VERSION ""

NS_ :

BS_:

BU_: ADSP CH ChassisBus DIPF DIPR ETH FC GTW GTWU HVI HVS ODIN PARTY PartyBus Receiver SDCV SUI UI UIS VEH VIRT VITALS VehicleBus X

BO_ 880 SCS_alertMatrix2: 8 CH
 SG_ SCS_a065_vBatRationalityStage1: 0|1@1+ (1,0) [0|0] "" X
 SG_ SCS_a066_vBatRationalityStage2: 1|1@1+ (1,0) [0|0] "" X
 SG_ SCS_a067_vBatRationalityStage3: 2|1@1+ (1,0) [0|0] "" X
 SG_ SCS_a068_vBatRationalityStage4: 3|1@1+ (1,0) [0|0] "" X
 SG_ SCS_a069_vStageRationalityV1: 4|1@1+ (1,0) [0|0] "" X
 SG_ SCS_a070_vStageRationalityV2: 5|1@1+ (1,0) [0|0] "" X
 SG_ SCS_a071_chargerMIA: 6|1@1+ (1,0) [0|0] "" X
 SG_ SCS_a072_gtwMIA: 7|1@1+ (1,0) [0|0] "" X
 SG_ SCS_a073_lccMIA: 8|1@1+ (1,0) [0|0] "" X
 SG_ SCS_a074_isoVDiffHi: 9|1@1+ (1,0) [0|0] "" X
 SG_ SCS_a075_leakageTestAbsDecayLow: 10|1@1+ (1,0) [0|0] "" X
 SG_ SCS_a076_bmsMIA: 11|1@1+ (1,0) [0|0] "" X
 SG_ SCS_a077_unexpectedVbatBehavior: 12|1@1+ (1,0) [0|0] "" X
 SG_ SCS_a078_voltageMatchTimeout: 13|1@1+ (1,0) [0|0] "" X
 SG_ SCS_a079_unexpectedVbat: 14|1@1+ (1,0) [0|0] "" X
 SG_ SCS_a080_lccFaulted: 15|1@1+ (1,0) [0|0] "" X
 SG_ SCS_a081_rmsInputVoltageHigh: 16|1@1+ (1,0) [0|0] "" X
 SG_ SCS_a082_VbatUV: 17|1@1+ (1,0) [0|0] "" X
 SG_ SCS_a083_chargeCurrentLimited: 18|1@1+ (1,0) [0|0] "" X
 SG_ SCS_a084_unused84: 19|1@1+ (1,0) [0|0] "" X
 SG_ SCS_a085_unused85: 20|1@1+ (1,0) [0|0] "" X
 SG_ SCS_a086_lccResetDetected: 21|1@1+ (1,0) [0|0] "" X
 SG_ SCS_a087_posCordTempRationality: 22|1@1+ (1,0) [0|0] "" X
 SG_ SCS_a088_negCordTempRationality: 23|1@1+ (1,0) [0|0] "" X
 SG_ SCS_a089_posCordOT: 24|1@1+ (1,0) [0|0] "" X
 SG_ SCS_a090_negCordOT: 25|1@1+ (1,0) [0|0] "" X
 SG_ SCS_a091_voltageRiseDetection: 26|1@1+ (1,0) [0|0] "" X
 SG_ SCS_a092_cabEnableDeasserted: 27|1@1+ (1,0) [0|0] "" X
 SG_ SCS_a093_unused93: 28|1@1+ (1,0) [0|0] "" X
 SG_ SCS_a094_unused94: 29|1@1+ (1,0) [0|0] "" X
 SG_ SCS_a095_unused95: 30|1@1+ (1,0) [0|0] "" X
 SG_ SCS_a096_unused96: 31|1@1+ (1,0) [0|0] "" X
 SG_ SCS_a097_unused97: 32|1@1+ (1,0) [0|0] "" X
 SG_ SCS_a098_unused98: 33|1@1+ (1,0) [0|0] "" X
 SG_ SCS_a099_unused99: 34|1@1+ (1,0) [0|0] "" X
 SG_ SCS_a100_unused100: 35|1@1+ (1,0) [0|0] "" X
 SG_ SCS_a101_unused101: 36|1@1+ (1,0) [0|0] "" X
 SG_ SCS_a102_unused102: 37|1@1+ (1,0) [0|0] "" X
 SG_ SCS_a103_unused103: 38|1@1+ (1,0) [0|0] "" X
 SG_ SCS_a104_unused104: 39|1@1+ (1,0) [0|0] "" X
 SG_ SCS_a105_unused105: 40|1@1+ (1,0) [0|0] "" X
 SG_ SCS_a106_unused106: 41|1@1+ (1,0) [0|0] "" X
 SG_ SCS_a107_unused107: 42|1@1+ (1,0) [0|0] "" X
 SG_ SCS_a108_unused108: 43|1@1+ (1,0) [0|0] "" X
 SG_ SCS_a109_unused109: 44|1@1+ (1,0) [0|0] "" X
 SG_ SCS_a110_unused110: 45|1@1+ (1,0) [0|0] "" X
 SG_ SCS_a111_unused111: 46|1@1+ (1,0) [0|0] "" X
 SG_ SCS_a112_unused112: 47|1@1+ (1,0) [0|0] "" X
 SG_ SCS_a113_unused113: 48|1@1+ (1,0) [0|0] "" X
 SG_ SCS_a114_unused114: 49|1@1+ (1,0) [0|0] "" X
 SG_ SCS_a115_unused115: 50|1@1+ (1,0) [0|0] "" X
 SG_ SCS_a116_unused116: 51|1@1+ (1,0) [0|0] "" X
 SG_ SCS_a117_unused117: 52|1@1+ (1,0) [0|0] "" X
 SG_ SCS_a118_unused118: 53|1@1+ (1,0) [0|0] "" X
 SG_ SCS_a119_unused119: 54|1@1+ (1,0) [0|0] "" X
 SG_ SCS_a120_unused120: 55|1@1+ (1,0) [0|0] "" X
 SG_ SCS_a121_unused121: 56|1@1+ (1,0) [0|0] "" X
 SG_ SCS_a122_unused122: 57|1@1+ (1,0) [0|0] "" X
 SG_ SCS_a123_unused123: 58|1@1+ (1,0) [0|0] "" X
 SG_ SCS_a124_unused124: 59|1@1+ (1,0) [0|0] "" X
 SG_ SCS_a125_unused125: 60|1@1+ (1,0) [0|0] "" X
 SG_ SCS_a126_unused126: 61|1@1+ (1,0) [0|0] "" X
 SG_ SCS_a127_unused127: 62|1@1+ (1,0) [0|0] "" X
 SG_ SCS_a128_unused128: 63|1@1+ (1,0) [0|0] "" X

BO_ 881 RCM_alertMatrix: 8 VEH
 SG_ RCM_matrixIndex M: 0|4@1+ (1,0) [0|0] "" X
 SG_ RCM_a000_crashDetected m0: 4|1@1+ (1,0) [0|0] "" X
 SG_ RCM_a001_nearDeploy m0: 5|1@1+ (1,0) [0|0] "" X
 SG_ RCM_a002_airbagsNotArmed m0: 6|1@1+ (1,0) [0|0] "" X
 SG_ RCM_a003_warningIndicator m0: 7|1@1+ (1,0) [0|0] "" X
 SG_ RCM_a004_internalFault m0: 8|1@1+ (1,0) [0|0] "" X
 SG_ RCM_a005_crcError m0: 9|1@1+ (1,0) [0|0] "" X
 SG_ RCM_a006_batteryVoltageRange m0: 10|1@1+ (1,0) [0|0] "" X
 SG_ RCM_a007_powerSupplyExternal m0: 11|1@1+ (1,0) [0|0] "" X
 SG_ RCM_a008_powerSupplyInternal m0: 12|1@1+ (1,0) [0|0] "" X
 SG_ RCM_a009_reprogramLimit m0: 13|1@1+ (1,0) [0|0] "" X
 SG_ RCM_a010_scmDisabled m0: 14|1@1+ (1,0) [0|0] "" X
 SG_ RCM_a011_eepromDataLocked m0: 15|1@1+ (1,0) [0|0] "" X
 SG_ RCM_a012_vinStorage m0: 16|1@1+ (1,0) [0|0] "" X
 SG_ RCM_a013_driverOrientation m0: 17|1@1+ (1,0) [0|0] "" X
 SG_ RCM_a014_driverABStage1 m0: 18|1@1+ (1,0) [0|0] "" X
 SG_ RCM_a015_driverABStage2 m0: 19|1@1+ (1,0) [0|0] "" X
 SG_ RCM_a016_passABStage1 m0: 20|1@1+ (1,0) [0|0] "" X
 SG_ RCM_a017_passABStage2 m0: 21|1@1+ (1,0) [0|0] "" X
 SG_ RCM_a018_passengerActiveVent m0: 22|1@1+ (1,0) [0|0] "" X
 SG_ RCM_a019_pretenShldrFrontLeft m0: 23|1@1+ (1,0) [0|0] "" X
 SG_ RCM_a020_pretenShldFrontRight m0: 24|1@1+ (1,0) [0|0] "" X
 SG_ RCM_a021_pretenLapFrontLeft m0: 25|1@1+ (1,0) [0|0] "" X
 SG_ RCM_a022_pretenLapFrontRight m0: 26|1@1+ (1,0) [0|0] "" X
 SG_ RCM_a023_loadLimiterLeftSide m0: 27|1@1+ (1,0) [0|0] "" X
 SG_ RCM_a024_loadLimiterRightSide m0: 28|1@1+ (1,0) [0|0] "" X
 SG_ RCM_a025_kneeABDriver m0: 29|1@1+ (1,0) [0|0] "" X
 SG_ RCM_a026_kneeABFrontPassenger m0: 30|1@1+ (1,0) [0|0] "" X
 SG_ RCM_a027_sideAB1stRowLeft m0: 31|1@1+ (1,0) [0|0] "" X
 SG_ RCM_a028_sideAB1stRowRight m0: 32|1@1+ (1,0) [0|0] "" X
 SG_ RCM_a029_driverABActiveVent m0: 33|1@1+ (1,0) [0|0] "" X
 SG_ RCM_a030_farSideInboardAirbag m0: 34|1@1+ (1,0) [0|0] "" X
 SG_ RCM_a031_frontCenterAirbag m0: 35|1@1+ (1,0) [0|0] "" X
 SG_ RCM_a032_curtainABLeft m0: 36|1@1+ (1,0) [0|0] "" X
 SG_ RCM_a033_curtainABRight m0: 37|1@1+ (1,0) [0|0] "" X
 SG_ RCM_a034_preten2ndRowLeft m0: 38|1@1+ (1,0) [0|0] "" X
 SG_ RCM_a035_preten2ndRowRight m0: 39|1@1+ (1,0) [0|0] "" X
 SG_ RCM_a036_curAB2ndRowLeft m0: 40|1@1+ (1,0) [0|0] "" X
 SG_ RCM_a037_curAB2ndRowRight m0: 41|1@1+ (1,0) [0|0] "" X
 SG_ RCM_a038_unusedA m0: 42|1@1+ (1,0) [0|0] "" X
 SG_ RCM_a039_unusedB m0: 43|1@1+ (1,0) [0|0] "" X
 SG_ RCM_a040_hoodActuatorRight m0: 44|1@1+ (1,0) [0|0] "" X
 SG_ RCM_a041_hoodActuatorLeft m0: 45|1@1+ (1,0) [0|0] "" X
 SG_ RCM_a042_ens1Line m0: 46|1@1+ (1,0) [0|0] "" X
 SG_ RCM_a043_ens2Line m0: 47|1@1+ (1,0) [0|0] "" X
 SG_ RCM_a044_upFrontSensorLeft m0: 48|1@1+ (1,0) [0|0] "" X
 SG_ RCM_a045_upFrontSensorRight m0: 49|1@1+ (1,0) [0|0] "" X
 SG_ RCM_a046_sideAccelBPillarLeft m0: 50|1@1+ (1,0) [0|0] "" X
 SG_ RCM_a047_sideAccelBPillarRight m0: 51|1@1+ (1,0) [0|0] "" X
 SG_ RCM_a048_sideAccelCPillarLeft m0: 52|1@1+ (1,0) [0|0] "" X
 SG_ RCM_a049_sideAccelCPillarRight m0: 53|1@1+ (1,0) [0|0] "" X
 SG_ RCM_a050_upFrontSensorCenter m0: 54|1@1+ (1,0) [0|0] "" X
 SG_ RCM_a051_pressureFrontLftDoor m0: 55|1@1+ (1,0) [0|0] "" X
 SG_ RCM_a052_pressureFrontRtDoor m0: 56|1@1+ (1,0) [0|0] "" X
 SG_ RCM_a053_pressurePedProLeft m0: 57|1@1+ (1,0) [0|0] "" X
 SG_ RCM_a054_pressurePedProRight m0: 58|1@1+ (1,0) [0|0] "" X
 SG_ RCM_a055_inertialMeasurement m0: 59|1@1+ (1,0) [0|0] "" X
 SG_ RCM_a056_passengerFrontOCS m0: 60|1@1+ (1,0) [0|0] "" X
 SG_ RCM_a057_driverOCS m0: 61|1@1+ (1,0) [0|0] "" X
 SG_ RCM_a058_buckle1stRowLeft m0: 62|1@1+ (1,0) [0|0] "" X
 SG_ RCM_a059_buckle1stRowRight m0: 63|1@1+ (1,0) [0|0] "" X
 SG_ RCM_a060_stpsLeft m1: 4|1@1+ (1,0) [0|0] "" X
 SG_ RCM_a061_stpsRight m1: 5|1@1+ (1,0) [0|0] "" X
 SG_ RCM_a062_alrSwitch m1: 6|1@1+ (1,0) [0|0] "" X
 SG_ RCM_a063_sbsw2ndRowRight m1: 7|1@1+ (1,0) [0|0] "" X
 SG_ RCM_a064_hardwareCodingPin1 m1: 8|1@1+ (1,0) [0|0] "" X
 SG_ RCM_a065_driverOrientConfigPin m1: 9|1@1+ (1,0) [0|0] "" X
 SG_ RCM_a066_seatBackSw2ndRowLeft m1: 10|1@1+ (1,0) [0|0] "" X
 SG_ RCM_a067_comCANInitFailure m1: 11|1@1+ (1,0) [0|0] "" X
 SG_ RCM_a068_comCHOff m1: 12|1@1+ (1,0) [0|0] "" X
 SG_ RCM_a069_comCHCANPH7 m1: 13|1@1+ (1,0) [0|0] "" X
 SG_ RCM_a070_comCHCANPH8 m1: 14|1@1+ (1,0) [0|0] "" X
 SG_ RCM_a071_comCHCANPH9 m1: 15|1@1+ (1,0) [0|0] "" X
 SG_ RCM_a072_comUnused m1: 16|1@1+ (1,0) [0|0] "" X
 SG_ RCM_a073_comCHCANPH4 m1: 17|1@1+ (1,0) [0|0] "" X
 SG_ RCM_a074_comCHCANPH5 m1: 18|1@1+ (1,0) [0|0] "" X
 SG_ RCM_a075_comCHCANPH6 m1: 19|1@1+ (1,0) [0|0] "" X
 SG_ RCM_a076_comEPBLStatus m1: 20|1@1+ (1,0) [0|0] "" X
 SG_ RCM_a077_comEPBRStatus m1: 21|1@1+ (1,0) [0|0] "" X
 SG_ RCM_a078_comOCS1PStatus m1: 22|1@1+ (1,0) [0|0] "" X
 SG_ RCM_a079_comOCS1DStatus m1: 23|1@1+ (1,0) [0|0] "" X
 SG_ RCM_a080_comGTWACS m1: 24|1@1+ (1,0) [0|0] "" X
 SG_ RCM_a081_comVCFRONTLVPwr m1: 25|1@1+ (1,0) [0|0] "" X
 SG_ RCM_a082_comUIodo m1: 26|1@1+ (1,0) [0|0] "" X
 SG_ RCM_a083_comGTWCarState m1: 27|1@1+ (1,0) [0|0] "" X
 SG_ RCM_a084_comTPMSStatus m1: 28|1@1+ (1,0) [0|0] "" X
 SG_ RCM_a085_comGTWCarConfig m1: 29|1@1+ (1,0) [0|0] "" X
 SG_ RCM_a086_comVINMIA m1: 30|1@1+ (1,0) [0|0] "" X
 SG_ RCM_a087_comCANSilent m1: 31|1@1+ (1,0) [0|0] "" X
 SG_ RCM_a088_comCHCANPH2 m1: 32|1@1+ (1,0) [0|0] "" X
 SG_ RCM_a089_comCHCANPH3 m1: 33|1@1+ (1,0) [0|0] "" X
 SG_ RCM_a090_comPartyBusOff m1: 34|1@1+ (1,0) [0|0] "" X
 SG_ RCM_a091_comEPAS3PsysStatus m1: 35|1@1+ (1,0) [0|0] "" X
 SG_ RCM_a092_comDASISF m1: 36|1@1+ (1,0) [0|0] "" X
 SG_ RCM_a093_comVCLEFTStatus m1: 37|1@1+ (1,0) [0|0] "" X
 SG_ RCM_a094_comVCRIGHTStatus m1: 38|1@1+ (1,0) [0|0] "" X
 SG_ RCM_a095_comESPstatus m1: 39|1@1+ (1,0) [0|0] "" X
 SG_ RCM_a096_comESPwheelSpeeds m1: 40|1@1+ (1,0) [0|0] "" X
 SG_ RCM_a097_comDIspeed m1: 41|1@1+ (1,0) [0|0] "" X
 SG_ RCM_a098_comDIchassisControl m1: 42|1@1+ (1,0) [0|0] "" X
 SG_ RCM_a099_comDItorque m1: 43|1@1+ (1,0) [0|0] "" X
 SG_ RCM_a100_comDIsystemStatus m1: 44|1@1+ (1,0) [0|0] "" X
 SG_ RCM_a101_idfSystem m1: 45|1@1+ (1,0) [0|0] "" X
 SG_ RCM_a102_imuYawR8OffstCompLim m1: 46|1@1+ (1,0) [0|0] "" X
 SG_ RCM_a103_imuPtchR8OffstCompLim m1: 47|1@1+ (1,0) [0|0] "" X
 SG_ RCM_a104_imuRollR8OffstCompLim m1: 48|1@1+ (1,0) [0|0] "" X
 SG_ RCM_a105_imuLongAccOffstCompLim m1: 49|1@1+ (1,0) [0|0] "" X
 SG_ RCM_a106_imuLatAccOffstCompLim m1: 50|1@1+ (1,0) [0|0] "" X
 SG_ RCM_a107_imuVertAccOffstCompLim m1: 51|1@1+ (1,0) [0|0] "" X
 SG_ RCM_a108_crashAlgoWakeup m1: 52|1@1+ (1,0) [0|0] "" X
 SG_ RCM_a109_abuseImmunity m1: 53|1@1+ (1,0) [0|0] "" X
 SG_ RCM_a110_factoryMode m1: 54|1@1+ (1,0) [0|0] "" X
 SG_ RCM_a111_diagnosticsEnabled m1: 55|1@1+ (1,0) [0|0] "" X
 SG_ RCM_a112_imuYawRate m1: 56|1@1+ (1,0) [0|0] "" X
 SG_ RCM_a113_imuPitchRate m1: 57|1@1+ (1,0) [0|0] "" X
 SG_ RCM_a114_imuRollRate m1: 58|1@1+ (1,0) [0|0] "" X
 SG_ RCM_a115_imuLinearAcceleration m1: 59|1@1+ (1,0) [0|0] "" X
 SG_ RCM_a116_imuLateralAcceleration m1: 60|1@1+ (1,0) [0|0] "" X
 SG_ RCM_a117_imuVerticalAcceleration m1: 61|1@1+ (1,0) [0|0] "" X
 SG_ RCM_a118_imuInPlaneAcceleration m1: 62|1@1+ (1,0) [0|0] "" X

BO_ 882 EPAS3S_sysStatus: 8 GTW
 SG_ EPAS3S_torsionBarTorque : 20|12@0+ (0.01,-20.5) [-20.5|20.45] "Nm" ODIN

BO_ 883 EPAS3P_sysStatus: 8 GTW
 SG_ EPAS3P_internalSAS : 34|14@0+ (0.1,-819.2) [-819.2|819] "deg" ODIN
 SG_ EPAS3P_torsionBarTorque : 20|12@0+ (0.01,-20.5) [-20.5|20.45] "Nm" ODIN

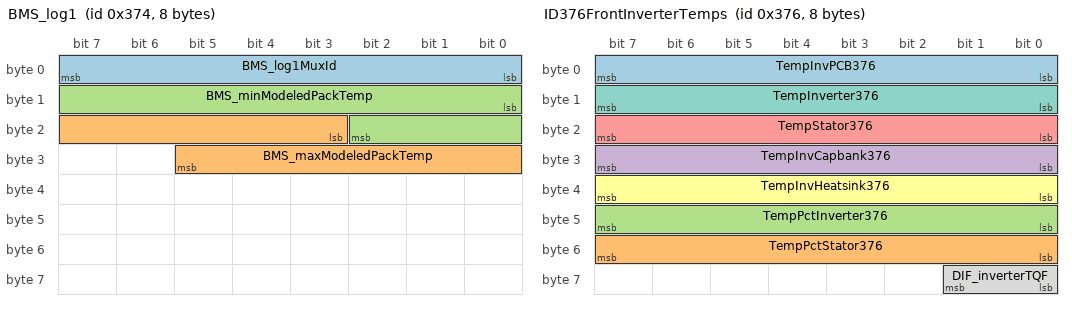
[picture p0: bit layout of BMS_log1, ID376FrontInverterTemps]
BO_ 884 BMS_log1: 8 GTW
 SG_ BMS_log1MuxId : 0|8@1+ (1,0) [0|27] "" XXX
 SG_ BMS_maxModeledPackTemp : 19|11@1+ (0.1,-50) [-50|154.7] "C" ODIN
 SG_ BMS_minModeledPackTemp : 8|11@1+ (0.1,-50) [-50|154.7] "C" ODIN

BO_ 886 ID376FrontInverterTemps: 8 VehicleBus
 SG_ TempInvPCB376 : 0|8@1+ (1,-40) [-40|215] "C"  Receiver
 SG_ TempPctStator376 : 48|8@1+ (0.4,0) [0|102] "%"  Receiver
 SG_ TempPctInverter376 : 40|8@1+ (0.4,0) [0|102] "%"  Receiver
 SG_ TempInvCapbank376 : 24|8@1+ (1,-40) [-40|215] "C"  Receiver
 SG_ TempStator376 : 16|8@1+ (1,-40) [-40|215] "C"  Receiver
 SG_ TempInvHeatsink376 : 32|8@1+ (1,-40) [-40|215] "C"  Receiver
 SG_ TempInverter376 : 8|8@1+ (1,-40) [-40|215] "C"  Receiver
 SG_ DIF_inverterTQF : 56|2@1+ (1,0) [0|3] ""  Receiver

BO_ 888 GTW_ECall: 1 VEH
 SG_ GTW_GSM_ECALL_nLOCK: 0|1@1+ (1,0) [0|0] "" X

BO_ 890 DAS_telemetryPeriodic: 8 VEH
 SG_ DAS_TP_multiplexer M: 0|5@1+ (1,0) [0|0] "" X
 SG_ DAS_TP_counter m0: 5|3@1+ (1,0) [0|0] "" X
 SG_ DAS_TP_vlWidth m0: 8|8@1+ (0.05,0) [0|0] "m" X
 SG_ DAS_TP_hppError m0: 16|6@1+ (0.05,0) [0|0] "m" X
 SG_ DAS_TP_wipersActive m0: 22|1@1+ (1,0) [0|0] "" X
 SG_ DAS_TP_handsOn m0: 23|1@1+ (1,0) [0|0] "" X
 SG_ DAS_TP_sonicDistL m0: 24|9@1+ (0.01,0) [0|0] "m" X
 SG_ DAS_TP_sonicDistR m0: 33|9@1+ (0.01,0) [0|0] "m" X
 SG_ DAS_TP_hppValid m0: 42|1@1+ (1,0) [0|0] "" X
 SG_ DAS_TP_restrictedAccess m0: 43|1@1+ (1,0) [0|0] "" X
 SG_ DAS_TP_vehFuse m0: 44|1@1+ (1,0) [0|0] "" X
 SG_ DAS_TP_accRestricted m0: 46|1@1+ (1,0) [0|0] "" X
 SG_ DAS_TP_laneChange m0: 48|2@1+ (1,0) [0|0] "" X
 SG_ DAS_TP_llType m0: 50|3@1+ (1,0) [0|0] "" X
 SG_ DAS_TP_rlType m0: 53|3@1+ (1,0) [0|0] "" X
 SG_ DAS_TP_plannerState m0: 56|4@1+ (1,0) [0|0] "" X
 SG_ DAS_TP_lcState m0: 60|4@1+ (1,0) [0|0] "" X
 SG_ DAS_TP_llCounter m1: 5|3@1+ (1,0) [0|0] "" X
 SG_ DAS_TP_llC0 m1: 8|10@1- (0.02,0) [0|0] "m" X
 SG_ DAS_TP_llC1 m1: 18|9@1- (0.00195313,0) [0|0] "rad" X
 SG_ DAS_TP_llC2 m1: 27|14@1- (4e-06,0) [0|0] "1/m" X
 SG_ DAS_TP_llC3 m1: 41|14@1- (1.6e-08,0) [0|0] "1/m2" X
 SG_ DAS_TP_llQlty m1: 55|1@1+ (1,0) [0|0] "" X
 SG_ DAS_TP_llRange m1: 56|7@1+ (1,0) [0|0] "m" X
 SG_ DAS_TP_llFuse m1: 63|1@1+ (1,0) [0|0] "" X
 SG_ DAS_TP_rlCounter m2: 5|3@1+ (1,0) [0|0] "" X
 SG_ DAS_TP_rlC0 m2: 8|10@1- (0.02,0) [0|0] "m" X
 SG_ DAS_TP_rlC1 m2: 18|9@1- (0.00195313,0) [0|0] "rad" X
 SG_ DAS_TP_rlC2 m2: 27|14@1- (4e-06,0) [0|0] "1/m" X
 SG_ DAS_TP_rlC3 m2: 41|14@1- (1.6e-08,0) [0|0] "1/m2" X
 SG_ DAS_TP_rlQlty m2: 55|1@1+ (1,0) [0|0] "" X
 SG_ DAS_TP_rlRange m2: 56|7@1+ (1,0) [0|0] "m" X
 SG_ DAS_TP_rlFuse m2: 63|1@1+ (1,0) [0|0] "" X
 SG_ DAS_TP_hppCounter m3: 5|3@1+ (1,0) [0|0] "" X
 SG_ DAS_TP_hppC0 m3: 8|10@1- (0.02,0) [0|0] "m" X
 SG_ DAS_TP_hppC1 m3: 18|9@1- (0.00195313,0) [0|0] "rad" X
 SG_ DAS_TP_hppC2 m3: 27|14@1- (4e-06,0) [0|0] "1/m" X
 SG_ DAS_TP_hppC3 m3: 41|14@1- (1.6e-08,0) [0|0] "1/m2" X
 SG_ DAS_TP_hppQlty m3: 55|1@1+ (1,0) [0|0] "" X
 SG_ DAS_TP_hppRange m3: 56|7@1+ (1,0) [0|0] "m" X
 SG_ DAS_TP_hppFuse m3: 63|1@1+ (1,0) [0|0] "" X
 SG_ DAS_TP_navCounter m4: 5|3@1+ (1,0) [0|0] "" X
 SG_ DAS_TP_navC0 m4: 8|10@1- (0.02,0) [0|0] "m" X
 SG_ DAS_TP_navC1 m4: 18|9@1- (0.00195313,0) [0|0] "rad" X
 SG_ DAS_TP_navC2 m4: 27|14@1- (4e-06,0) [0|0] "1/m" X
 SG_ DAS_TP_navC3 m4: 41|14@1- (1.6e-08,0) [0|0] "1/m2" X
 SG_ DAS_TP_navQlty m4: 55|1@1+ (1,0) [0|0] "" X
 SG_ DAS_TP_navRange m4: 56|7@1+ (1,0) [0|0] "m" X
 SG_ DAS_TP_navFuse m4: 63|1@1+ (1,0) [0|0] "" X
 SG_ DAS_TP_vlCounter m5: 5|3@1+ (1,0) [0|0] "" X
 SG_ DAS_TP_vlC0 m5: 8|10@1- (0.02,0) [0|0] "m" X
 SG_ DAS_TP_vlC1 m5: 18|9@1- (0.00195313,0) [0|0] "rad" X
 SG_ DAS_TP_vlC2 m5: 27|14@1- (4e-06,0) [0|0] "1/m" X
 SG_ DAS_TP_vlC3 m5: 41|14@1- (1.6e-08,0) [0|0] "1/m2" X
 SG_ DAS_TP_vlQlty m5: 55|1@1+ (1,0) [0|0] "" X
 SG_ DAS_TP_vlRange m5: 56|7@1+ (1,0) [0|0] "m" X
 SG_ DAS_TP_vlFuse m5: 63|1@1+ (1,0) [0|0] "" X
 SG_ DAS_TP_bdlCounter m6: 5|3@1+ (1,0) [0|0] "" X
 SG_ DAS_TP_bdlC0 m6: 8|10@1- (0.02,0) [0|0] "m" X
 SG_ DAS_TP_bdlC1 m6: 18|9@1- (0.00195313,0) [0|0] "rad" X
 SG_ DAS_TP_bdlC2 m6: 27|14@1- (4e-06,0) [0|0] "1/m" X
 SG_ DAS_TP_bdlC3 m6: 41|14@1- (1.6e-08,0) [0|0] "1/m2" X
 SG_ DAS_TP_bdlQlty m6: 55|1@1+ (1,0) [0|0] "" X
 SG_ DAS_TP_bdlRange m6: 56|7@1+ (1,0) [0|0] "m" X
 SG_ DAS_TP_bdlFuse m6: 63|1@1+ (1,0) [0|0] "" X
 SG_ DAS_TP_bdrCounter m7: 5|3@1+ (1,0) [0|0] "" X
 SG_ DAS_TP_bdrC0 m7: 8|10@1- (0.02,0) [0|0] "m" X
 SG_ DAS_TP_bdrC1 m7: 18|9@1- (0.00195313,0) [0|0] "rad" X
 SG_ DAS_TP_bdrC2 m7: 27|14@1- (4e-06,0) [0|0] "1/m" X
 SG_ DAS_TP_bdrC3 m7: 41|14@1- (1.6e-08,0) [0|0] "1/m2" X
 SG_ DAS_TP_bdrQlty m7: 55|1@1+ (1,0) [0|0] "" X
 SG_ DAS_TP_bdrRange m7: 56|7@1+ (1,0) [0|0] "m" X
 SG_ DAS_TP_bdrFuse m7: 63|1@1+ (1,0) [0|0] "" X
 SG_ DAS_TP_laneCounter m8: 5|3@1+ (1,0) [0|0] "" X
 SG_ DAS_TP_llSegQ1 m8: 8|4@1+ (10,0) [0|0] "%" X
 SG_ DAS_TP_llSegQ2 m8: 12|4@1+ (10,0) [0|0] "%" X
 SG_ DAS_TP_llSegQ3 m8: 16|4@1+ (10,0) [0|0] "%" X
 SG_ DAS_TP_llSegQ4 m8: 20|4@1+ (10,0) [0|0] "%" X
 SG_ DAS_TP_rlSegQ1 m8: 24|4@1+ (10,0) [0|0] "%" X
 SG_ DAS_TP_rlSegQ2 m8: 28|4@1+ (10,0) [0|0] "%" X
 SG_ DAS_TP_rlSegQ3 m8: 32|4@1+ (10,0) [0|0] "%" X
 SG_ DAS_TP_rlSegQ4 m8: 36|4@1+ (10,0) [0|0] "%" X
 SG_ DAS_TP_llExist m8: 40|4@1+ (10,0) [0|0] "%" X
 SG_ DAS_TP_rlExist m8: 44|4@1+ (10,0) [0|0] "%" X
 SG_ DAS_TP_nllProb m8: 48|4@1+ (0.1,0) [0|0] "1" X
 SG_ DAS_TP_nrlProb m8: 52|4@1+ (0.1,0) [0|0] "1" X
 SG_ DAS_TP_llQltyME m8: 56|2@1+ (1,0) [0|0] "" X
 SG_ DAS_TP_rlQltyME m8: 58|2@1+ (1,0) [0|0] "" X
 SG_ DAS_TP_bdlQltyME m8: 60|2@1+ (1,0) [0|0] "" X
 SG_ DAS_TP_bdrQltyME m8: 62|2@1+ (1,0) [0|0] "" X
 SG_ DAS_TP_llrCounter m9: 5|3@1+ (1,0) [0|0] "" X
 SG_ DAS_TP_numLanes m9: 8|3@1+ (1,0) [0|0] "" X
 SG_ DAS_TP_lane1LLR m9: 11|6@1+ (0.3125,-10) [0|0] "1" X
 SG_ DAS_TP_lane2LLR m9: 17|6@1+ (0.3125,-10) [0|0] "1" X
 SG_ DAS_TP_lane3LLR m9: 23|6@1+ (0.3125,-10) [0|0] "1" X
 SG_ DAS_TP_lane4LLR m9: 29|6@1+ (0.3125,-10) [0|0] "1" X
 SG_ DAS_TP_lane5LLR m9: 35|6@1+ (0.3125,-10) [0|0] "1" X
 SG_ DAS_TP_lane6LLR m9: 41|6@1+ (0.3125,-10) [0|0] "1" X
 SG_ DAS_TP_lane7LLR m9: 47|6@1+ (0.3125,-10) [0|0] "1" X
 SG_ DAS_TP_lane8LLR m9: 53|6@1+ (0.3125,-10) [0|0] "1" X
 SG_ DAS_TP_egoLane m9: 59|3@1+ (1,0) [0|0] "" X

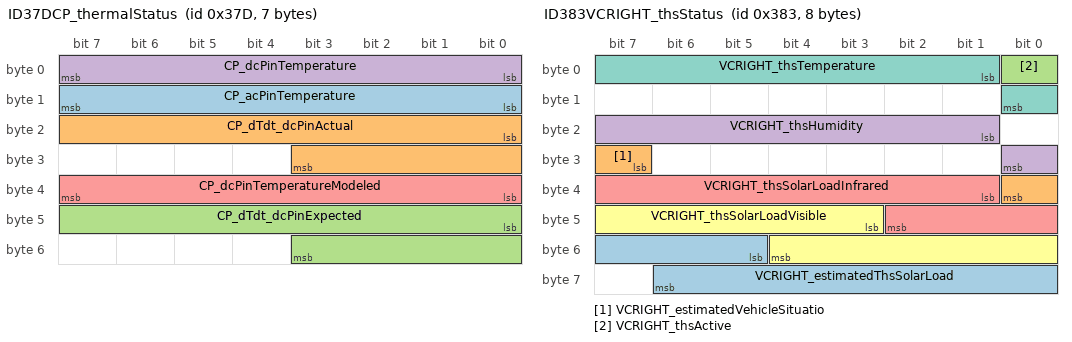
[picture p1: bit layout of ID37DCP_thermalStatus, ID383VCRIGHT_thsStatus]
BO_ 893 ID37DCP_thermalStatus: 7 VehicleBus
 SG_ CP_acPinTemperature : 8|8@1+ (0.803922,-55) [-55|149.99] "C"  Receiver
 SG_ CP_dTdt_dcPinActual : 16|12@1+ (0.005,-10) [-10|10] "C"  Receiver
 SG_ CP_dTdt_dcPinExpected : 40|12@1+ (0.005,-10) [-10|10] "C"  Receiver
 SG_ CP_dcPinTemperature : 0|8@1+ (0.803922,-55) [-55|149.99] "C"  Receiver
 SG_ CP_dcPinTemperatureModeled : 32|8@1+ (0.803922,-55) [-55|149.99] "C"  Receiver

BO_ 894 PARK_warningMatrix: 8 CH
 SG_ PARK_matrixIndex M: 0|4@1+ (1,0) [0|0] "" X
 SG_ PARK_a001_s1_overTemp m0: 4|1@1+ (1,0) [0|0] "" X
 SG_ PARK_a002_s1_internalFail m0: 5|1@1+ (1,0) [0|0] "" X
 SG_ PARK_a003_s1_linCommError m0: 6|1@1+ (1,0) [0|0] "" X
 SG_ PARK_a004_s1_blocked m0: 7|1@1+ (1,0) [0|0] "" X
 SG_ PARK_a005_s1_crossTalk m0: 8|1@1+ (1,0) [0|0] "" X
 SG_ PARK_a006_s2_overTemp m0: 9|1@1+ (1,0) [0|0] "" X
 SG_ PARK_a007_s2_internalFail m0: 10|1@1+ (1,0) [0|0] "" X
 SG_ PARK_a008_s2_linCommError m0: 11|1@1+ (1,0) [0|0] "" X
 SG_ PARK_a009_s2_blocked m0: 12|1@1+ (1,0) [0|0] "" X
 SG_ PARK_a010_s2_crossTalk m0: 13|1@1+ (1,0) [0|0] "" X
 SG_ PARK_a011_s3_overTemp m0: 14|1@1+ (1,0) [0|0] "" X
 SG_ PARK_a012_s3_internalFail m0: 15|1@1+ (1,0) [0|0] "" X
 SG_ PARK_a013_s3_linCommError m0: 16|1@1+ (1,0) [0|0] "" X
 SG_ PARK_a014_s3_blocked m0: 17|1@1+ (1,0) [0|0] "" X
 SG_ PARK_a015_s3_crossTalk m0: 18|1@1+ (1,0) [0|0] "" X
 SG_ PARK_a016_s4_overTemp m0: 19|1@1+ (1,0) [0|0] "" X
 SG_ PARK_a017_s4_internalFail m0: 20|1@1+ (1,0) [0|0] "" X
 SG_ PARK_a018_s4_linCommError m0: 21|1@1+ (1,0) [0|0] "" X
 SG_ PARK_a019_s4_blocked m0: 22|1@1+ (1,0) [0|0] "" X
 SG_ PARK_a020_s4_crossTalk m0: 23|1@1+ (1,0) [0|0] "" X
 SG_ PARK_a021_s5_overTemp m0: 24|1@1+ (1,0) [0|0] "" X
 SG_ PARK_a022_s5_internalFail m0: 25|1@1+ (1,0) [0|0] "" X
 SG_ PARK_a023_s5_linCommError m0: 26|1@1+ (1,0) [0|0] "" X
 SG_ PARK_a024_s5_blocked m0: 27|1@1+ (1,0) [0|0] "" X
 SG_ PARK_a025_s5_crossTalk m0: 28|1@1+ (1,0) [0|0] "" X
 SG_ PARK_a026_s6_overTemp m0: 29|1@1+ (1,0) [0|0] "" X
 SG_ PARK_a027_s6_internalFail m0: 30|1@1+ (1,0) [0|0] "" X
 SG_ PARK_a028_s6_linCommError m0: 31|1@1+ (1,0) [0|0] "" X
 SG_ PARK_a029_s6_blocked m0: 32|1@1+ (1,0) [0|0] "" X
 SG_ PARK_a030_s6_crossTalk m0: 33|1@1+ (1,0) [0|0] "" X
 SG_ PARK_a031_s7_overTemp m0: 34|1@1+ (1,0) [0|0] "" X
 SG_ PARK_a032_s7_internalFail m0: 35|1@1+ (1,0) [0|0] "" X
 SG_ PARK_a033_s7_linCommError m0: 36|1@1+ (1,0) [0|0] "" X
 SG_ PARK_a034_s7_blocked m0: 37|1@1+ (1,0) [0|0] "" X
 SG_ PARK_a035_s7_crossTalk m0: 38|1@1+ (1,0) [0|0] "" X
 SG_ PARK_a036_s8_overTemp m0: 39|1@1+ (1,0) [0|0] "" X
 SG_ PARK_a037_s8_internalFail m0: 40|1@1+ (1,0) [0|0] "" X
 SG_ PARK_a038_s8_linCommError m0: 41|1@1+ (1,0) [0|0] "" X
 SG_ PARK_a039_s8_blocked m0: 42|1@1+ (1,0) [0|0] "" X
 SG_ PARK_a040_s8_crossTalk m0: 43|1@1+ (1,0) [0|0] "" X
 SG_ PARK_a041_s9_overTemp m0: 44|1@1+ (1,0) [0|0] "" X
 SG_ PARK_a042_s9_internalFail m0: 45|1@1+ (1,0) [0|0] "" X
 SG_ PARK_a043_s9_linCommError m0: 46|1@1+ (1,0) [0|0] "" X
 SG_ PARK_a044_s9_blocked m0: 47|1@1+ (1,0) [0|0] "" X
 SG_ PARK_a045_s9_crossTalk m0: 48|1@1+ (1,0) [0|0] "" X
 SG_ PARK_a046_s10_overTemp m0: 49|1@1+ (1,0) [0|0] "" X
 SG_ PARK_a047_s10_internalFail m0: 50|1@1+ (1,0) [0|0] "" X
 SG_ PARK_a048_s10_linCommError m0: 51|1@1+ (1,0) [0|0] "" X
 SG_ PARK_a049_s10_blocked m0: 52|1@1+ (1,0) [0|0] "" X
 SG_ PARK_a050_s10_crossTalk m0: 53|1@1+ (1,0) [0|0] "" X
 SG_ PARK_a051_s11_overTemp m0: 54|1@1+ (1,0) [0|0] "" X
 SG_ PARK_a052_s11_internalFail m0: 55|1@1+ (1,0) [0|0] "" X
 SG_ PARK_a053_s11_linCommError m0: 56|1@1+ (1,0) [0|0] "" X
 SG_ PARK_a054_s11_blocked m0: 57|1@1+ (1,0) [0|0] "" X
 SG_ PARK_a055_s11_crossTalk m0: 58|1@1+ (1,0) [0|0] "" X
 SG_ PARK_a056_s12_overTemp m0: 59|1@1+ (1,0) [0|0] "" X
 SG_ PARK_a057_s12_internalFail m0: 60|1@1+ (1,0) [0|0] "" X
 SG_ PARK_a058_s12_linCommError m0: 61|1@1+ (1,0) [0|0] "" X
 SG_ PARK_a059_s12_blocked m0: 62|1@1+ (1,0) [0|0] "" X
 SG_ PARK_a060_s12_crossTalk m0: 63|1@1+ (1,0) [0|0] "" X
 SG_ PARK_a061_ecuUnderVoltage m1: 4|1@1+ (1,0) [0|0] "" X
 SG_ PARK_a062_ecuOverVoltage m1: 5|1@1+ (1,0) [0|0] "" X
 SG_ PARK_a063_sensorVoltage m1: 6|1@1+ (1,0) [0|0] "" X
 SG_ PARK_a064_ecuFault m1: 7|1@1+ (1,0) [0|0] "" X
 SG_ PARK_a065_crcFault m1: 8|1@1+ (1,0) [0|0] "" X
 SG_ PARK_a066_calibrationMissing m1: 9|1@1+ (1,0) [0|0] "" X
 SG_ PARK_a067_privateCANBusOff m1: 10|1@1+ (1,0) [0|0] "" X
 SG_ PARK_a068_hardwareWatchDog m1: 11|1@1+ (1,0) [0|0] "" X
 SG_ PARK_a069_dasMia m1: 12|1@1+ (1,0) [0|0] "" X
 SG_ PARK_a070_sccmMia m1: 13|1@1+ (1,0) [0|0] "" X
 SG_ PARK_a071_diMia m1: 14|1@1+ (1,0) [0|0] "" X
 SG_ PARK_a072_epasMia m1: 15|1@1+ (1,0) [0|0] "" X
 SG_ PARK_a073_epbMia m1: 16|1@1+ (1,0) [0|0] "" X
 SG_ PARK_a074_espMia m1: 17|1@1+ (1,0) [0|0] "" X
 SG_ PARK_a075_rcmMia m1: 18|1@1+ (1,0) [0|0] "" X
 SG_ PARK_a076_vcFrontMia m1: 19|1@1+ (1,0) [0|0] "" X
 SG_ PARK_a077_dasError m1: 20|1@1+ (1,0) [0|0] "" X
 SG_ PARK_a078_diError m1: 21|1@1+ (1,0) [0|0] "" X
 SG_ PARK_a079_epasError m1: 22|1@1+ (1,0) [0|0] "" X
 SG_ PARK_a080_epbError m1: 23|1@1+ (1,0) [0|0] "" X
 SG_ PARK_a081_espError m1: 24|1@1+ (1,0) [0|0] "" X
 SG_ PARK_a082_rcmError m1: 25|1@1+ (1,0) [0|0] "" X
 SG_ PARK_a083_vcFrontError m1: 26|1@1+ (1,0) [0|0] "" X
 SG_ PARK_a084_sccmError m1: 27|1@1+ (1,0) [0|0] "" X
 SG_ PARK_a085_watchdogReset m1: 28|1@1+ (1,0) [0|0] "" X
 SG_ PARK_a086_nvmFault m1: 29|1@1+ (1,0) [0|0] "" X

BO_ 895 FC_alertMatrix3: 8 VEH
 SG_ FC_a129_CA_flyback_HW_OC: 0|1@1+ (1,0) [0|0] "" X
 SG_ FC_a130_CA_flyback_SW_OV: 1|1@1+ (1,0) [0|0] "" X
 SG_ FC_a131_CA_flyback_HW_OV: 2|1@1+ (1,0) [0|0] "" X
 SG_ FC_a132_CA_bmsMia: 3|1@1+ (1,0) [0|0] "" X
 SG_ FC_a133_CA_evseMia: 4|1@1+ (1,0) [0|0] "" X
 SG_ FC_a134_CA_vehTxBufOvf: 5|1@1+ (1,0) [0|0] "" X
 SG_ FC_a135_CA_vehRxBufOvf: 6|1@1+ (1,0) [0|0] "" X
 SG_ FC_a136_CA_evseTxBufOvf: 7|1@1+ (1,0) [0|0] "" X
 SG_ FC_a137_CA_evseRxBufOvf: 8|1@1+ (1,0) [0|0] "" X
 SG_ FC_a138_CA_hwProxTrip: 9|1@1+ (1,0) [0|0] "" X
 SG_ FC_a139_CA_ss2NotLow: 10|1@1+ (1,0) [0|0] "" X
 SG_ FC_a140_CA_bmsIncompatible: 11|1@1+ (1,0) [0|0] "" X
 SG_ FC_a141_CA_vehConn_OT: 12|1@1+ (1,0) [0|0] "" X
 SG_ FC_a142_CA_evseConn_OT: 13|1@1+ (1,0) [0|0] "" X
 SG_ FC_a143_CA_pcb_OT: 14|1@1+ (1,0) [0|0] "" X
 SG_ FC_a144_CA_flybackUnstable: 15|1@1+ (1,0) [0|0] "" X
 SG_ FC_a145_CA_flybackDataStale: 16|1@1+ (1,0) [0|0] "" X
 SG_ FC_a146_CA_flybackBusLoadHi: 17|1@1+ (1,0) [0|0] "" X
 SG_ FC_a147_CA_vehConn_UT: 18|1@1+ (1,0) [0|0] "" X
 SG_ FC_a148_CA_evseConn_UT: 19|1@1+ (1,0) [0|0] "" X
 SG_ FC_a149_CA_pcb_UT: 20|1@1+ (1,0) [0|0] "" X
 SG_ FC_a150_CA_vehToEvseDeltaHi: 21|1@1+ (1,0) [0|0] "" X
 SG_ FC_a151_CA_vehToEvseDeltaLo: 22|1@1+ (1,0) [0|0] "" X
 SG_ FC_a152_CA_vehToPcbDeltaHi: 23|1@1+ (1,0) [0|0] "" X
 SG_ FC_a153_CA_evseToPcbDeltaHi: 24|1@1+ (1,0) [0|0] "" X
 SG_ FC_a154_CA_vehToPcbDeltaLo: 25|1@1+ (1,0) [0|0] "" X
 SG_ FC_a155_CA_evseToPcbDeltaLo: 26|1@1+ (1,0) [0|0] "" X
 SG_ FC_a156_CA_flybackRunTimeout: 27|1@1+ (1,0) [0|0] "" X
 SG_ FC_a157_CA_unused: 28|1@1+ (1,0) [0|0] "" X
 SG_ FC_a158_CA_evseOverCurrent: 29|1@1+ (1,0) [0|0] "" X
 SG_ FC_a159_CA_wdtExpired: 30|1@1+ (1,0) [0|0] "" X
 SG_ FC_a160_CA_ss2Deasserted: 31|1@1+ (1,0) [0|0] "" X
 SG_ FC_a161_CA_vehTempHiFoldBk: 32|1@1+ (1,0) [0|0] "" X
 SG_ FC_a162_CA_evseTempHiFoldBk: 33|1@1+ (1,0) [0|0] "" X
 SG_ FC_a163_CA_pcbTempHiFoldBk: 34|1@1+ (1,0) [0|0] "" X
 SG_ FC_a164_CA_proxDisconnected: 35|1@1+ (1,0) [0|0] "" X
 SG_ FC_a165_CA_evseConnUnlocked: 36|1@1+ (1,0) [0|0] "" X
 SG_ FC_a166_CA_vehConnUnlocked: 37|1@1+ (1,0) [0|0] "" X
 SG_ FC_a167_CA_isoVoltageLow: 38|1@1+ (1,0) [0|0] "" X
 SG_ FC_a168_CA_proxTimeout: 39|1@1+ (1,0) [0|0] "" X
 SG_ FC_a169_CA_pilotAcceptTimeout: 40|1@1+ (1,0) [0|0] "" X
 SG_ FC_a170_CA_vehDataTimeout: 41|1@1+ (1,0) [0|0] "" X
 SG_ FC_a171_CA_vehConLockTimeout: 42|1@1+ (1,0) [0|0] "" X
 SG_ FC_a172_CA_ss2LowTimeout: 43|1@1+ (1,0) [0|0] "" X
 SG_ FC_a173_CA_evseDataTimeout: 44|1@1+ (1,0) [0|0] "" X
 SG_ FC_a174_CA_vehReadyTimeout: 45|1@1+ (1,0) [0|0] "" X
 SG_ FC_a175_CA_evseIsoTestTimeout: 46|1@1+ (1,0) [0|0] "" X
 SG_ FC_a176_CA_chargingBusTimeout: 47|1@1+ (1,0) [0|0] "" X
 SG_ FC_a177_CA_bmsCtrCloseTimeout: 48|1@1+ (1,0) [0|0] "" X
 SG_ FC_a178_CA_evseStartTimeout: 49|1@1+ (1,0) [0|0] "" X
 SG_ FC_a179_CA_startupProblem: 50|1@1+ (1,0) [0|0] "" X
 SG_ FC_a180_CA_chargingProblem: 51|1@1+ (1,0) [0|0] "" X
 SG_ FC_a181_CA_vRegBrownout: 52|1@1+ (1,0) [0|0] "" X
 SG_ FC_a182_CA_evseChrMalfunc: 53|1@1+ (1,0) [0|0] "" X
 SG_ FC_a183_CA_evseBatIncompat: 54|1@1+ (1,0) [0|0] "" X
 SG_ FC_a184_CA_evseBatMalfunc: 55|1@1+ (1,0) [0|0] "" X
 SG_ FC_a185_CA_vehReadyDeasserted: 56|1@1+ (1,0) [0|0] "" X
 SG_ FC_a186_CA_fcContOpenTimeout: 57|1@1+ (1,0) [0|0] "" X
 SG_ FC_a187_CA_evseConLockTimeout: 58|1@1+ (1,0) [0|0] "" X

BO_ 897 ID381VCFRONT_logging1Hz: 8 VehicleBus
 SG_ VCFRONT_logging1HzIndex M : 0|5@1+ (1,0) [0|19] ""  Receiver
 SG_ VCFRONT_CCQdotActual m9 : 21|7@1+ (80,0) [0|10100] "W"  Receiver
 SG_ VCFRONT_CCQdotFdFrwrdTarget m9 : 7|7@1+ (80,0) [0|10100] "W"  Receiver
 SG_ VCFRONT_CCQdotFdbk m9 : 14|7@1- (80,0) [-5000|5000] "W"  Receiver
 SG_ VCFRONT_CMPDischargeSuperheat m8 : 17|5@1- (1,6) [-10|21] "C"  Receiver
 SG_ VCFRONT_DIQdotA m9 : 42|7@1+ (80,0) [0|10000] "W"  Receiver
 SG_ VCFRONT_HCML_bladeTemp m3 : 32|8@1- (1,67) [-60|194] "C"  Receiver
 SG_ VCFRONT_HCML_diffuseTemp m3 : 40|8@1- (1,67) [-60|194] "C"  Receiver
 SG_ VCFRONT_HCML_highBeamTemp m3 : 16|8@1- (1,67) [-60|194] "C"  Receiver
 SG_ VCFRONT_HCML_lowBeamSpotTemp m3 : 8|8@1- (1,67) [-60|194] "C"  Receiver
 SG_ VCFRONT_HCML_turnTemp m3 : 24|8@1- (1,67) [-60|194] "C"  Receiver
 SG_ VCFRONT_HCMR_bladeTemp m4 : 32|8@1- (1,67) [-60|194] "C"  Receiver
 SG_ VCFRONT_HCMR_diffuseTemp m4 : 40|8@1- (1,67) [-60|194] "C"  Receiver
 SG_ VCFRONT_HCMR_highBeamTemp m4 : 16|8@1- (1,67) [-60|194] "C"  Receiver
 SG_ VCFRONT_HCMR_lowBeamSpotTemp m4 : 8|8@1- (1,67) [-60|194] "C"  Receiver
 SG_ VCFRONT_HCMR_turnTemp m4 : 24|8@1- (1,67) [-60|194] "C"  Receiver
 SG_ VCFRONT_PDischargeControllerOutp m14 : 24|8@1+ (0.5,0) [0|100] "%"  Receiver
 SG_ VCFRONT_PSuctionControllerOutput m14 : 40|8@1+ (0.5,0) [0|100] "%"  Receiver
 SG_ VCFRONT_ambientColderThanBatt m16 : 8|1@1+ (1,0) [0|1] ""  Receiver
 SG_ VCFRONT_ambientSourcingAvailable m16 : 9|1@1+ (1,0) [0|1] ""  Receiver
 SG_ VCFRONT_ambientSourcingDisabled m14 : 38|1@1+ (1,0) [0|1] ""  Receiver
 SG_ VCFRONT_battDissipation m12 : 8|8@1+ (140,0) [0|35000] "W"  Receiver
 SG_ VCFRONT_battLoopWorthCooling m16 : 15|1@1+ (1,0) [0|1] ""  Receiver
 SG_ VCFRONT_battOverStagUpperLimit m16 : 6|1@1+ (1,0) [0|1] ""  Receiver
 SG_ VCFRONT_battUnderStagUpperLimit m16 : 7|1@1+ (1,0) [0|1] ""  Receiver
 SG_ VCFRONT_cabinHeatEnergyDuringDri m8 : 42|7@1+ (150,0) [0|19000] "Wh"  Receiver
 SG_ VCFRONT_calibratedPositionHCML m6 : 5|10@1+ (1,0) [0|1023] "Steps"  Receiver
 SG_ VCFRONT_calibratedPositionHCMR m6 : 16|10@1+ (1,0) [0|1023] "Steps"  Receiver
 SG_ VCFRONT_ccLeftExvCalibFailed m11 : 60|1@1+ (1,0) [0|1] ""  Receiver
 SG_ VCFRONT_ccLeftExvCalibOffset m11 : 40|8@1- (4,0) [-510|510] "ticks"  Receiver
 SG_ VCFRONT_ccLeftExvRange m7 : 41|9@1+ (3,0) [0|1500] "ticks"  Receiver
 SG_ VCFRONT_ccRightExvCalibFailed m11 : 61|1@1+ (1,0) [0|1] ""  Receiver
 SG_ VCFRONT_ccRightExvCalibOffset m11 : 48|8@1- (4,0) [-510|510] "ticks"  Receiver
 SG_ VCFRONT_ccRightExvRange m7 : 50|9@1+ (3,0) [0|1500] "ticks"  Receiver
 SG_ VCFRONT_chillerExvCalibFailed m11 : 56|1@1+ (1,0) [0|1] ""  Receiver
 SG_ VCFRONT_chillerExvCalibOffset m11 : 8|8@1- (4,0) [-510|510] "ticks"  Receiver
 SG_ VCFRONT_chillerExvRange m7 : 5|9@1+ (3,0) [0|1500] "ticks"  Receiver
 SG_ VCFRONT_chillerInletTempEstimate m13 : 27|8@1- (1,0) [-40|85] "C"  Receiver
 SG_ VCFRONT_chillerLiftDisabledLowPs m14 : 39|1@1+ (1,0) [0|1] ""  Receiver
 SG_ VCFRONT_chillerPassiveCoolPower m12 : 24|8@1- (60,7560) [0|15000] "W"  Receiver
 SG_ VCFRONT_compEnergyDuringDrive m8 : 35|7@1+ (150,0) [0|19000] "Wh"  Receiver
 SG_ VCFRONT_condenserPressureLimit m1 : 8|6@1+ (0.16,10) [10|20] "bar"  Receiver
 SG_ VCFRONT_coolantLevelVoltage m0 : 55|9@1+ (0.01,0) [0|5] "V"  Receiver
 SG_ VCFRONT_coolantValveAngleDrift m2 : 18|10@1+ (0.25,-127) [-127|127] "degrees"  Receiver
 SG_ VCFRONT_coolantValveCountRange m2 : 8|10@1+ (1,375) [375|1375] "ticks"  Receiver
 SG_ VCFRONT_coolantValveDailyAngleTr m19 : 34|10@1+ (20,0) [0|20000] "degrees"  Receiver
 SG_ VCFRONT_coolantValveOdometer m19 : 24|10@1+ (500,0) [0|500000] "degrees"  Receiver
 SG_ VCFRONT_coolantValveRadBypass m2 : 56|7@1+ (1,0) [0|100] "%"  Receiver
 SG_ VCFRONT_coolantValveRecalCount m2 : 28|16@1+ (1,0) [0|65535] ""  Receiver
 SG_ VCFRONT_coolantValveRecalReason m2 : 5|3@1+ (1,0) [0|7] ""  Receiver
 SG_ VCFRONT_coolantValveWindupEstL m2 : 44|6@1+ (2,0) [0|126] "ticks"  Receiver
 SG_ VCFRONT_coolantValveWindupEstR m2 : 50|6@1+ (2,0) [0|126] "ticks"  Receiver
 SG_ VCFRONT_currentPositionHCML m6 : 26|10@1+ (1,0) [0|1023] "Steps"  Receiver
 SG_ VCFRONT_currentPositionHCMR m6 : 36|10@1+ (1,0) [0|1023] "Steps"  Receiver
 SG_ VCFRONT_cycleModelConverged m10 : 61|1@1+ (1,0) [0|1] ""  Receiver
 SG_ VCFRONT_diDissipation m12 : 16|8@1+ (80,0) [0|20000] "W"  Receiver
 SG_ VCFRONT_dischargePressureLimit m19 : 48|7@1+ (0.25,0) [0|26] "bar"  Receiver
 SG_ VCFRONT_dischargePressureTarget m14 : 8|7@1+ (0.25,0) [0|26] "bar"  Receiver
 SG_ VCFRONT_drlMode m18 : 5|2@1+ (1,0) [0|2] ""  Receiver
 SG_ VCFRONT_estCompPower m16 : 35|8@1+ (50,0) [0|12750] "W"  Receiver
 SG_ VCFRONT_estCompRefrigMassflow m16 : 17|6@1+ (4,0) [0|251] "g/s"  Receiver
 SG_ VCFRONT_estCompressorRpm m10 : 48|6@1+ (400,0) [0|25200] "rpm"  Receiver
 SG_ VCFRONT_estPressureDisch m10 : 19|7@1+ (0.25,0) [0|31.75] "bar"  Receiver
 SG_ VCFRONT_estPressureLiq m10 : 5|7@1+ (0.25,0) [0|31.75] "bar"  Receiver
 SG_ VCFRONT_estPressureSuct m10 : 12|7@1+ (0.125,0) [0|11.5] "bar"  Receiver
 SG_ VCFRONT_estQLift m10 : 54|7@1+ (100,0) [0|12700] "W"  Receiver
 SG_ VCFRONT_estTempDisch m10 : 40|8@1- (0.8,68.8) [-34|170] "C"  Receiver
 SG_ VCFRONT_estTempLiq m10 : 26|8@1- (0.8,68.8) [-34|170] "C"  Receiver
 SG_ VCFRONT_estTempSuct m10 : 34|6@1- (1,2) [-30|33] "C"  Receiver
 SG_ VCFRONT_evapDisabledLowPsCutout m14 : 15|1@1+ (1,0) [0|1] ""  Receiver
 SG_ VCFRONT_evapExvCalibFailed m11 : 57|1@1+ (1,0) [0|1] ""  Receiver
 SG_ VCFRONT_evapExvCalibOffset m11 : 16|8@1- (4,0) [-510|510] "ticks"  Receiver
 SG_ VCFRONT_evapExvRange m7 : 14|9@1+ (3,0) [0|1500] "ticks"  Receiver
 SG_ VCFRONT_evapFdFrwrdTarget m9 : 28|7@1+ (80,0) [0|10100] "W"  Receiver
 SG_ VCFRONT_evapFdFrwrdTargetMinimum m9 : 49|7@1+ (80,0) [0|10000] "W"  Receiver
 SG_ VCFRONT_evapFdbk m9 : 35|7@1- (80,0) [-5000|5000] "W"  Receiver
 SG_ VCFRONT_exteriorQuietModeAllowed m9 : 6|1@1+ (1,0) [0|1] ""  Receiver
 SG_ VCFRONT_exteriorQuietModeEnabled m9 : 5|1@1+ (1,0) [0|1] ""  Receiver
 SG_ VCFRONT_fanControlFeedfwdActive m15 : 49|1@1+ (1,0) [0|1] ""  Receiver
 SG_ VCFRONT_fanControlRadCanCool m15 : 48|1@1+ (1,0) [0|1] ""  Receiver
 SG_ VCFRONT_fanControlRadiatorInletT m15 : 57|6@1- (1.8,36) [-20|90] "C"  Receiver
 SG_ VCFRONT_fanControlRadiatorUa m15 : 50|7@1+ (8,0) [0|1000] "W/C"  Receiver
 SG_ VCFRONT_fanDemandCondenser m1 : 14|7@1+ (1,0) [0|100] "%"  Receiver
 SG_ VCFRONT_fanDemandRadiator m1 : 21|7@1+ (1,0) [0|100] "%"  Receiver
 SG_ VCFRONT_feedBackDuctTempControll m15 : 32|8@1+ (1,-100) [-100|100] "-"  Receiver
 SG_ VCFRONT_feedBackEvapTempControll m15 : 24|7@1+ (0.01,-0.5) [-0.5|0.5] "-"  Receiver
 SG_ VCFRONT_feedFwdFanDemand m13 : 35|7@1+ (1,0) [0|100] "%"  Receiver
 SG_ VCFRONT_feedFwdMDotCabinCondense m15 : 16|8@1+ (0.005,0) [0|1] "-"  Receiver
 SG_ VCFRONT_feedFwdMDotEvaporator m15 : 8|8@1+ (0.005,0) [0|1] "-"  Receiver
 SG_ VCFRONT_feedFwdPumpDemand m13 : 42|7@1+ (1,0) [0|100] "%"  Receiver
 SG_ VCFRONT_feedfwdLoadCoolingDomina m9 : 59|1@1+ (1,0) [0|1] ""  Receiver
 SG_ VCFRONT_homelinkRegionCode m5 : 8|4@1+ (1,0) [0|9] ""  Receiver
 SG_ VCFRONT_hpAmbientSource m17 : 6|1@1+ (1,0) [0|1] ""  Receiver
 SG_ VCFRONT_hpAtSteadyState m16 : 50|1@1+ (1,0) [0|1] ""  Receiver
 SG_ VCFRONT_hpBattOverTempHvacDisabl m17 : 38|1@1+ (1,0) [0|1] ""  Receiver
 SG_ VCFRONT_hpBattStagTarget m8 : 28|7@1+ (1,-40) [-40|80] "C"  Receiver
 SG_ VCFRONT_hpBatteryCool m17 : 19|1@1+ (1,0) [0|1] ""  Receiver
 SG_ VCFRONT_hpBatteryCoolCabinConden m17 : 20|1@1+ (1,0) [0|1] ""  Receiver
 SG_ VCFRONT_hpBatteryCoolCabinReheat m17 : 21|1@1+ (1,0) [0|1] ""  Receiver
 SG_ VCFRONT_hpBatteryCoolEvaporator m17 : 22|1@1+ (1,0) [0|1] ""  Receiver
 SG_ VCFRONT_hpBatteryHeatAmbientSour m17 : 17|1@1+ (1,0) [0|1] ""  Receiver
 SG_ VCFRONT_hpBatteryHeatCOP1 m17 : 18|1@1+ (1,0) [0|1] ""  Receiver
 SG_ VCFRONT_hpCOP m8 : 22|6@1+ (0.1,0) [0|6] "-"  Receiver
 SG_ VCFRONT_hpCabinCoolEvaporator m17 : 15|1@1+ (1,0) [0|1] ""  Receiver
 SG_ VCFRONT_hpCabinCoolEvaporatorReh m17 : 16|1@1+ (1,0) [0|1] ""  Receiver
 SG_ VCFRONT_hpCabinHeatAmbientSource m17 : 8|1@1+ (1,0) [0|1] ""  Receiver
 SG_ VCFRONT_hpCabinHeatBatteryCoolRe m17 : 14|1@1+ (1,0) [0|1] ""  Receiver
 SG_ VCFRONT_hpCabinHeatBatteryHeatRe m17 : 13|1@1+ (1,0) [0|1] ""  Receiver
 SG_ VCFRONT_hpCabinHeatBlend m17 : 11|1@1+ (1,0) [0|1] ""  Receiver
 SG_ VCFRONT_hpCabinHeatCOP1 m17 : 12|1@1+ (1,0) [0|1] ""  Receiver
 SG_ VCFRONT_hpCabinHeatReheatAmbient m17 : 10|1@1+ (1,0) [0|1] ""  Receiver
 SG_ VCFRONT_hpCabinHeatReheatScaveng m17 : 9|1@1+ (1,0) [0|1] ""  Receiver
 SG_ VCFRONT_hpCabinHeatScavengeOnly m17 : 7|1@1+ (1,0) [0|1] ""  Receiver
 SG_ VCFRONT_hpCompPowerIndex m16 : 43|7@1+ (1,0) [0|127] "-"  Receiver
 SG_ VCFRONT_hpCompPowerIndexFiltered m12 : 56|7@1+ (1,0) [0|127] "-"  Receiver
 SG_ VCFRONT_hpDiagLouverCalib m17 : 39|1@1+ (1,0) [0|1] ""  Receiver
 SG_ VCFRONT_hpForceScavenge m16 : 5|1@1+ (1,0) [0|1] ""  Receiver
 SG_ VCFRONT_hpGeneral m17 : 5|1@1+ (1,0) [0|1] ""  Receiver
 SG_ VCFRONT_hpMode m16 : 10|5@1+ (1,0) [0|19] ""  Receiver
 SG_ VCFRONT_hpPotentialLowRefrig m9 : 61|1@1+ (1,0) [0|1] ""  Receiver
 SG_ VCFRONT_hpRefrigerantPurgeState m9 : 62|2@1+ (1,0) [0|2] ""  Receiver
 SG_ VCFRONT_hpSubcoolTarget m8 : 12|5@1+ (1,0) [0|31] "C"  Receiver
 SG_ VCFRONT_lccActiveCoolTarget m19 : 16|7@1+ (1,0) [0|100] "C"  Receiver
 SG_ VCFRONT_lccExvCalibFailed m11 : 59|1@1+ (1,0) [0|1] ""  Receiver
 SG_ VCFRONT_lccExvCalibOffset m11 : 32|8@1- (4,0) [-510|510] "ticks"  Receiver
 SG_ VCFRONT_lccExvRange m7 : 32|9@1+ (3,0) [0|1500] "ticks"  Receiver
 SG_ VCFRONT_lccInletTempEstimate m13 : 19|8@1- (1,0) [-40|85] "C"  Receiver
 SG_ VCFRONT_lccPassiveHeatPower m12 : 32|8@1+ (60,0) [0|15000] "W"  Receiver
 SG_ VCFRONT_lowSideLiftEnergyDrive m8 : 49|7@1+ (150,0) [0|19000] "Wh"  Receiver
 SG_ VCFRONT_lowSideWattsLift m8 : 56|7@1+ (60,0) [0|7600] "W"  Receiver
 SG_ VCFRONT_maxAllowedEvapPowerInSer m12 : 40|8@1+ (40,0) [0|10000] "W"  Receiver
 SG_ VCFRONT_maxChillerCoolingPower m15 : 40|8@1+ (100,0) [0|20000] "W"  Receiver
 SG_ VCFRONT_maxCompressorRPMAllowed m14 : 56|7@1+ (90,0) [0|11430] "rpm"  Receiver
 SG_ VCFRONT_minAllowedChillerPowerIn m12 : 48|8@1+ (40,0) [0|10000] "W"  Receiver
 SG_ VCFRONT_minAllowedSuctionPressur m14 : 48|7@1+ (0.02,0) [0|2.5] "bar"  Receiver
 SG_ VCFRONT_minFlowPDCont m14 : 16|8@1+ (0.5,0) [0|100] "%"  Receiver
 SG_ VCFRONT_modeDesired m0 : 14|2@1+ (1,0) [0|3] ""  Receiver
 SG_ VCFRONT_modeTransitionID m0 : 8|6@1+ (1,0) [0|40] ""  Receiver
 SG_ VCFRONT_modelLoadCoolingDominant m9 : 60|1@1+ (1,0) [0|1] ""  Receiver
 SG_ VCFRONT_passiveCoolingState m9 : 56|2@1+ (1,0) [0|3] ""  Receiver
 SG_ VCFRONT_passiveDemandRadBypass m19 : 8|7@1+ (1,0) [0|100] "%"  Receiver
 SG_ VCFRONT_passiveSeriesRegOn m19 : 5|1@1+ (1,0) [0|1] ""  Receiver
 SG_ VCFRONT_pressureRefrigDischEst m16 : 24|5@1+ (1,0) [0|31] "bar"  Receiver
 SG_ VCFRONT_pressureRefrigSuctionEst m16 : 51|7@1+ (0.12,0) [0|14.36] "bar"  Receiver
 SG_ VCFRONT_ptLoopWorthCooling m16 : 16|1@1+ (1,0) [0|1] ""  Receiver
 SG_ VCFRONT_pumpBatteryFETTemp m1 : 36|8@1+ (1,-40) [-40|150] "C"  Receiver
 SG_ VCFRONT_pumpPowertrainFETTemp m1 : 44|8@1+ (1,-40) [-40|150] "C"  Receiver
 SG_ VCFRONT_radActiveRejectEstimate m13 : 49|15@1+ (1,0) [0|30000] "W"  Receiver
 SG_ VCFRONT_radPassiveRejectEstimate m13 : 5|14@1+ (1,0) [0|15000] "W"  Receiver
 SG_ VCFRONT_radiatorFanFETTemp m1 : 52|8@1+ (1,-40) [-40|150] "C"  Receiver
 SG_ VCFRONT_radiatorFanRunReason m1 : 60|4@1+ (1,0) [0|8] ""  Receiver
 SG_ VCFRONT_recircExvCalibFailed m11 : 58|1@1+ (1,0) [0|1] ""  Receiver
 SG_ VCFRONT_recircExvCalibOffset m11 : 24|8@1- (4,0) [-510|510] "ticks"  Receiver
 SG_ VCFRONT_recircExvRange m7 : 23|9@1+ (3,0) [0|1500] "ticks"  Receiver
 SG_ VCFRONT_subcoolActual m8 : 5|7@1- (0.4,15.2) [-10|40] "C"  Receiver
 SG_ VCFRONT_suctionPressureTarget m14 : 32|6@1+ (0.15,0) [0|8] "bar"  Receiver
 SG_ VCFRONT_suctionSuperheatEstPsSNA m16 : 58|4@1+ (2,0) [0|30] "C"  Receiver
 SG_ VCFRONT_suctionSuperheatEstTsSNA m17 : 24|4@1+ (2,0) [0|30] "C"  Receiver
 SG_ VCFRONT_targetBatActiveCool m0 : 32|7@1+ (1,0) [0|100] "C"  Receiver
 SG_ VCFRONT_targetBatActiveHeat m0 : 48|7@1+ (1,-40) [-40|60] "C"  Receiver
 SG_ VCFRONT_targetBatPassive m0 : 40|7@1+ (1,-20) [-20|80] "C"  Receiver
 SG_ VCFRONT_targetPTActiveCool m0 : 16|8@1+ (1,-40) [-40|120] "C"  Receiver
 SG_ VCFRONT_targetPTPassive m0 : 24|8@1+ (1,-40) [-40|120] "C"  Receiver
 SG_ VCFRONT_tempRefrigDischargeEst m16 : 29|6@1+ (2,0) [0|125] "C"  Receiver
 SG_ VCFRONT_tempRefrigSuction m1 : 28|8@1+ (0.5,-40) [-40|85] "C"  Receiver
 SG_ VCFRONT_tempRefrigSuctionEst m17 : 32|6@1+ (1,0) [0|63] "C"  Receiver
 SG_ VCFRONT_totalLoadCoolingDominant m9 : 58|1@1+ (1,0) [0|1] ""  Receiver
 SG_ VCFRONT_wiperCycles m18 : 48|16@1+ (100,0) [0|6553500] "Cycles"  Receiver

BO_ 899 ID383VCRIGHT_thsStatus: 8 VehicleBus
 SG_ VCRIGHT_estimatedThsSolarLoad : 53|10@1+ (1,0) [0|1022] "W/m2"  Receiver
 SG_ VCRIGHT_estimatedVehicleSituatio : 31|2@1+ (1,0) [0|2] ""  Receiver
 SG_ VCRIGHT_thsActive : 0|1@1+ (1,0) [0|1] ""  Receiver
 SG_ VCRIGHT_thsHumidity : 17|8@1+ (1,0) [0|100] "%"  Receiver
 SG_ VCRIGHT_thsSolarLoadInfrared : 33|10@1+ (1,0) [0|1022] "W/m2"  Receiver
 SG_ VCRIGHT_thsSolarLoadVisible : 43|10@1+ (1,0) [0|1022] "W/m2"  Receiver
 SG_ VCRIGHT_thsTemperature : 1|8@1- (1,-40) [-40|150] "C"  Receiver

BO_ 900 PMS_alertMatrix1: 8 VEH
 SG_ PMS_w001_absoluteTorque: 0|1@1+ (1,0) [0|0] "" X
 SG_ PMS_w002_accumulatedTorque: 1|1@1+ (1,0) [0|0] "" X
 SG_ PMS_w003_torqueReversal: 2|1@1+ (1,0) [0|0] "" X
 SG_ PMS_w004_regenTorque: 3|1@1+ (1,0) [0|0] "" X
 SG_ PMS_w005_torqueInNeutral: 4|1@1+ (1,0) [0|0] "" X
 SG_ PMS_w006_inconsistentDIGear: 5|1@1+ (1,0) [0|0] "" X
 SG_ PMS_w007_watchdogReset: 6|1@1+ (1,0) [0|0] "" X
 SG_ PMS_w008_memoryError: 7|1@1+ (1,0) [0|0] "" X
 SG_ PMS_w009_espMIA: 8|1@1+ (1,0) [0|0] "" X
 SG_ PMS_w010_diMIA: 9|1@1+ (1,0) [0|0] "" X
 SG_ PMS_w011_phaseCurrentIrrational: 10|1@1+ (1,0) [0|0] "" X
 SG_ PMS_w012_canDataBusA: 11|1@1+ (1,0) [0|0] "" X
 SG_ PMS_w013_canHardwareBusA: 12|1@1+ (1,0) [0|0] "" X
 SG_ PMS_w018_encoderIrrational: 17|1@1+ (1,0) [0|0] "" X
 SG_ PMS_w019_statorTempIrrational: 18|1@1+ (1,0) [0|0] "" X
 SG_ PMS_w026_diHeartBeatMIA: 25|1@1+ (1,0) [0|0] "" X
 SG_ PMS_w027_torqueOutOfMap: 26|1@1+ (1,0) [0|0] "" X
 SG_ PMS_w028_torqueCmdError: 27|1@1+ (1,0) [0|0] "" X
 SG_ PMS_w031_highStackUsage: 30|1@1+ (1,0) [0|0] "" X
 SG_ PMS_w032_registerConfigError: 31|1@1+ (1,0) [0|0] "" X
 SG_ PMS_w033_selfTest: 32|1@1+ (1,0) [0|0] "" X
 SG_ PMS_w034_trqCrossCheck: 33|1@1+ (1,0) [0|0] "" X
 SG_ PMS_w038_inconsistentTorqueSign: 37|1@1+ (1,0) [0|0] "" X
 SG_ PMS_w039_disMIA: 38|1@1+ (1,0) [0|0] "" X
 SG_ PMS_w040_pmMIA: 39|1@1+ (1,0) [0|0] "" X
 SG_ PMS_w042_gtwMIA: 41|1@1+ (1,0) [0|0] "" X
 SG_ PMS_w043_inconsistentConfig: 42|1@1+ (1,0) [0|0] "" X
 SG_ PMS_w045_motorMovementDetected: 44|1@1+ (1,0) [0|0] "" X
 SG_ PMS_w053_vcfrontMIA: 52|1@1+ (1,0) [0|0] "" X
 SG_ PMS_w054_uiMIA: 53|1@1+ (1,0) [0|0] "" X
 SG_ PMS_w055_resolver: 54|1@1+ (1,0) [0|0] "" X
 SG_ PMS_w056_canHardwareBusB: 55|1@1+ (1,0) [0|0] "" X
 SG_ PMS_w057_canDataBusB: 56|1@1+ (1,0) [0|0] "" X
 SG_ PMS_w061_DIPMVersionMismatch: 60|1@1+ (1,0) [0|0] "" X
 SG_ PMS_w063_debugAlert: 62|1@1+ (1,0) [0|0] "" X
 SG_ PMS_w064_torqueIntervention: 63|1@1+ (1,0) [0|0] "" X

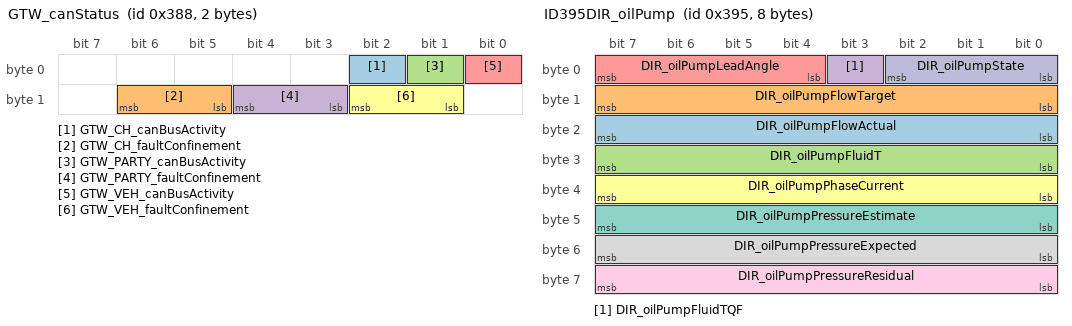
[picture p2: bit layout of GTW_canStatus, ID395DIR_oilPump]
BO_ 904 GTW_canStatus: 2 GTW
 SG_ GTW_CH_canBusActivity : 2|1@1+ (1,0) [0|1] "" ODIN,SUI,UI
 SG_ GTW_CH_faultConfinement : 13|2@1+ (1,0) [0|2] "" ODIN,UI
 SG_ GTW_PARTY_canBusActivity : 1|1@1+ (1,0) [0|1] "" ODIN,SUI,UI
 SG_ GTW_PARTY_faultConfinement : 11|2@1+ (1,0) [0|2] "" ODIN,UI
 SG_ GTW_VEH_canBusActivity : 0|1@1+ (1,0) [0|1] "" ODIN,SUI,UI
 SG_ GTW_VEH_faultConfinement : 9|2@1+ (1,0) [0|2] "" ODIN,UI

BO_ 905 ID389DAS_status2: 8 ChassisBus
 SG_ DAS_ACC_report : 26|5@1+ (1,0) [0|24] ""  Receiver
 SG_ DAS_accSpeedLimit : 0|10@1+ (0.2,0) [0|204.6] "mph"  Receiver
 SG_ DAS_activationFailureStatus : 14|2@1+ (1,0) [0|2] ""  Receiver
 SG_ DAS_csaState : 32|2@1+ (1,0) [0|3] ""  Receiver
 SG_ DAS_driverInteractionLevel : 38|2@1+ (1,0) [0|2] ""  Receiver
 SG_ DAS_longCollisionWarning : 48|4@1+ (1,0) [0|15] ""  Receiver
 SG_ DAS_pmmCameraFaultReason : 24|2@1+ (1,0) [0|2] ""  Receiver
 SG_ DAS_pmmLoggingRequest : 13|1@1+ (1,0) [0|1] ""  Receiver
 SG_ DAS_pmmObstacleSeverity : 10|3@1+ (1,0) [0|7] ""  Receiver
 SG_ DAS_pmmRadarFaultReason : 19|2@1+ (1,0) [0|2] ""  Receiver
 SG_ DAS_pmmSysFaultReason : 21|3@1+ (1,0) [0|7] ""  Receiver
 SG_ DAS_pmmUltrasonicsFaultReason : 16|3@1+ (1,0) [0|4] ""  Receiver
 SG_ DAS_ppOffsetDesiredRamp : 40|8@1+ (0.01,-1.28) [-1.28|1.27] "m"  Receiver
 SG_ DAS_radarTelemetry : 34|2@1+ (1,0) [0|2] ""  Receiver
 SG_ DAS_relaxCruiseLimits : 31|1@1+ (1,0) [0|1] ""  Receiver
 SG_ DAS_robState : 36|2@1+ (1,0) [0|3] ""  Receiver
 SG_ DAS_status2Checksum : 56|8@1+ (1,0) [0|255] ""  Receiver
 SG_ DAS_status2Counter : 52|4@1+ (1,0) [0|15] ""  Receiver

BO_ 909 TAS_warningMatrix3: 8 VEH
 SG_ TAS_w129_openCircuitFL: 0|1@1+ (1,0) [0|0] "" X
 SG_ TAS_w130_openCircuitFR: 1|1@1+ (1,0) [0|0] "" X
 SG_ TAS_w131_openCircuitRL: 2|1@1+ (1,0) [0|0] "" X
 SG_ TAS_w132_openCircuitRR: 3|1@1+ (1,0) [0|0] "" X
 SG_ TAS_w133_openCircuitReservoir: 4|1@1+ (1,0) [0|0] "" X
 SG_ TAS_w134_openCircuitExhaust: 5|1@1+ (1,0) [0|0] "" X
 SG_ TAS_w135_openCircuitBoost: 6|1@1+ (1,0) [0|0] "" X
 SG_ TAS_w136_openCircuitCompressor: 7|1@1+ (1,0) [0|0] "" X
 SG_ TAS_w137_shortCircuitFL: 8|1@1+ (1,0) [0|0] "" X
 SG_ TAS_w138_shortCircuitFR: 9|1@1+ (1,0) [0|0] "" X
 SG_ TAS_w139_shortCircuitRL: 10|1@1+ (1,0) [0|0] "" X
 SG_ TAS_w140_shortCircuitRR: 11|1@1+ (1,0) [0|0] "" X
 SG_ TAS_w141_shortCircuitReservoir: 12|1@1+ (1,0) [0|0] "" X
 SG_ TAS_w142_shortCircuitExhaust: 13|1@1+ (1,0) [0|0] "" X
 SG_ TAS_w143_shortCircuitBoost: 14|1@1+ (1,0) [0|0] "" X
 SG_ TAS_w144_shortCircuitCompressor: 15|1@1+ (1,0) [0|0] "" X
 SG_ TAS_w145_boardFaultFL: 16|1@1+ (1,0) [0|0] "" X
 SG_ TAS_w146_boardFaultFR: 17|1@1+ (1,0) [0|0] "" X
 SG_ TAS_w147_boardFaultRL: 18|1@1+ (1,0) [0|0] "" X
 SG_ TAS_w148_boardFaultRR: 19|1@1+ (1,0) [0|0] "" X
 SG_ TAS_w149_boardFaultReservoir: 20|1@1+ (1,0) [0|0] "" X
 SG_ TAS_w150_boardFaultExhaust: 21|1@1+ (1,0) [0|0] "" X
 SG_ TAS_w151_boardFaultBoost: 22|1@1+ (1,0) [0|0] "" X
 SG_ TAS_w152_boardFaultCompressor: 23|1@1+ (1,0) [0|0] "" X
 SG_ TAS_w153_otherCircuitFL: 24|1@1+ (1,0) [0|0] "" X
 SG_ TAS_w154_otherCircuitFR: 25|1@1+ (1,0) [0|0] "" X
 SG_ TAS_w155_otherCircuitRL: 26|1@1+ (1,0) [0|0] "" X
 SG_ TAS_w156_otherCircuitRR: 27|1@1+ (1,0) [0|0] "" X
 SG_ TAS_w157_otherCircuitReservoir: 28|1@1+ (1,0) [0|0] "" X
 SG_ TAS_w158_otherCircuitExhaust: 29|1@1+ (1,0) [0|0] "" X
 SG_ TAS_w159_otherCircuitBoost: 30|1@1+ (1,0) [0|0] "" X
 SG_ TAS_w160_otherCircuitCompressor: 31|1@1+ (1,0) [0|0] "" X
 SG_ TAS_w161_valveBlockOpenGND: 32|1@1+ (1,0) [0|0] "" X
 SG_ TAS_w162_compressorValveOpenGND: 33|1@1+ (1,0) [0|0] "" X
 SG_ TAS_w163_reservoirFillDisabled: 34|1@1+ (1,0) [0|0] "" X
 SG_ TAS_w164_calibrationVersion: 35|1@1+ (1,0) [0|0] "" X

BO_ 913 EPAS3S_alertMatrix: 8 CH
 SG_ EPAS3S_matrixIndex M: 0|4@1+ (1,0) [0|0] "" X
 SG_ EPAS3S_a001_sent1Mia m0: 4|1@1+ (1,0) [0|0] "" X
 SG_ EPAS3S_a002_sent1Error m0: 5|1@1+ (1,0) [0|0] "" X
 SG_ EPAS3S_a003_trqSens1Supply m0: 6|1@1+ (1,0) [0|0] "" X
 SG_ EPAS3S_a004_trqSens1Eeprom m0: 7|1@1+ (1,0) [0|0] "" X
 SG_ EPAS3S_a005_sent2Mia m0: 8|1@1+ (1,0) [0|0] "" X
 SG_ EPAS3S_a006_sent2Error m0: 9|1@1+ (1,0) [0|0] "" X
 SG_ EPAS3S_a007_trqSens2Supply m0: 10|1@1+ (1,0) [0|0] "" X
 SG_ EPAS3S_a008_trqSens2Eeprom m0: 11|1@1+ (1,0) [0|0] "" X
 SG_ EPAS3S_a009_sentDiff m0: 12|1@1+ (1,0) [0|0] "" X
 SG_ EPAS3S_a010_trqSensCalError m0: 13|1@1+ (1,0) [0|0] "" X
 SG_ EPAS3S_a011_currentSensError m0: 14|1@1+ (1,0) [0|0] "" X
 SG_ EPAS3S_a012_currentSensCalError m0: 15|1@1+ (1,0) [0|0] "" X
 SG_ EPAS3S_a013_gateDriveError m0: 16|1@1+ (1,0) [0|0] "" X
 SG_ EPAS3S_a014_gateDriveTxError m0: 17|1@1+ (1,0) [0|0] "" X
 SG_ EPAS3S_a015_gateDriveEeprom m0: 18|1@1+ (1,0) [0|0] "" X
 SG_ EPAS3S_a016_phaseUhighUv m0: 19|1@1+ (1,0) [0|0] "" X
 SG_ EPAS3S_a017_phaseUlowUv m0: 20|1@1+ (1,0) [0|0] "" X
 SG_ EPAS3S_a018_phaseVhighUv m0: 21|1@1+ (1,0) [0|0] "" X
 SG_ EPAS3S_a019_phaseVlowUv m0: 22|1@1+ (1,0) [0|0] "" X
 SG_ EPAS3S_a020_phaseWhighUv m0: 23|1@1+ (1,0) [0|0] "" X
 SG_ EPAS3S_a021_phaseWlowUv m0: 24|1@1+ (1,0) [0|0] "" X
 SG_ EPAS3S_a022_phaseUhighOv m0: 25|1@1+ (1,0) [0|0] "" X
 SG_ EPAS3S_a023_phaseUlowOv m0: 26|1@1+ (1,0) [0|0] "" X
 SG_ EPAS3S_a024_phaseVhighOv m0: 27|1@1+ (1,0) [0|0] "" X
 SG_ EPAS3S_a025_phaseVlowOv m0: 28|1@1+ (1,0) [0|0] "" X
 SG_ EPAS3S_a026_phaseWhighOv m0: 29|1@1+ (1,0) [0|0] "" X
 SG_ EPAS3S_a027_phaseWlowOv m0: 30|1@1+ (1,0) [0|0] "" X
 SG_ EPAS3S_a028_phaseUbootUv m0: 31|1@1+ (1,0) [0|0] "" X
 SG_ EPAS3S_a029_phaseVbootUv m0: 32|1@1+ (1,0) [0|0] "" X
 SG_ EPAS3S_a030_phaseWbootUv m0: 33|1@1+ (1,0) [0|0] "" X
 SG_ EPAS3S_a031_phaseFeedbackError m0: 34|1@1+ (1,0) [0|0] "" X
 SG_ EPAS3S_a032_vRegOutputUv m0: 35|1@1+ (1,0) [0|0] "" X
 SG_ EPAS3S_a033_vRegOutputOv m0: 36|1@1+ (1,0) [0|0] "" X
 SG_ EPAS3S_a034_vRegError m0: 37|1@1+ (1,0) [0|0] "" X
 SG_ EPAS3S_a035_vbbSupplyUv m0: 38|1@1+ (1,0) [0|0] "" X
 SG_ EPAS3S_a036_vbbSupplyOv m0: 39|1@1+ (1,0) [0|0] "" X
 SG_ EPAS3S_a037_motPos1ParityError m0: 40|1@1+ (1,0) [0|0] "" X
 SG_ EPAS3S_a038_motPos1Uv m0: 41|1@1+ (1,0) [0|0] "" X
 SG_ EPAS3S_a039_motPos1MagnetMia m0: 42|1@1+ (1,0) [0|0] "" X
 SG_ EPAS3S_a040_motPos1LogicError m0: 43|1@1+ (1,0) [0|0] "" X
 SG_ EPAS3S_a041_motPos1tempError m0: 44|1@1+ (1,0) [0|0] "" X
 SG_ EPAS3S_a042_motPos2ParityError m0: 45|1@1+ (1,0) [0|0] "" X
 SG_ EPAS3S_a043_motPos2Uv m0: 46|1@1+ (1,0) [0|0] "" X
 SG_ EPAS3S_a044_motPos2MagnetMia m0: 47|1@1+ (1,0) [0|0] "" X
 SG_ EPAS3S_a045_motPos2LogicError m0: 48|1@1+ (1,0) [0|0] "" X
 SG_ EPAS3S_a046_motPos2tempError m0: 49|1@1+ (1,0) [0|0] "" X
 SG_ EPAS3S_a047_motPosCorrError m0: 50|1@1+ (1,0) [0|0] "" X
 SG_ EPAS3S_a048_motPosCalError m0: 51|1@1+ (1,0) [0|0] "" X
 SG_ EPAS3S_a049_piCtrlError m0: 52|1@1+ (1,0) [0|0] "" X
 SG_ EPAS3S_a050_mcuSmuError m0: 53|1@1+ (1,0) [0|0] "" X
 SG_ EPAS3S_a051_mcuSupError m0: 54|1@1+ (1,0) [0|0] "" X
 SG_ EPAS3S_a052_intWatchdogError m0: 55|1@1+ (1,0) [0|0] "" X
 SG_ EPAS3S_a053_extWatchdogError m0: 56|1@1+ (1,0) [0|0] "" X
 SG_ EPAS3S_a054_memoryProtectError m0: 57|1@1+ (1,0) [0|0] "" X
 SG_ EPAS3S_a055_floatPointError m0: 58|1@1+ (1,0) [0|0] "" X
 SG_ EPAS3S_a056_battUv m0: 59|1@1+ (1,0) [0|0] "" X
 SG_ EPAS3S_a057_battUvReduced m0: 60|1@1+ (1,0) [0|0] "" X
 SG_ EPAS3S_a058_battOv m0: 61|1@1+ (1,0) [0|0] "" X
 SG_ EPAS3S_a059_battOvReduced m0: 62|1@1+ (1,0) [0|0] "" X
 SG_ EPAS3S_a060_battBridgeDiff m0: 63|1@1+ (1,0) [0|0] "" X
 SG_ EPAS3S_a061_bridgeUv m1: 4|1@1+ (1,0) [0|0] "" X
 SG_ EPAS3S_a062_assistCorrError m1: 5|1@1+ (1,0) [0|0] "" X
 SG_ EPAS3S_a063_dampCorrError m1: 6|1@1+ (1,0) [0|0] "" X
 SG_ EPAS3S_a064_phaseCompCorrError m1: 7|1@1+ (1,0) [0|0] "" X
 SG_ EPAS3S_a065_trqTarCorrError m1: 8|1@1+ (1,0) [0|0] "" X
 SG_ EPAS3S_a066_returnCorrError m1: 9|1@1+ (1,0) [0|0] "" X
 SG_ EPAS3S_a067_yawDampCorrError m1: 10|1@1+ (1,0) [0|0] "" X
 SG_ EPAS3S_a068_hystCorrError m1: 11|1@1+ (1,0) [0|0] "" X
 SG_ EPAS3S_a069_eacCorrError m1: 12|1@1+ (1,0) [0|0] "" X
 SG_ EPAS3S_a070_hodCorrError m1: 13|1@1+ (1,0) [0|0] "" X
 SG_ EPAS3S_a071_vehSpdCorrError m1: 14|1@1+ (1,0) [0|0] "" X
 SG_ EPAS3S_a072_motFeedFwdError m1: 15|1@1+ (1,0) [0|0] "" X
 SG_ EPAS3S_a073_motParEstError m1: 16|1@1+ (1,0) [0|0] "" X
 SG_ EPAS3S_a074_overHeatProtect m1: 17|1@1+ (1,0) [0|0] "" X
 SG_ EPAS3S_a075_fspPwrCut m1: 18|1@1+ (1,0) [0|0] "" X
 SG_ EPAS3S_a076_tempSensOutofRange m1: 19|1@1+ (1,0) [0|0] "" X
 SG_ EPAS3S_a077_highSideFetError m1: 20|1@1+ (1,0) [0|0] "" X
 SG_ EPAS3S_a078_phaseDisconnectError m1: 21|1@1+ (1,0) [0|0] "" X
 SG_ EPAS3S_a079_backupCurrentPlaus m1: 22|1@1+ (1,0) [0|0] "" X
 SG_ EPAS3S_a080_ecuInitArbError m1: 23|1@1+ (1,0) [0|0] "" X
 SG_ EPAS3S_a081_coggCompError m1: 24|1@1+ (1,0) [0|0] "" X
 SG_ EPAS3S_a082_polarityCalError m1: 25|1@1+ (1,0) [0|0] "" X
 SG_ EPAS3S_a083_crcMismatch m1: 26|1@1+ (1,0) [0|0] "" X
 SG_ EPAS3S_a084_eacCancelled m1: 27|1@1+ (1,0) [0|0] "" X
 SG_ EPAS3S_a085_canBusOff m1: 28|1@1+ (1,0) [0|0] "" X
 SG_ EPAS3S_a086_dasMia m1: 29|1@1+ (1,0) [0|0] "" X
 SG_ EPAS3S_a087_dasCntError m1: 30|1@1+ (1,0) [0|0] "" X
 SG_ EPAS3S_a088_dasCsError m1: 31|1@1+ (1,0) [0|0] "" X
 SG_ EPAS3S_a089_espWsMia m1: 32|1@1+ (1,0) [0|0] "" X
 SG_ EPAS3S_a090_espWsCntError m1: 33|1@1+ (1,0) [0|0] "" X
 SG_ EPAS3S_a091_espWsCsError m1: 34|1@1+ (1,0) [0|0] "" X
 SG_ EPAS3S_a092_espWrMia m1: 35|1@1+ (1,0) [0|0] "" X
 SG_ EPAS3S_a093_espWrCntError m1: 36|1@1+ (1,0) [0|0] "" X
 SG_ EPAS3S_a094_espWrCsError m1: 37|1@1+ (1,0) [0|0] "" X
 SG_ EPAS3S_a095_espWsStatus m1: 38|1@1+ (1,0) [0|0] "" X
 SG_ EPAS3S_a096_rcmMia m1: 39|1@1+ (1,0) [0|0] "" X
 SG_ EPAS3S_a097_rcmCntError m1: 40|1@1+ (1,0) [0|0] "" X
 SG_ EPAS3S_a098_rcmCsError m1: 41|1@1+ (1,0) [0|0] "" X
 SG_ EPAS3S_a099_yawRateStatus m1: 42|1@1+ (1,0) [0|0] "" X
 SG_ EPAS3S_a100_diMia m1: 43|1@1+ (1,0) [0|0] "" X
 SG_ EPAS3S_a101_diCntError m1: 44|1@1+ (1,0) [0|0] "" X
 SG_ EPAS3S_a102_diCsError m1: 45|1@1+ (1,0) [0|0] "" X
 SG_ EPAS3S_a103_vcFrontMia m1: 46|1@1+ (1,0) [0|0] "" X
 SG_ EPAS3S_a104_vcFrontCntError m1: 47|1@1+ (1,0) [0|0] "" X
 SG_ EPAS3S_a105_vcFrontCsError m1: 48|1@1+ (1,0) [0|0] "" X
 SG_ EPAS3S_a106_vcFrontTempMia m1: 49|1@1+ (1,0) [0|0] "" X
 SG_ EPAS3S_a107_uiTuneReqMia m1: 50|1@1+ (1,0) [0|0] "" X
 SG_ EPAS3S_a108_uiTuneReqCntError m1: 51|1@1+ (1,0) [0|0] "" X
 SG_ EPAS3S_a109_uiTuneReqCsError m1: 52|1@1+ (1,0) [0|0] "" X
 SG_ EPAS3S_a110_sasMia m1: 53|1@1+ (1,0) [0|0] "" X
 SG_ EPAS3S_a111_sasCntError m1: 54|1@1+ (1,0) [0|0] "" X
 SG_ EPAS3S_a112_sasCsError m1: 55|1@1+ (1,0) [0|0] "" X
 SG_ EPAS3S_a113_sasStatusError m1: 56|1@1+ (1,0) [0|0] "" X
 SG_ EPAS3S_a114_gtwConfigMia m1: 57|1@1+ (1,0) [0|0] "" X
 SG_ EPAS3S_a115_ecuStatMia m1: 58|1@1+ (1,0) [0|0] "" X
 SG_ EPAS3S_a116_ecuStatCntError m1: 59|1@1+ (1,0) [0|0] "" X
 SG_ EPAS3S_a117_ecuStatCrcError m1: 60|1@1+ (1,0) [0|0] "" X
 SG_ EPAS3S_a118_privateBusOff m1: 61|1@1+ (1,0) [0|0] "" X
 SG_ EPAS3S_a119_pvtEcuStatMia m1: 62|1@1+ (1,0) [0|0] "" X
 SG_ EPAS3S_a120_pvtEcuStatCntError m1: 63|1@1+ (1,0) [0|0] "" X
 SG_ EPAS3S_a121_pvtEcuStatCrcError m2: 4|1@1+ (1,0) [0|0] "" X
 SG_ EPAS3S_a122_olpActive m2: 5|1@1+ (1,0) [0|0] "" X
 SG_ EPAS3S_a123_combEcu2StatFail m2: 6|1@1+ (1,0) [0|0] "" X
 SG_ EPAS3S_a124_tempSensStuckInRange m2: 7|1@1+ (1,0) [0|0] "" X
 SG_ EPAS3S_a125_trqSensTrimOutRange m2: 8|1@1+ (1,0) [0|0] "" X
 SG_ EPAS3S_a126_apsMia m2: 9|1@1+ (1,0) [0|0] "" X
 SG_ EPAS3S_a127_apsCntError m2: 10|1@1+ (1,0) [0|0] "" X
 SG_ EPAS3S_a128_apsCsError m2: 11|1@1+ (1,0) [0|0] "" X
 SG_ EPAS3S_a129_combEcu1StatFail m2: 12|1@1+ (1,0) [0|0] "" X
 SG_ EPAS3S_a130_sasOffsetNotCal m2: 13|1@1+ (1,0) [0|0] "" X

BO_ 914 ID392BMS_packConfig: 8 VehicleBus
 SG_ BMS_packConfigMultiplexer M : 0|8@1+ (1,0) [0|1] ""  Receiver
 SG_ BMS_moduleType m1 : 8|3@1+ (1,0) [0|4] ""  Receiver
 SG_ BMS_packMass m1 : 16|8@1+ (1,300) [342|469] "kg"  Receiver
 SG_ BMS_reservedConfig_0 m0 : 8|5@1+ (1,0) [0|31] ""  Receiver
 SG_ BMS_platformMaxBusVoltage m1 : 24|10@1+ (0.1,375) [0|0] "V"  Receiver

BO_ 915 ID393VCRIGHT_epbmDebug: 8 VEH
 SG_ VCRIGHT_epbmDebugIndex M : 0|1@1+ (1,0) [0|1] ""  Receiver
 SG_ VCRIGHT_cdpEnumDummy m1 : 24|2@1+ (1,0) [0|2] ""  Receiver
 SG_ VCRIGHT_epbFaultStatus m0 : 58|2@1+ (1,0) [0|3] ""  Receiver
 SG_ VCRIGHT_epbMotorCurrent m0 : 5|11@1+ (0.01,0) [0|20.47] "A"  Receiver
 SG_ VCRIGHT_epbSummonState m0 : 45|3@1+ (1,0) [0|6] ""  Receiver
 SG_ VCRIGHT_epbUnitStatus m0 : 51|5@1+ (1,0) [0|22] ""  Receiver
 SG_ VCRIGHT_epbmApplyVoltage m0 : 16|11@1+ (0.01,0) [0|20.47] "A"  Receiver
 SG_ VCRIGHT_epbmCaliperState m0 : 1|3@1+ (1,0) [0|6] ""  Receiver
 SG_ VCRIGHT_epbmDynApplyingAllowed m1 : 9|1@1+ (1,0) [0|1] ""  Receiver
 SG_ VCRIGHT_epbmDynamicAllowed m1 : 2|1@1+ (1,0) [0|1] ""  Receiver
 SG_ VCRIGHT_epbmFaultAllowed m1 : 11|1@1+ (1,0) [0|1] ""  Receiver
 SG_ VCRIGHT_epbmFaultStatus m0 : 56|2@1+ (1,0) [0|3] ""  ui
 SG_ VCRIGHT_epbmMotorEnabled m0 : 4|1@1+ (1,0) [0|1] ""  Receiver
 SG_ VCRIGHT_epbmOpenAllowed m1 : 1|1@1+ (1,0) [0|1] ""  Receiver
 SG_ VCRIGHT_epbmParkAllowed m1 : 3|1@1+ (1,0) [0|1] ""  Receiver
 SG_ VCRIGHT_epbmParkingAllowed m1 : 8|1@1+ (1,0) [0|1] ""  Receiver
 SG_ VCRIGHT_epbmReleaseVoltage m0 : 27|11@1+ (0.01,0) [0|20.47] "A"  Receiver
 SG_ VCRIGHT_epbmReleasingAllowed m1 : 10|1@1+ (1,0) [0|1] ""  Receiver
 SG_ VCRIGHT_epbmServiceAllowed m1 : 5|1@1+ (1,0) [0|1] ""  Receiver
 SG_ VCRIGHT_epbmStartAllowed m1 : 4|1@1+ (1,0) [0|1] ""  Receiver
 SG_ VCRIGHT_epbmSummonAllowed m1 : 12|1@1+ (1,0) [0|1] ""  Receiver
 SG_ VCRIGHT_epbmSummonParkAllowed m1 : 13|1@1+ (1,0) [0|1] ""  Receiver
 SG_ VCRIGHT_epbmSummonReleaseAllowed m1 : 14|1@1+ (1,0) [0|1] ""  Receiver
 SG_ VCRIGHT_epbmSummonState m0 : 48|3@1+ (1,0) [0|6] ""  Receiver
 SG_ VCRIGHT_epbmSystemStatus m0 : 60|4@1+ (1,0) [0|8] ""  Receiver
 SG_ VCRIGHT_epbmUnknownAllowed m1 : 16|1@1+ (1,0) [0|1] ""  Receiver
 SG_ VCRIGHT_epbmWinchAllowed m1 : 6|1@1+ (1,0) [0|1] ""  Receiver
 SG_ VCRIGHT_epbmWinchReleaseAllowed m1 : 7|1@1+ (1,0) [0|1] ""  Receiver
 SG_ VCRIGHT_summonActiveAllowed m1 : 19|1@1+ (1,0) [0|1] ""  Receiver
 SG_ VCRIGHT_summonArmedAllowed m1 : 18|1@1+ (1,0) [0|1] ""  Receiver
 SG_ VCRIGHT_summonCompleteAllowed m1 : 20|1@1+ (1,0) [0|1] ""  Receiver
 SG_ VCRIGHT_summonFaultAllowed m1 : 21|1@1+ (1,0) [0|1] ""  Receiver
 SG_ VCRIGHT_summonFaultReason m0 : 40|5@1+ (1,0) [0|28] ""  Receiver
 SG_ VCRIGHT_summonIdleAllowed m1 : 17|1@1+ (1,0) [0|1] ""  Receiver
 SG_ VCRIGHT_summonInitAllowed m1 : 15|1@1+ (1,0) [0|1] ""  Receiver
 SG_ VCRIGHT_summonUnavailableAllowed m1 : 22|1@1+ (1,0) [0|1] ""  Receiver

BO_ 917 ID395DIR_oilPump: 8 VehicleBus
 SG_ DIR_oilPumpFlowActual : 16|8@1+ (0.06,0) [0|15] "LPM"  Receiver
 SG_ DIR_oilPumpFlowTarget : 8|8@1+ (0.06,0) [0|15] "LPM"  Receiver
 SG_ DIR_oilPumpFluidT : 24|8@1+ (1,-40) [-40|214] "C"  Receiver
 SG_ DIR_oilPumpFluidTQF : 3|1@1+ (1,0) [0|1] ""  Receiver
 SG_ DIR_oilPumpLeadAngle : 4|4@1+ (1.875,0) [0|28.125] "deg"  Receiver
 SG_ DIR_oilPumpPhaseCurrent : 32|8@1+ (0.1,0) [0|25.4] "A"  Receiver
 SG_ DIR_oilPumpPressureEstimate : 40|8@1+ (2,0) [0|500] "kPa"  Receiver
 SG_ DIR_oilPumpPressureExpected : 48|8@1+ (2,0) [0|500] "kPa"  Receiver
 SG_ DIR_oilPumpPressureResidual : 56|8@1+ (4,-500) [-500|500] "kPa"  Receiver
 SG_ DIR_oilPumpState : 0|3@1+ (1,0) [0|7] ""  Receiver

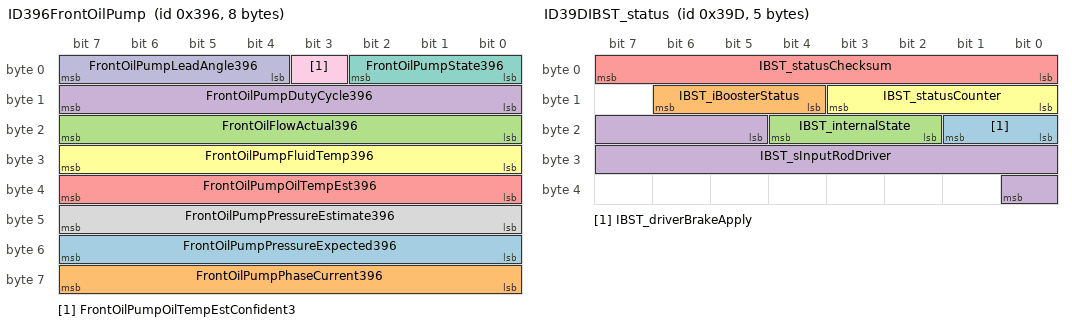
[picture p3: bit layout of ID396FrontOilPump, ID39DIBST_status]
BO_ 918 ID396FrontOilPump: 8 VehicleBus
 SG_ FrontOilPumpPressureExpected396 : 48|8@1+ (2,0) [0|500] "kPa"  Receiver
 SG_ FrontOilPumpPhaseCurrent396 : 56|8@1+ (0.1,0) [0|25.4] "A"  Receiver
 SG_ FrontOilFlowActual396 : 16|8@1+ (0.06,0) [0|15] "LPM"  Receiver
 SG_ FrontOilPumpDutyCycle396 : 8|8@1+ (0.4,0) [0|100] "%"  Receiver
 SG_ FrontOilPumpOilTempEst396 : 32|8@1+ (1,-40) [0|214] "C"  Receiver
 SG_ FrontOilPumpFluidTemp396 : 24|8@1+ (1,-40) [0|214] "C"  Receiver
 SG_ FrontOilPumpState396 : 0|3@1+ (1,0) [0|7] ""  Receiver
 SG_ FrontOilPumpPressureEstimate396 : 40|8@1+ (2,0) [0|500] "kPa"  Receiver
 SG_ FrontOilPumpOilTempEstConfident3 : 3|1@1+ (1,0) [0|0] ""  Receiver
 SG_ FrontOilPumpLeadAngle396 : 4|4@1+ (1.875,0) [0|28.125] "deg"  Receiver

BO_ 921 ID399DAS_status: 8 ChassisBus
 SG_ DAS_autoLaneChangeState : 46|5@1+ (1,0) [0|31] ""  Receiver
 SG_ DAS_autoParked : 25|1@1+ (1,0) [0|1] ""  Receiver
 SG_ DAS_autoparkReady : 24|1@1+ (1,0) [0|1] ""  Receiver
 SG_ DAS_autoparkWaitingForBrake : 26|1@1+ (1,0) [0|1] ""  Receiver
 SG_ DAS_autopilotHandsOnState : 42|4@1+ (1,0) [0|15] ""  Receiver
 SG_ DAS_autopilotState : 0|4@1+ (1,0) [0|15] ""  Receiver
 SG_ DAS_blindSpotRearLeft : 4|2@1+ (1,0) [0|3] ""  Receiver
 SG_ DAS_blindSpotRearRight : 6|2@1+ (1,0) [0|3] ""  Receiver
 SG_ DAS_fleetSpeedState : 40|2@1+ (1,0) [0|3] ""  Receiver
 SG_ DAS_forwardCollisionWarning : 22|2@1+ (1,0) [0|3] ""  Receiver
 SG_ DAS_fusedSpeedLimit : 8|5@1+ (5,0) [0|150] "kph/mph"  Receiver
 SG_ DAS_heaterState : 21|1@1+ (1,0) [0|1] ""  Receiver
 SG_ DAS_laneDepartureWarning : 37|3@1+ (1,0) [0|5] ""  Receiver
 SG_ DAS_lssState : 29|3@1+ (1,0) [0|7] ""  Receiver
 SG_ DAS_sideCollisionAvoid : 32|2@1+ (1,0) [0|3] ""  Receiver
 SG_ DAS_sideCollisionInhibit : 36|1@1+ (1,0) [0|1] ""  Receiver
 SG_ DAS_sideCollisionWarning : 34|2@1+ (1,0) [0|3] ""  Receiver
 SG_ DAS_statusChecksum : 56|8@1+ (1,0) [0|255] ""  Receiver
 SG_ DAS_statusCounter : 52|4@1+ (1,0) [0|15] ""  Receiver
 SG_ DAS_summonAvailable : 51|1@1+ (1,0) [0|1] ""  Receiver
 SG_ DAS_summonClearedGate : 15|1@1+ (1,0) [0|1] ""  Receiver
 SG_ DAS_summonFwdLeashReached : 27|1@1+ (1,0) [0|1] ""  Receiver
 SG_ DAS_summonObstacle : 14|1@1+ (1,0) [0|1] ""  Receiver
 SG_ DAS_summonRvsLeashReached : 28|1@1+ (1,0) [0|1] ""  Receiver
 SG_ DAS_suppressSpeedWarning : 13|1@1+ (1,0) [0|1] ""  Receiver
 SG_ DAS_visionOnlySpeedLimit : 16|5@1+ (5,0) [0|150] "kph/mph"  Receiver

BO_ 923 DAS_status: 8 PARTY
 SG_ DAS_statusChecksum : 56|8@1+ (1,0) [0|255] ""  aps
 SG_ DAS_statusCounter : 52|4@1+ (1,0) [0|15] ""  aps
 SG_ DAS_summonAvailable : 51|1@1+ (1,0) [0|1] ""  aps
 SG_ DAS_autoLaneChangeState : 46|5@1+ (1,0) [0|31] ""  aps
 SG_ DAS_autopilotHandsOnState : 42|4@1+ (1,0) [0|15] ""  aps
 SG_ DAS_fleetSpeedState : 40|2@1+ (1,0) [0|3] ""  aps
 SG_ DAS_laneDepartureWarning : 37|3@1+ (1,0) [0|5] ""  aps
 SG_ DAS_csaState : 35|2@1+ (1,0) [0|3] ""  aps
 SG_ DAS_sideCollisionInhibit : 34|1@1+ (1,0) [0|1] ""  aps
 SG_ DAS_sideCollisionWarning : 32|2@1+ (1,0) [0|3] ""  aps
 SG_ DAS_sideCollisionAvoid : 30|2@1+ (1,0) [0|3] ""  aps
 SG_ DAS_summonRvsLeashReached : 29|1@1+ (1,0) [0|1] ""  aps
 SG_ DAS_summonFwdLeashReached : 28|1@1+ (1,0) [0|1] ""  aps
 SG_ DAS_autoparkWaitingForBrake : 26|1@1+ (1,0) [0|1] ""  gtw
 SG_ DAS_autoParked : 25|1@1+ (1,0) [0|1] ""  aps
 SG_ DAS_autoparkReady : 24|1@1+ (1,0) [0|1] ""  aps
 SG_ DAS_forwardCollisionWarning : 22|2@1+ (1,0) [0|3] ""  aps
 SG_ DAS_heaterState : 21|1@1+ (1,0) [0|1] ""  gtw
 SG_ DAS_visionOnlySpeedLimit : 16|5@1+ (5,0) [0|150] "kph/mph"  aps
 SG_ DAS_summonClearedGate : 15|1@1+ (1,0) [0|1] ""  aps
 SG_ DAS_summonObstacle : 14|1@1+ (1,0) [0|1] ""  aps
 SG_ DAS_suppressSpeedWarning : 13|1@1+ (1,0) [0|1] ""  aps
 SG_ DAS_fusedSpeedLimit : 8|5@1+ (5,0) [0|150] "kph/mph"  aps
 SG_ DAS_blindSpotRearRight : 6|2@1+ (1,0) [0|3] ""  aps
 SG_ DAS_blindSpotRearLeft : 4|2@1+ (1,0) [0|3] ""  aps
 SG_ DAS_autopilotState : 0|4@1+ (1,0) [0|15] ""  aps

BO_ 925 ID39DIBST_status: 5 ChassisBus
 SG_ IBST_driverBrakeApply : 16|2@1+ (1,0) [0|3] ""  Receiver
 SG_ IBST_iBoosterStatus : 12|3@1+ (1,0) [0|6] ""  Receiver
 SG_ IBST_internalState : 18|3@1+ (1,0) [0|6] ""  Receiver
 SG_ IBST_sInputRodDriver : 21|12@1+ (0.015625,-5) [-5|47] "mm"  Receiver
 SG_ IBST_statusChecksum : 0|8@1+ (1,0) [0|255] ""  Receiver
 SG_ IBST_statusCounter : 8|4@1+ (1,0) [0|15] ""  Receiver

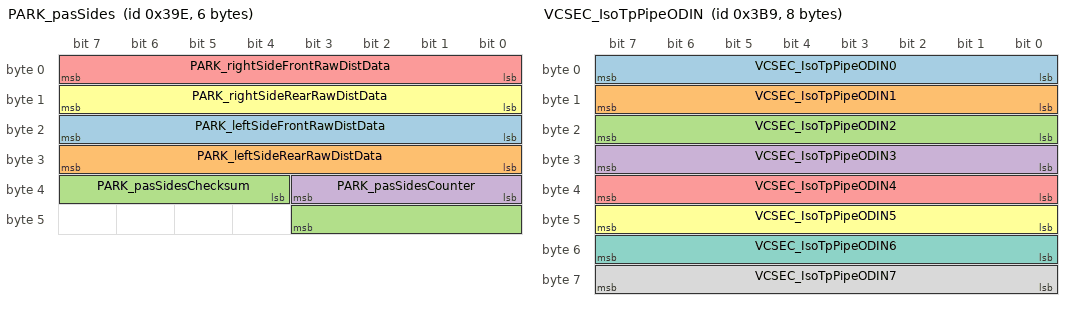
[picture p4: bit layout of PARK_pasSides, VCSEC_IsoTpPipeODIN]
BO_ 926 PARK_pasSides: 6 CH
 SG_ PARK_leftSideFrontRawDistData: 16|8@1+ (1,0) [0|0] "cm" X
 SG_ PARK_leftSideRearRawDistData: 24|8@1+ (1,0) [0|0] "cm" X
 SG_ PARK_pasSidesChecksum: 36|8@1+ (1,0) [0|0] "" X
 SG_ PARK_pasSidesCounter: 32|4@1+ (1,0) [0|0] "" X
 SG_ PARK_rightSideFrontRawDistData: 0|8@1+ (1,0) [0|0] "cm" X
 SG_ PARK_rightSideRearRawDistData: 8|8@1+ (1,0) [0|0] "cm" X

BO_ 927 FC_alertMatrix4: 8 VEH
 SG_ FC_a193_FCAlertPlaceholder: 0|1@1+ (1,0) [0|0] "" X

BO_ 929 ID3A1VCFRONT_vehicleStatus: 8 VehicleBus
 SG_ VCFRONT_12vStatusForDrive : 14|2@1+ (1,0) [0|2] ""  Receiver
 SG_ VCFRONT_2RowCenterUnbuckled : 38|2@1+ (1,0) [0|2] ""  Receiver
 SG_ VCFRONT_2RowLeftUnbuckled : 36|2@1+ (1,0) [0|2] ""  Receiver
 SG_ VCFRONT_2RowRightUnbuckled : 40|2@1+ (1,0) [0|2] ""  Receiver
 SG_ VCFRONT_APGlassHeaterState : 2|3@1+ (1,0) [0|4] ""  Receiver
 SG_ VCFRONT_accPlusAvailable : 9|1@1+ (1,0) [0|1] ""  Receiver
 SG_ VCFRONT_batterySupportRequest : 27|1@1+ (1,0) [0|1] ""  Receiver
 SG_ VCFRONT_bmsHvChargeEnable : 0|1@1+ (1,0) [0|1] ""  Receiver
 SG_ VCFRONT_diPowerOnState : 10|3@1+ (1,0) [0|4] ""  Receiver
 SG_ VCFRONT_driverBuckleStatus : 30|1@1+ (1,0) [0|1] ""  Receiver
 SG_ VCFRONT_driverDoorStatus : 31|1@1+ (1,0) [0|1] ""  Receiver
 SG_ VCFRONT_driverIsLeaving : 28|1@1+ (1,0) [0|1] ""  Receiver
 SG_ VCFRONT_driverIsLeavingAnySpeed : 13|1@1+ (1,0) [0|1] ""  Receiver
 SG_ VCFRONT_driverPresent : 7|1@1+ (1,0) [0|1] ""  Receiver
 SG_ VCFRONT_driverUnbuckled : 32|2@1+ (1,0) [0|2] ""  Receiver
 SG_ VCFRONT_ota12VSupportRequest : 29|1@1+ (1,0) [0|1] ""  Receiver
 SG_ VCFRONT_passengerPresent : 8|1@1+ (1,0) [0|1] ""  Receiver
 SG_ VCFRONT_passengerUnbuckled : 34|2@1+ (1,0) [0|2] ""  Receiver
 SG_ VCFRONT_pcs12vVoltageTarget : 16|11@1+ (0.01,0) [0|16] "V"  Receiver
 SG_ VCFRONT_pcsEFuseVoltage : 42|10@1+ (0.1,0) [0|102.2] "V"  Receiver
 SG_ VCFRONT_preconditionRequest : 1|1@1+ (1,0) [0|1] ""  Receiver
 SG_ VCFRONT_standbySupplySupported : 6|1@1+ (1,0) [0|1] ""  Receiver
 SG_ VCFRONT_thermalSystemType : 5|1@1+ (1,0) [0|1] ""  Receiver
 SG_ VCFRONT_vehicleStatusChecksum : 56|8@1+ (1,0) [0|255] ""  Receiver
 SG_ VCFRONT_vehicleStatusCounter : 52|4@1+ (1,0) [0|15] ""  Receiver

BO_ 930 VCLEFT_status: 8 VEH
 SG_ VCLEFT_statusIndex M: 0|1@1+ (1,0) [0|0] "" X
 SG_ VCLEFT_loadShedPriority m0: 1|8@1+ (1,0) [0|0] "" X
 SG_ VCLEFT_vehiclePowerStateDBG m0: 9|2@1+ (1,0) [0|0] "" X
 SG_ VCLEFT_consoleDoorAssist m0: 11|1@1+ (1,0) [0|0] "" X
 SG_ VCLEFT_OTAState m0: 12|1@1+ (1,0) [0|0] "" X
 SG_ VCLEFT_5AVoltage m0: 13|10@1+ (0.00544368,0) [0|0] "V" X
 SG_ VCLEFT_vbatProt m0: 23|12@1+ (0.00544368,0) [0|0] "V" X
 SG_ VCLEFT_footwellLightCurrent m0: 35|12@1- (0.1,0) [0|0] "mA" X
 SG_ VCLEFT_swcInputVoltage m0: 47|8@1+ (0.1,0) [0|0] "V" X
 SG_ VCLEFT_swcPCBATemperature m0: 55|8@1- (1,-40) [0|0] "degC" X
 SG_ VCLEFT_pcbaTemperature m1: 1|11@1+ (0.125,-40) [0|0] "degC" X
 SG_ VCLEFT_DIeFuseCurrent m1: 12|12@1- (0.1,0) [0|0] "A" X
 SG_ VCLEFT_DIeFuseFault m1: 24|1@1+ (1,0) [0|0] "" X
 SG_ VCLEFT_tlcPCBATemperature m1: 32|8@1- (1,-40) [0|0] "degC" X

BO_ 932 PCS_alertMatrix: 8 VEH
 SG_ PCS_matrixIndex M: 0|4@1+ (1,0) [0|0] "" X
 SG_ PCS_a001_chgHwInputOc m0: 4|1@1+ (1,0) [0|0] "" X
 SG_ PCS_a002_chgHwOutputOc m0: 5|1@1+ (1,0) [0|0] "" X
 SG_ PCS_a003_chgHwInputOv m0: 6|1@1+ (1,0) [0|0] "" X
 SG_ PCS_a004_chgHwIntBusOv m0: 7|1@1+ (1,0) [0|0] "" X
 SG_ PCS_a005_chgOutputOv m0: 8|1@1+ (1,0) [0|0] "" X
 SG_ PCS_a006_chgPrechargeFailedScr m0: 9|1@1+ (1,0) [0|0] "" X
 SG_ PCS_a007_chgPhaseTempHot m0: 10|1@1+ (1,0) [0|0] "" X
 SG_ PCS_a008_chgPhaseOverTemp m0: 11|1@1+ (1,0) [0|0] "" X
 SG_ PCS_a009_chgPfcCurrentRegulation m0: 12|1@1+ (1,0) [0|0] "" X
 SG_ PCS_a010_chgIntBusVRegulation m0: 13|1@1+ (1,0) [0|0] "" X
 SG_ PCS_a011_chgLlcCurrentRegulation m0: 14|1@1+ (1,0) [0|0] "" X
 SG_ PCS_a012_chgPfcIBandTracerFault m0: 15|1@1+ (1,0) [0|0] "" X
 SG_ PCS_a013_chgPrechargeFailedBoost m0: 16|1@1+ (1,0) [0|0] "" X
 SG_ PCS_a014_chgTempRationality m0: 17|1@1+ (1,0) [0|0] "" X
 SG_ PCS_a015_chg12vUv m0: 18|1@1+ (1,0) [0|0] "" X
 SG_ PCS_a016_chgAllPhasesFaulted m0: 19|1@1+ (1,0) [0|0] "" X
 SG_ PCS_a017_chgWallPowerRemoval m0: 20|1@1+ (1,0) [0|0] "" X
 SG_ PCS_a018_chgUnknownGridConfig m0: 21|1@1+ (1,0) [0|0] "" X
 SG_ PCS_a019_acChargePowerLimited m0: 22|1@1+ (1,0) [0|0] "" X
 SG_ PCS_a020_chgEnableLineMismatch m0: 23|1@1+ (1,0) [0|0] "" X
 SG_ PCS_a021_hvpMia m0: 24|1@1+ (1,0) [0|0] "" X
 SG_ PCS_a022_bmsMia m0: 25|1@1+ (1,0) [0|0] "" X
 SG_ PCS_a023_cpMia m0: 26|1@1+ (1,0) [0|0] "" X
 SG_ PCS_a024_vcfrontMia m0: 27|1@1+ (1,0) [0|0] "" X
 SG_ PCS_a025_cpu2Malfunction m0: 28|1@1+ (1,0) [0|0] "" X
 SG_ PCS_a026_watchdogAlarmed m0: 29|1@1+ (1,0) [0|0] "" X
 SG_ PCS_a027_chgInsufficientCooling m0: 30|1@1+ (1,0) [0|0] "" X
 SG_ PCS_a028_chgOutputUv m0: 31|1@1+ (1,0) [0|0] "" X
 SG_ PCS_a029_chgPowerRationality m0: 32|1@1+ (1,0) [0|0] "" X
 SG_ PCS_a030_canRationality m0: 33|1@1+ (1,0) [0|0] "" X
 SG_ PCS_a031_uiMia m0: 34|1@1+ (1,0) [0|0] "" X
 SG_ PCS_a032_gtwMia m0: 35|1@1+ (1,0) [0|0] "" X
 SG_ PCS_a033_hvBusUv m0: 36|1@1+ (1,0) [0|0] "" X
 SG_ PCS_a034_hvBusOv m0: 37|1@1+ (1,0) [0|0] "" X
 SG_ PCS_a035_lvBusUv m0: 38|1@1+ (1,0) [0|0] "" X
 SG_ PCS_a036_lvBusOv m0: 39|1@1+ (1,0) [0|0] "" X
 SG_ PCS_a037_resonantTankOc m0: 40|1@1+ (1,0) [0|0] "" X
 SG_ PCS_a038_claFaulted m0: 41|1@1+ (1,0) [0|0] "" X
 SG_ PCS_a039_sdModuleClkFault m0: 42|1@1+ (1,0) [0|0] "" X
 SG_ PCS_a040_dcdcMaxPowerReached m0: 43|1@1+ (1,0) [0|0] "" X
 SG_ PCS_a041_dcdcOverTemp m0: 44|1@1+ (1,0) [0|0] "" X
 SG_ PCS_a042_dcdcEnableLineMismatch m0: 45|1@1+ (1,0) [0|0] "" X
 SG_ PCS_a043_hvBusPrechargeFailure m0: 46|1@1+ (1,0) [0|0] "" X
 SG_ PCS_a044_12vSupportRegulation m0: 47|1@1+ (1,0) [0|0] "" X
 SG_ PCS_a045_hvBusLowImpedance m0: 48|1@1+ (1,0) [0|0] "" X
 SG_ PCS_a046_hvBusHighImpedence m0: 49|1@1+ (1,0) [0|0] "" X
 SG_ PCS_a047_lvBusLowImpedance m0: 50|1@1+ (1,0) [0|0] "" X
 SG_ PCS_a048_lvBusHighImpedance m0: 51|1@1+ (1,0) [0|0] "" X
 SG_ PCS_a049_dcdcTempRationality m0: 52|1@1+ (1,0) [0|0] "" X
 SG_ PCS_a050_dcdc12VsupportFaulted m0: 53|1@1+ (1,0) [0|0] "" X
 SG_ PCS_a051_chgIntBusUv m0: 54|1@1+ (1,0) [0|0] "" X
 SG_ PCS_a052_acVoltageNotPresent m0: 55|1@1+ (1,0) [0|0] "" X
 SG_ PCS_a053_chgInputVDropHigh m0: 56|1@1+ (1,0) [0|0] "" X
 SG_ PCS_a054_chgInputVDropTooHigh m0: 57|1@1+ (1,0) [0|0] "" X
 SG_ PCS_a055_chgLineImedanceHigh m0: 58|1@1+ (1,0) [0|0] "" X
 SG_ PCS_a056_chgLineImedanceTooHigh m0: 59|1@1+ (1,0) [0|0] "" X
 SG_ PCS_a057_chgInputOverFreq m0: 60|1@1+ (1,0) [0|0] "" X
 SG_ PCS_a058_chgInputUnderFreq m0: 61|1@1+ (1,0) [0|0] "" X
 SG_ PCS_a059_chgInputOvRms m0: 62|1@1+ (1,0) [0|0] "" X
 SG_ PCS_a060_chgInputOvPeak m0: 63|1@1+ (1,0) [0|0] "" X
 SG_ PCS_a061_chgVLineRationality m1: 4|1@1+ (1,0) [0|0] "" X
 SG_ PCS_a062_chgILineRationality m1: 5|1@1+ (1,0) [0|0] "" X
 SG_ PCS_a063_chgVOutRationality m1: 6|1@1+ (1,0) [0|0] "" X
 SG_ PCS_a064_chgIOutRationality m1: 7|1@1+ (1,0) [0|0] "" X
 SG_ PCS_a065_chgPllNotLocked m1: 8|1@1+ (1,0) [0|0] "" X
 SG_ PCS_a066_dcdcHvRationality m1: 9|1@1+ (1,0) [0|0] "" X
 SG_ PCS_a067_dcdcLvRationality m1: 10|1@1+ (1,0) [0|0] "" X
 SG_ PCS_a068_dcdcTankvRationality m1: 11|1@1+ (1,0) [0|0] "" X
 SG_ PCS_a069_chgPfcLineDidt m1: 12|1@1+ (1,0) [0|0] "" X
 SG_ PCS_a070_chgPfcLineDvdt m1: 13|1@1+ (1,0) [0|0] "" X
 SG_ PCS_a071_chgPfcILoopRationality m1: 14|1@1+ (1,0) [0|0] "" X
 SG_ PCS_a072_cpu2ClaStopped m1: 15|1@1+ (1,0) [0|0] "" X
 SG_ PCS_a073_unexpectedAcInputVoltage m1: 16|1@1+ (1,0) [0|0] "" X
 SG_ PCS_a074_hvBusDischargeFailure m1: 17|1@1+ (1,0) [0|0] "" X
 SG_ PCS_a075_hvBusDischargeTimeout m1: 18|1@1+ (1,0) [0|0] "" X
 SG_ PCS_a076_dcdcEnDeassertedErr m1: 19|1@1+ (1,0) [0|0] "" X
 SG_ PCS_a077_microGridEnergyLow m1: 20|1@1+ (1,0) [0|0] "" X
 SG_ PCS_a078_chgStopDcdcTooHot m1: 21|1@1+ (1,0) [0|0] "" X
 SG_ PCS_a079_eepromOperationError m1: 22|1@1+ (1,0) [0|0] "" X
 SG_ PCS_a080_damagedPhaseDetected m1: 23|1@1+ (1,0) [0|0] "" X
 SG_ PCS_a081_dcdcPchgTimeout m1: 24|1@1+ (1,0) [0|0] "" X
 SG_ PCS_a082_dcdcPchgUnsafeDiVoltage m1: 25|1@1+ (1,0) [0|0] "" X
 SG_ PCS_a083_triggerOdin m1: 26|1@1+ (1,0) [0|0] "" X
 SG_ PCS_a084_dcdcPchgStartVoltages m1: 27|1@1+ (1,0) [0|0] "" X
 SG_ PCS_a085_dcdcFetsNotSwitching m1: 28|1@1+ (1,0) [0|0] "" X
 SG_ PCS_a086_dcdcInsufficientCooling m1: 29|1@1+ (1,0) [0|0] "" X
 SG_ PCS_a087_nvramRecordStatusError m1: 30|1@1+ (1,0) [0|0] "" X
 SG_ PCS_a088_pchgParameters m1: 31|1@1+ (1,0) [0|0] "" X
 SG_ PCS_a089_hvBusDischargeIrrational m1: 32|1@1+ (1,0) [0|0] "" X

BO_ 933 DIS_alertMatrix1: 8 VEH
 SG_ DIS_a001_hwPhaseAgateDrive: 0|1@1+ (1,0) [0|0] "" X
 SG_ DIS_a002_hwPhaseBgateDrive: 1|1@1+ (1,0) [0|0] "" X
 SG_ DIS_a003_hwPhaseCgateDrive: 2|1@1+ (1,0) [0|0] "" X
 SG_ DIS_a004_hwPhaseApeak: 3|1@1+ (1,0) [0|0] "" X
 SG_ DIS_a005_hwPhaseBpeak: 4|1@1+ (1,0) [0|0] "" X
 SG_ DIS_a006_hwPhaseCpeak: 5|1@1+ (1,0) [0|0] "" X
 SG_ DIS_a007_hwHvilNotPresent: 6|1@1+ (1,0) [0|0] "" X
 SG_ DIS_a008_hwEncoderA: 7|1@1+ (1,0) [0|0] "" X
 SG_ DIS_a009_hwEncoderB: 8|1@1+ (1,0) [0|0] "" X
 SG_ DIS_a011_swPowerStageNotReady: 10|1@1+ (1,0) [0|0] "" X
 SG_ DIS_a014_activeDamping: 13|1@1+ (1,0) [0|0] "" X
 SG_ DIS_a016_safeStateApplied: 15|1@1+ (1,0) [0|0] "" X
 SG_ DIS_a017_hwPedalMonitor: 16|1@1+ (1,0) [0|0] "" X
 SG_ DIS_a018_hw12vSupplyUV: 17|1@1+ (1,0) [0|0] "" X
 SG_ DIS_a019_hwAccelPedalPower: 18|1@1+ (1,0) [0|0] "" X
 SG_ DIS_a020_hwMotorEncoder: 19|1@1+ (1,0) [0|0] "" X
 SG_ DIS_a021_hwBusOV: 20|1@1+ (1,0) [0|0] "" X
 SG_ DIS_a022_hw5vSupplyUV: 21|1@1+ (1,0) [0|0] "" X
 SG_ DIS_a024_selfTest: 23|1@1+ (1,0) [0|0] "" X
 SG_ DIS_a025_phaseApeak: 24|1@1+ (1,0) [0|0] "" X
 SG_ DIS_a026_phaseBpeak: 25|1@1+ (1,0) [0|0] "" X
 SG_ DIS_a027_phaseCpeak: 26|1@1+ (1,0) [0|0] "" X
 SG_ DIS_a028_phaseArms: 27|1@1+ (1,0) [0|0] "" X
 SG_ DIS_a029_phaseBrms: 28|1@1+ (1,0) [0|0] "" X
 SG_ DIS_a030_phaseCrms: 29|1@1+ (1,0) [0|0] "" X
 SG_ DIS_a031_phaseAcurrentOffset: 30|1@1+ (1,0) [0|0] "" X
 SG_ DIS_a032_phaseBcurrentOffset: 31|1@1+ (1,0) [0|0] "" X
 SG_ DIS_a033_phaseAcurrentSensor: 32|1@1+ (1,0) [0|0] "" X
 SG_ DIS_a034_phaseBcurrentSensor: 33|1@1+ (1,0) [0|0] "" X
 SG_ DIS_a035_phaseCurrentBalance: 34|1@1+ (1,0) [0|0] "" X
 SG_ DIS_a036_busOV: 35|1@1+ (1,0) [0|0] "" X
 SG_ DIS_a037_busUV: 36|1@1+ (1,0) [0|0] "" X
 SG_ DIS_a038_busVsensor: 37|1@1+ (1,0) [0|0] "" X
 SG_ DIS_a040_disMIA: 39|1@1+ (1,0) [0|0] "" X
 SG_ DIS_a042_inletSensor: 41|1@1+ (1,0) [0|0] "" X
 SG_ DIS_a043_outletOT: 42|1@1+ (1,0) [0|0] "" X
 SG_ DIS_a044_outletUT: 43|1@1+ (1,0) [0|0] "" X
 SG_ DIS_a045_outletSensor: 44|1@1+ (1,0) [0|0] "" X
 SG_ DIS_a046_statorOT: 45|1@1+ (1,0) [0|0] "" X
 SG_ DIS_a047_statorSensor1: 46|1@1+ (1,0) [0|0] "" X
 SG_ DIS_a050_noStatorSensor: 49|1@1+ (1,0) [0|0] "" X
 SG_ DIS_a054_driveInverterOT: 53|1@1+ (1,0) [0|0] "" X
 SG_ DIS_a055_trqCrossCheck: 54|1@1+ (1,0) [0|0] "" X
 SG_ DIS_a056_ambientOT: 55|1@1+ (1,0) [0|0] "" X
 SG_ DIS_a057_ambientUT: 56|1@1+ (1,0) [0|0] "" X
 SG_ DIS_a058_ambientSensor: 57|1@1+ (1,0) [0|0] "" X
 SG_ DIS_a059_heatsinkOT: 58|1@1+ (1,0) [0|0] "" X
 SG_ DIS_a060_heatsinkUT: 59|1@1+ (1,0) [0|0] "" X
 SG_ DIS_a061_heatsinkSensor: 60|1@1+ (1,0) [0|0] "" X
 SG_ DIS_a062_systemLimpMode: 61|1@1+ (1,0) [0|0] "" X
 SG_ DIS_a064_torqueIntervention: 63|1@1+ (1,0) [0|0] "" X

BO_ 937 DAS_telemetry: 8 VEH
 SG_ DAS_telemetryMultiplexer M: 0|8@1+ (1,0) [0|0] "" X
 SG_ DAS_telLeftLaneType m0: 8|3@1+ (1,0) [0|0] "" X
 SG_ DAS_telRightLaneType m0: 11|3@1+ (1,0) [0|0] "" X
 SG_ DAS_telLeftMarkerQuality m0: 14|2@1+ (1,0) [0|0] "" X
 SG_ DAS_telRightMarkerQuality m0: 16|2@1+ (1,0) [0|0] "" X
 SG_ DAS_telLeftMarkerColor m0: 18|2@1+ (1,0) [0|0] "" X
 SG_ DAS_telRightMarkerColor m0: 20|2@1+ (1,0) [0|0] "" X
 SG_ DAS_telLeftLaneCrossing m0: 22|1@1+ (1,0) [0|0] "" X
 SG_ DAS_telRightLaneCrossing m0: 23|1@1+ (1,0) [0|0] "" X
 SG_ DAS_MCPObserved m1: 8|1@1+ (1,0) [0|0] "" X
 SG_ DAS_accReengaged m1: 9|1@1+ (1,0) [0|0] "" X
 SG_ DAS_pedestrianInFOVBeforeIntr m1: 10|1@1+ (1,0) [0|0] "" X
 SG_ DAS_pedestrianInFOVAfterIntr m1: 11|1@1+ (1,0) [0|0] "" X
 SG_ DAS_camFreeSpaceBeforeIntr m1: 12|1@1+ (1,0) [0|0] "" X
 SG_ DAS_camFreeSpaceAfterIntr m1: 13|1@1+ (1,0) [0|0] "" X
 SG_ DAS_timeOfIntervention m1: 14|6@1+ (0.25,0) [0|0] "s" X
 SG_ DAS_timeOfFirstPedestrian m1: 20|6@1+ (0.25,0) [0|0] "s" X
 SG_ DAS_timeOfACCReengaging m1: 26|6@1+ (0.25,0) [0|0] "s" X
 SG_ DAS_durationOfPrevACCStandstill m1: 32|6@1+ (0.5,0) [0|0] "s" X
 SG_ DAS_maxAbsSteeringWheelAngle m1: 38|7@1+ (2,0) [0|0] "degrees" X
 SG_ DAS_targetRelvelAtIntervention m1: 45|6@1+ (0.25,-2) [0|0] "m/s" X
 SG_ DAS_targetDistAtIntervention m1: 51|6@1+ (0.5,0) [0|0] "m" X
 SG_ DAS_egoSpeedAtIntervention m1: 57|6@1+ (0.5,0) [0|0] "m/s" X
 SG_ DAS_stopSignLongitudinalDist m2: 8|10@1+ (0.1,0) [0|0] "m" X
 SG_ DAS_stopSignLateralDist m2: 18|8@1+ (0.25,-32) [0|0] "m" X
 SG_ DAS_stopSignHeight m2: 26|6@1+ (0.1,0) [0|0] "m" X
 SG_ DAS_stopSignStopLineDistance m2: 32|10@1+ (0.1,-20) [0|0] "m" X
 SG_ DAS_stopSignCIPVDistance m2: 42|6@1+ (0.5,0) [0|0] "m" X
 SG_ DAS_stopSignHostAccel m2: 48|10@1+ (0.01,-5) [0|0] "m/s^2" X
 SG_ DAS_stopSignCrossingWarning m2: 58|1@1+ (1,0) [0|0] "" X
 SG_ DAS_stopSignIndex m2: 59|4@1+ (1,0) [0|0] "" X
 SG_ DAS_csaOverride m7: 10|1@1+ (1,0) [0|0] "" X
 SG_ DAS_csaIntState m7: 11|3@1+ (1,0) [0|0] "" X
 SG_ DAS_csaEnableSpeed m7: 14|12@1+ (0.05,-25) [0|0] "MPH" X
 SG_ DAS_csaDisableSpeed m7: 26|12@1+ (0.05,-25) [0|0] "MPH" X
 SG_ DAS_csaFiltCurv m7: 40|16@1- (1e-06,0) [0|0] "1/m" X
 SG_ DAS_csaMeasLatAccel m7: 56|8@1+ (0.08,-10.24) [0|0] "m/s^2" X
 SG_ DAS_soCamCipvStatus m8: 8|2@1+ (1,0) [0|0] "" X
 SG_ DAS_soRad5Status m8: 10|2@1+ (1,0) [0|0] "" X
 SG_ DAS_soRad1Status m8: 12|2@1+ (1,0) [0|0] "" X
 SG_ DAS_soCamCipvDx m8: 14|6@1+ (2,0) [0|0] "m" X
 SG_ DAS_soRad1Dx m8: 20|6@1+ (2,0) [0|0] "m" X
 SG_ DAS_soRad5Dx m8: 26|6@1+ (2,0) [0|0] "m" X
 SG_ DAS_soCamCipvDy m8: 32|5@1+ (0.4,-6.4) [0|0] "m" X
 SG_ DAS_soRad5Dy m8: 37|5@1+ (0.4,-6.4) [0|0] "m" X
 SG_ DAS_soCamCipvVx m8: 42|5@1+ (1,0) [0|0] "m/s" X
 SG_ DAS_soRad5ObstProb m8: 47|4@1+ (0.0625,0) [0|0] "probability" X
 SG_ DAS_soRad5Dz m8: 51|6@1+ (0.25,-5) [0|0] "m" X
 SG_ DAS_soRad5powerdB m8: 57|7@1+ (2,0) [0|0] "dB" X
 SG_ DAS_assPrevSetSpeed m9: 8|8@1+ (0.25,0) [0|0] "m/s" X
 SG_ DAS_assNewSetSpeed m9: 16|8@1+ (0.25,0) [0|0] "m/s" X
 SG_ DAS_assFusedSpeedLimit m9: 24|6@1+ (1,0) [0|0] "m/s" X
 SG_ DAS_assAutosteerActive m9: 30|1@1+ (1,0) [0|0] "" X
 SG_ DAS_assSmartSpeedActive m9: 31|1@1+ (1,0) [0|0] "" X

BO_ 938 HVP_alertMatrix1: 8 VEH
 SG_ HVP_w001_WatchdogReset: 0|1@1+ (1,0) [0|0] "" X
 SG_ HVP_w002_UnusedAlert2: 1|1@1+ (1,0) [0|0] "" X
 SG_ HVP_w003_SwAssertion: 2|1@1+ (1,0) [0|0] "" X
 SG_ HVP_w004_CrashEvent: 3|1@1+ (1,0) [0|0] "" X
 SG_ HVP_w005_OverDchgCurrentFault: 4|1@1+ (1,0) [0|0] "" X
 SG_ HVP_w006_OverChargeCurrentFault: 5|1@1+ (1,0) [0|0] "" X
 SG_ HVP_w007_OverCurrentFault: 6|1@1+ (1,0) [0|0] "" X
 SG_ HVP_w008_OverTemperatureFault: 7|1@1+ (1,0) [0|0] "" X
 SG_ HVP_w009_OverVoltageFault: 8|1@1+ (1,0) [0|0] "" X
 SG_ HVP_w010_UnderVoltageFault: 9|1@1+ (1,0) [0|0] "" X
 SG_ HVP_w011_PrimaryBmbMiaFault: 10|1@1+ (1,0) [0|0] "" X
 SG_ HVP_w012_SecondaryBmbMiaFault: 11|1@1+ (1,0) [0|0] "" X
 SG_ HVP_w013_BmbMismatchFault: 12|1@1+ (1,0) [0|0] "" X
 SG_ HVP_w014_BmsHviMiaFault: 13|1@1+ (1,0) [0|0] "" X
 SG_ HVP_w015_CpMiaFault: 14|1@1+ (1,0) [0|0] "" X
 SG_ HVP_w016_PcsMiaFault: 15|1@1+ (1,0) [0|0] "" X
 SG_ HVP_w017_BmsFault: 16|1@1+ (1,0) [0|0] "" X
 SG_ HVP_w018_PcsFault: 17|1@1+ (1,0) [0|0] "" X
 SG_ HVP_w019_CpFault: 18|1@1+ (1,0) [0|0] "" X
 SG_ HVP_w020_ShuntHwMiaFault: 19|1@1+ (1,0) [0|0] "" X
 SG_ HVP_w021_PyroMiaFault: 20|1@1+ (1,0) [0|0] "" X
 SG_ HVP_w022_hvsMiaFault: 21|1@1+ (1,0) [0|0] "" X
 SG_ HVP_w024_Supply12vFault: 23|1@1+ (1,0) [0|0] "" X
 SG_ HVP_w025_VerSupplyFault: 24|1@1+ (1,0) [0|0] "" X
 SG_ HVP_w026_HvilFault: 25|1@1+ (1,0) [0|0] "" X
 SG_ HVP_w027_BmsHvsMiaFault: 26|1@1+ (1,0) [0|0] "" X
 SG_ HVP_w028_PackVoltMismatchFault: 27|1@1+ (1,0) [0|0] "" X
 SG_ HVP_w029_EnsMiaFault: 28|1@1+ (1,0) [0|0] "" X
 SG_ HVP_w030_PackPosCtrArcFault: 29|1@1+ (1,0) [0|0] "" X
 SG_ HVP_w031_packNegCtrArcFault: 30|1@1+ (1,0) [0|0] "" X
 SG_ HVP_w032_ShuntHwAndBmsMiaFault: 31|1@1+ (1,0) [0|0] "" X
 SG_ HVP_w033_fcContHwFault: 32|1@1+ (1,0) [0|0] "" X
 SG_ HVP_w034_robinOverVoltageFault: 33|1@1+ (1,0) [0|0] "" X
 SG_ HVP_w035_packContHwFault: 34|1@1+ (1,0) [0|0] "" X
 SG_ HVP_w036_pyroFuseBlown: 35|1@1+ (1,0) [0|0] "" X
 SG_ HVP_w037_pyroFuseFailedToBlow: 36|1@1+ (1,0) [0|0] "" X
 SG_ HVP_w038_CpilFault: 37|1@1+ (1,0) [0|0] "" X
 SG_ HVP_w039_PackContactorFellOpen: 38|1@1+ (1,0) [0|0] "" X
 SG_ HVP_w040_FcContactorFellOpen: 39|1@1+ (1,0) [0|0] "" X
 SG_ HVP_w041_packCtrCloseBlocked: 40|1@1+ (1,0) [0|0] "" X
 SG_ HVP_w042_fcCtrCloseBlocked: 41|1@1+ (1,0) [0|0] "" X
 SG_ HVP_w043_packContactorForceOpen: 42|1@1+ (1,0) [0|0] "" X
 SG_ HVP_w044_fcContactorForceOpen: 43|1@1+ (1,0) [0|0] "" X
 SG_ HVP_w045_dcLinkOverVoltage: 44|1@1+ (1,0) [0|0] "" X
 SG_ HVP_w046_shuntOverTemperature: 45|1@1+ (1,0) [0|0] "" X
 SG_ HVP_w047_passivePyroDeploy: 46|1@1+ (1,0) [0|0] "" X
 SG_ HVP_w048_logUploadRequest: 47|1@1+ (1,0) [0|0] "" X
 SG_ HVP_w049_packCtrCloseFailed: 48|1@1+ (1,0) [0|0] "" X
 SG_ HVP_w050_fcCtrCloseFailed: 49|1@1+ (1,0) [0|0] "" X
 SG_ HVP_w051_shuntThermistorMia: 50|1@1+ (1,0) [0|0] "" X

BO_ 941 TAS_warningMatrix4: 8 VEH
 SG_ TAS_w200_jackModeActive: 7|1@1+ (1,0) [0|0] "" X
 SG_ TAS_w201_lowHVBattery: 8|1@1+ (1,0) [0|0] "" X
 SG_ TAS_w210_outOfRangeCalibration: 17|1@1+ (1,0) [0|0] "" X
 SG_ TAS_w211_noRideHeightCalib: 18|1@1+ (1,0) [0|0] "" X
 SG_ TAS_w212_noCurrentSenseCalib: 19|1@1+ (1,0) [0|0] "" X
 SG_ TAS_w213_yellowWarningLamp: 20|1@1+ (1,0) [0|0] "" X
 SG_ TAS_w214_redWarningLamp: 21|1@1+ (1,0) [0|0] "" X
 SG_ TAS_w215_limpHomeMode10: 22|1@1+ (1,0) [0|0] "" X
 SG_ TAS_w216_limpHomeMode20: 23|1@1+ (1,0) [0|0] "" X
 SG_ TAS_w217_limpHomeMode30: 24|1@1+ (1,0) [0|0] "" X
 SG_ TAS_w218_limpHomeMode40: 25|1@1+ (1,0) [0|0] "" X
 SG_ TAS_w220_exhaustGalleryFault: 27|1@1+ (1,0) [0|0] "" X
 SG_ TAS_w221_valveLeakDetected: 28|1@1+ (1,0) [0|0] "" X
 SG_ TAS_w222_compressorPrefillFault: 29|1@1+ (1,0) [0|0] "" X
 SG_ TAS_w223_blockedAirline: 30|1@1+ (1,0) [0|0] "" X
 SG_ TAS_w224_openAirline: 31|1@1+ (1,0) [0|0] "" X
 SG_ TAS_w225_galleryPressureTooHigh: 32|1@1+ (1,0) [0|0] "" X
 SG_ TAS_w226_PWMfastDetectFL: 33|1@1+ (1,0) [0|0] "" X
 SG_ TAS_w227_PWMfastDetectFR: 34|1@1+ (1,0) [0|0] "" X
 SG_ TAS_w228_PWMfastDetectRL: 35|1@1+ (1,0) [0|0] "" X
 SG_ TAS_w229_PWMfastDetectRR: 36|1@1+ (1,0) [0|0] "" X

BO_ 945 DAS_telemetryFurniture: 8 VEH
 SG_ DAS_TF_multiplexer M: 0|5@1+ (1,0) [0|0] "" X
 SG_ DAS_TF_furnitureIndex0 m0: 5|8@1+ (1,0) [0|0] "" X
 SG_ DAS_TF_distTraveled m0: 13|11@1+ (0.1,0) [0|0] "m" X
 SG_ DAS_TF_llType m0: 24|3@1+ (1,0) [0|0] "" X
 SG_ DAS_TF_rlType m0: 27|3@1+ (1,0) [0|0] "" X
 SG_ DAS_TF_cipvDist m0: 30|9@1+ (0.1,0) [0|0] "m" X
 SG_ DAS_TF_timeOfDay m0: 39|3@1+ (1,0) [0|0] "" X
 SG_ DAS_TF_furnitureType m0: 42|3@1+ (1,0) [0|0] "" X
 SG_ DAS_TF_furnitureIndex1 m1: 5|8@1+ (1,0) [0|0] "" X
 SG_ DAS_TF_longitudinalDist m1: 13|12@1+ (0.1,0) [0|0] "m" X
 SG_ DAS_TF_lateralDist m1: 25|12@1+ (0.1,-204.8) [0|0] "m" X
 SG_ DAS_TF_height m1: 37|12@1+ (0.05,0) [0|0] "m" X
 SG_ DAS_TF_color m1: 49|3@1+ (1,0) [0|0] "" X
 SG_ DAS_TF_shape m1: 52|3@1+ (1,0) [0|0] "" X
 SG_ DAS_TF_orientation m1: 55|2@1+ (1,0) [0|0] "" X
 SG_ DAS_TF_transmissionStatus m1: 57|2@1+ (1,0) [0|0] "" X
 SG_ DAS_TF_isMain m1: 59|1@1+ (1,0) [0|0] "" X
 SG_ DAS_TF_isTeslaMain m1: 60|1@1+ (1,0) [0|0] "" X
 SG_ DAS_TF_furnitureIndex2 m2: 5|8@1+ (1,0) [0|0] "" X
 SG_ DAS_TF_juncStatus m2: 13|4@1+ (1,0) [0|0] "" X
 SG_ DAS_TF_juncDist m2: 17|11@1+ (0.2,-20) [0|0] "m" X
 SG_ DAS_TF_stopLineDist m2: 28|11@1+ (0.1,-10) [0|0] "m" X
 SG_ DAS_TF_ttc m2: 39|7@1+ (0.1,0) [0|0] "s" X

BO_ 947 ID3B3UI_vehicleControl2: 4 VehicleBus
 SG_ UI_PINToDriveEnabled : 6|1@1+ (1,0) [0|1] ""  Receiver
 SG_ UI_PINToDrivePassed : 7|1@1+ (1,0) [0|1] ""  Receiver
 SG_ UI_UMCUpdateInhibit : 2|1@1+ (1,0) [0|1] ""  Receiver
 SG_ UI_VCLEFTFeature1 : 15|1@1+ (1,0) [0|1] ""  Receiver
 SG_ UI_VCSECFeature1 : 14|1@1+ (1,0) [0|1] ""  Receiver
 SG_ UI_WCUpdateInhibit : 3|1@1+ (1,0) [0|1] ""  Receiver
 SG_ UI_alarmTriggerRequest : 13|1@1+ (1,0) [0|1] ""  Receiver
 SG_ UI_autoRollWindowsOnLockEnable : 29|1@1+ (1,0) [0|1] ""  Receiver
 SG_ UI_autopilotPowerStateRequest : 25|2@1+ (1,0) [0|2] ""  Receiver
 SG_ UI_batteryPreconditioningRequest : 23|1@1+ (1,0) [0|1] ""  Receiver
 SG_ UI_coastDownMode : 24|1@1+ (1,0) [0|1] ""  Receiver
 SG_ UI_conditionalLoggingEnabledVCSE : 31|1@1+ (1,0) [0|1] ""  Receiver
 SG_ UI_efuseMXResistanceEstArmed : 30|1@1+ (1,0) [0|1] ""  Receiver
 SG_ UI_freeRollModeRequest : 19|1@1+ (1,0) [0|1] ""  Receiver
 SG_ UI_gloveboxRequest : 0|1@1+ (1,0) [0|1] ""  Receiver
 SG_ UI_lightSwitch : 9|3@1+ (1,0) [0|4] ""  Receiver
 SG_ UI_locksPanelActive : 5|1@1+ (1,0) [0|1] ""  Receiver
 SG_ UI_readyToAddKey : 12|1@1+ (1,0) [0|1] ""  Receiver
 SG_ UI_shorted12VCellTestMode : 27|2@1+ (1,0) [0|2] ""  Receiver
 SG_ UI_soundHornOnLock : 4|1@1+ (1,0) [0|1] ""  Receiver
 SG_ UI_summonState : 16|2@1+ (1,0) [0|3] ""  Receiver
 SG_ UI_trunkRequest : 1|1@1+ (1,0) [0|1] ""  Receiver
 SG_ UI_userPresent : 18|1@1+ (1,0) [0|1] ""  Receiver
 SG_ UI_windowRequest : 20|3@1+ (1,0) [0|4] ""  Receiver

BO_ 949 DIS_alertMatrix2: 8 VEH
 SG_ DIS_a065_canHardwareBusB: 0|1@1+ (1,0) [0|0] "" X
 SG_ DIS_a066_canDataBusB: 1|1@1+ (1,0) [0|0] "" X
 SG_ DIS_a067_canOverrunBusB: 2|1@1+ (1,0) [0|0] "" X
 SG_ DIS_a070_12vSupplySensor: 5|1@1+ (1,0) [0|0] "" X
 SG_ DIS_a071_busDisconnected: 6|1@1+ (1,0) [0|0] "" X
 SG_ DIS_a072_gateDriveFaultCounter: 7|1@1+ (1,0) [0|0] "" X
 SG_ DIS_a073_motorSpeed: 8|1@1+ (1,0) [0|0] "" X
 SG_ DIS_a074_motorEncoder: 9|1@1+ (1,0) [0|0] "" X
 SG_ DIS_a075_motorSpeedMismatch: 10|1@1+ (1,0) [0|0] "" X
 SG_ DIS_a076_12vSupplyOV: 11|1@1+ (1,0) [0|0] "" X
 SG_ DIS_a077_12vSupplyUV: 12|1@1+ (1,0) [0|0] "" X
 SG_ DIS_a078_adcRefLow: 13|1@1+ (1,0) [0|0] "" X
 SG_ DIS_a079_adcRefHigh: 14|1@1+ (1,0) [0|0] "" X
 SG_ DIS_a086_hvilNotPresent: 21|1@1+ (1,0) [0|0] "" X
 SG_ DIS_a087_gtwMIA: 22|1@1+ (1,0) [0|0] "" X
 SG_ DIS_a088_uiMIA: 23|1@1+ (1,0) [0|0] "" X
 SG_ DIS_a090_pmMIA: 25|1@1+ (1,0) [0|0] "" X
 SG_ DIS_a091_espMIA: 26|1@1+ (1,0) [0|0] "" X
 SG_ DIS_a092_bmsMIA: 27|1@1+ (1,0) [0|0] "" X
 SG_ DIS_a093_canHardwareBusA: 28|1@1+ (1,0) [0|0] "" X
 SG_ DIS_a094_canDataBusA: 29|1@1+ (1,0) [0|0] "" X
 SG_ DIS_a095_canOverrunBusA: 30|1@1+ (1,0) [0|0] "" X
 SG_ DIS_a096_memoryError: 31|1@1+ (1,0) [0|0] "" X
 SG_ DIS_a097_eepromError: 32|1@1+ (1,0) [0|0] "" X
 SG_ DIS_a098_intTimeTooLong: 33|1@1+ (1,0) [0|0] "" X
 SG_ DIS_a099_threadOverrun: 34|1@1+ (1,0) [0|0] "" X
 SG_ DIS_a100_assertion: 35|1@1+ (1,0) [0|0] "" X
 SG_ DIS_a103_lowFlow: 38|1@1+ (1,0) [0|0] "" X
 SG_ DIS_a106_absMIA: 41|1@1+ (1,0) [0|0] "" X
 SG_ DIS_a108_stateTrans: 43|1@1+ (1,0) [0|0] "" X
 SG_ DIS_a110_brakeMIA: 45|1@1+ (1,0) [0|0] "" X
 SG_ DIS_a112_noPhaseCurrent: 47|1@1+ (1,0) [0|0] "" X
 SG_ DIS_a113_noFuncHeatsinkSensor: 48|1@1+ (1,0) [0|0] "" X
 SG_ DIS_a114_noMotorSpeed: 49|1@1+ (1,0) [0|0] "" X
 SG_ DIS_a115_heatsinkTempImbalance: 50|1@1+ (1,0) [0|0] "" X
 SG_ DIS_a116_powerConvIrrational: 51|1@1+ (1,0) [0|0] "" X
 SG_ DIS_a117_diMIA: 52|1@1+ (1,0) [0|0] "" X
 SG_ DIS_a121_motorControlRegulation: 56|1@1+ (1,0) [0|0] "" X
 SG_ DIS_a122_highStackUsage: 57|1@1+ (1,0) [0|0] "" X
 SG_ DIS_a123_lossMotorControl: 58|1@1+ (1,0) [0|0] "" X
 SG_ DIS_a126_limpMode: 61|1@1+ (1,0) [0|0] "" X
 SG_ DIS_a127_gracefulPowerOff: 62|1@1+ (1,0) [0|0] "" X

BO_ 950 ID3B6odometer: 4 VehicleBus
 SG_ Odometer3B6 : 0|32@1+ (0.001,0) [0|4294970] "KM"  Receiver

BO_ 952 UI_tpmsRCPsetting: 8 CH
 SG_ UI_setRCPFront: 16|8@1+ (0.025,0) [0|0] "bar" X
 SG_ UI_setRCPRear: 24|8@1+ (0.025,0) [0|0] "bar" X

BO_ 953 VCSEC_IsoTpPipeODIN: 8 GTW
 SG_ VCSEC_IsoTpPipeODIN0 : 0|8@1+ (1,0) [0|255] "" ODIN
 SG_ VCSEC_IsoTpPipeODIN1 : 8|8@1+ (1,0) [0|255] "" ODIN
 SG_ VCSEC_IsoTpPipeODIN2 : 16|8@1+ (1,0) [0|255] "" ODIN
 SG_ VCSEC_IsoTpPipeODIN3 : 24|8@1+ (1,0) [0|255] "" ODIN
 SG_ VCSEC_IsoTpPipeODIN4 : 32|8@1+ (1,0) [0|255] "" ODIN
 SG_ VCSEC_IsoTpPipeODIN5 : 40|8@1+ (1,0) [0|255] "" ODIN
 SG_ VCSEC_IsoTpPipeODIN6 : 48|8@1+ (1,0) [0|255] "" ODIN
 SG_ VCSEC_IsoTpPipeODIN7 : 56|8@1+ (1,0) [0|255] "" ODIN

BO_ 955 ID3BBUI_power: 2 VehicleBus
 SG_ UI_powerExpected : 0|8@1+ (1,0) [0|100] "kW"  Receiver
 SG_ UI_powerIdeal : 8|8@1+ (1,0) [0|100] "kW"  Receiver

BO_ 958 FC_alertMatrix5: 8 VEH
 SG_ FC_a257_GB_bmsMia: 0|1@1+ (1,0) [0|0] "" X
 SG_ FC_a258_GB_evseMia: 1|1@1+ (1,0) [0|0] "" X
 SG_ FC_a259_GB_vehTxBufOvf: 2|1@1+ (1,0) [0|0] "" X
 SG_ FC_a260_GB_vehRxBufOvf: 3|1@1+ (1,0) [0|0] "" X
 SG_ FC_a261_GB_evseTxBufOvf: 4|1@1+ (1,0) [0|0] "" X
 SG_ FC_a262_GB_evseRxBufOvf: 5|1@1+ (1,0) [0|0] "" X
 SG_ FC_a263_GB_hwProxTrip: 6|1@1+ (1,0) [0|0] "" X
 SG_ FC_a264_GB_ss2NotLow: 7|1@1+ (1,0) [0|0] "" X
 SG_ FC_a265_GB_bmsIncompatible: 8|1@1+ (1,0) [0|0] "" X
 SG_ FC_a266_GB_negPin_OT: 9|1@1+ (1,0) [0|0] "" X
 SG_ FC_a267_GB_posPin_OT: 10|1@1+ (1,0) [0|0] "" X
 SG_ FC_a268_GB_pcb_OT: 11|1@1+ (1,0) [0|0] "" X
 SG_ FC_a269_GB_unused: 12|1@1+ (1,0) [0|0] "" X
 SG_ FC_a270_GB_unused: 13|1@1+ (1,0) [0|0] "" X
 SG_ FC_a271_GB_unused: 14|1@1+ (1,0) [0|0] "" X
 SG_ FC_a272_GB_negToPosDeltaHi: 15|1@1+ (1,0) [0|0] "" X
 SG_ FC_a273_GB_negToPosDeltaLo: 16|1@1+ (1,0) [0|0] "" X
 SG_ FC_a274_GB_negToPcbDeltaHi: 17|1@1+ (1,0) [0|0] "" X
 SG_ FC_a275_GB_posToPcbDeltaHi: 18|1@1+ (1,0) [0|0] "" X
 SG_ FC_a276_GB_negToPcbDeltaLo: 19|1@1+ (1,0) [0|0] "" X
 SG_ FC_a277_GB_posToPcbDeltaLo: 20|1@1+ (1,0) [0|0] "" X
 SG_ FC_a278_GB_unused: 21|1@1+ (1,0) [0|0] "" X
 SG_ FC_a279_GB_evseOverCurrent: 22|1@1+ (1,0) [0|0] "" X
 SG_ FC_a280_GB_unused: 23|1@1+ (1,0) [0|0] "" X
 SG_ FC_a281_GB_ss2Deasserted: 24|1@1+ (1,0) [0|0] "" X
 SG_ FC_a282_GB_negTempHiFoldBk: 25|1@1+ (1,0) [0|0] "" X
 SG_ FC_a283_GB_posTempHiFoldBk: 26|1@1+ (1,0) [0|0] "" X
 SG_ FC_a284_GB_pcbTempHiFoldBk: 27|1@1+ (1,0) [0|0] "" X
 SG_ FC_a285_GB_proxDisconnected: 28|1@1+ (1,0) [0|0] "" X
 SG_ FC_a286_GB_evseConnUnlocked: 29|1@1+ (1,0) [0|0] "" X
 SG_ FC_a287_GB_vehConnUnlocked: 30|1@1+ (1,0) [0|0] "" X
 SG_ FC_a288_GB_isoVoltageLow: 31|1@1+ (1,0) [0|0] "" X
 SG_ FC_a289_GB_proxTimeout: 32|1@1+ (1,0) [0|0] "" X
 SG_ FC_a290_GB_pilotAcceptTimeout: 33|1@1+ (1,0) [0|0] "" X
 SG_ FC_a291_GB_vehDataTimeout: 34|1@1+ (1,0) [0|0] "" X
 SG_ FC_a292_GB_vehConLockTimeout: 35|1@1+ (1,0) [0|0] "" X
 SG_ FC_a293_GB_ss2LowTimeout: 36|1@1+ (1,0) [0|0] "" X
 SG_ FC_a294_GB_evseDataTimeout: 37|1@1+ (1,0) [0|0] "" X
 SG_ FC_a295_GB_vehReadyTimeout: 38|1@1+ (1,0) [0|0] "" X
 SG_ FC_a296_GB_evseIsoTestTimeout: 39|1@1+ (1,0) [0|0] "" X
 SG_ FC_a297_GB_chargingBusTimeout: 40|1@1+ (1,0) [0|0] "" X
 SG_ FC_a298_GB_bmsCtrCloseTimeout: 41|1@1+ (1,0) [0|0] "" X
 SG_ FC_a299_GB_evseReadyTimeout: 42|1@1+ (1,0) [0|0] "" X
 SG_ FC_a300_GB_startupProblem: 43|1@1+ (1,0) [0|0] "" X
 SG_ FC_a301_GB_chargingProblem: 44|1@1+ (1,0) [0|0] "" X
 SG_ FC_a302_GB_vRegBrownout: 45|1@1+ (1,0) [0|0] "" X
 SG_ FC_a303_GB_negRecogTimeout: 46|1@1+ (1,0) [0|0] "" X
 SG_ FC_a304_GB_evseIncompatible: 47|1@1+ (1,0) [0|0] "" X
 SG_ FC_a305_GB_posRecogTimeout: 48|1@1+ (1,0) [0|0] "" X
 SG_ FC_a306_GB_vehReadyDeasserted: 49|1@1+ (1,0) [0|0] "" X
 SG_ FC_a307_GB_fcContOpenTimeout: 50|1@1+ (1,0) [0|0] "" X
 SG_ FC_a308_GB_evseConLockTimeout: 51|1@1+ (1,0) [0|0] "" X
 SG_ FC_a309_GB_unused: 52|1@1+ (1,0) [0|0] "" X
 SG_ FC_a310_GB_vehicleIdTimeout: 53|1@1+ (1,0) [0|0] "" X
 SG_ FC_a311_GB_battParamsTimeout: 54|1@1+ (1,0) [0|0] "" X
 SG_ FC_a312_GB_evseLimitsTimeout: 55|1@1+ (1,0) [0|0] "" X

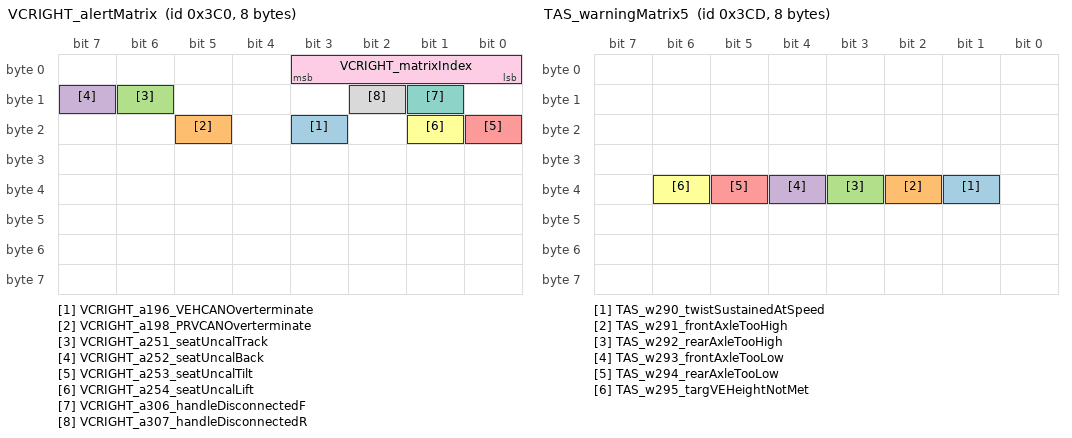
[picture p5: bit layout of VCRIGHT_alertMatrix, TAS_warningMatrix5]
BO_ 960 VCRIGHT_alertMatrix: 8 GTW
 SG_ VCRIGHT_a196_VEHCANOverterminate : 19|1@1+ (1,0) [0|1] "" ODIN,UI
 SG_ VCRIGHT_a198_PRVCANOverterminate : 21|1@1+ (1,0) [0|1] "" ODIN,UI
 SG_ VCRIGHT_a251_seatUncalTrack : 14|1@1+ (1,0) [0|1] "" ODIN,UI
 SG_ VCRIGHT_a252_seatUncalBack : 15|1@1+ (1,0) [0|1] "" ODIN,UI
 SG_ VCRIGHT_a253_seatUncalTilt : 16|1@1+ (1,0) [0|1] "" ODIN,UI
 SG_ VCRIGHT_a254_seatUncalLift : 17|1@1+ (1,0) [0|1] "" ODIN,UI
 SG_ VCRIGHT_a306_handleDisconnectedF : 9|1@1+ (1,0) [0|1] "" ODIN,UI
 SG_ VCRIGHT_a307_handleDisconnectedR : 10|1@1+ (1,0) [0|1] "" ODIN,UI
 SG_ VCRIGHT_matrixIndex : 0|4@1+ (1,0) [0|15] "" UI

BO_ 962 ID3C2VCLEFT_switchStatus: 8 VehicleBus
 SG_ VCLEFT_switchStatusIndex M : 0|2@1+ (1,0) [0|2] ""  Receiver
 SG_ VCLEFT_2RowSeatBothFoldFlatSwitc m1 : 40|1@1+ (1,0) [0|1] ""  Receiver
 SG_ VCLEFT_2RowSeatCenterSwitch m1 : 37|1@1+ (1,0) [0|1] ""  Receiver
 SG_ VCLEFT_2RowSeatLeftFoldFlatSwitc m1 : 38|1@1+ (1,0) [0|1] ""  Receiver
 SG_ VCLEFT_2RowSeatReclineSwitch m1 : 36|1@1+ (1,0) [0|1] ""  Receiver
 SG_ VCLEFT_2RowSeatRightFoldFlatSwit m1 : 39|1@1+ (1,0) [0|1] ""  Receiver
 SG_ VCLEFT_brakePressed m0 : 60|1@1+ (1,0) [0|1] ""  Receiver
 SG_ VCLEFT_brakeSwitchPressed m0 : 4|1@1+ (1,0) [0|1] ""  Receiver
 SG_ VCLEFT_btnWindowAutoDownLR m1 : 35|1@1+ (1,0) [0|1] ""  Receiver
 SG_ VCLEFT_btnWindowAutoUpLR m1 : 33|1@1+ (1,0) [0|1] ""  Receiver
 SG_ VCLEFT_btnWindowDownLR m1 : 34|1@1+ (1,0) [0|1] ""  Receiver
 SG_ VCLEFT_btnWindowSwPackAutoDownLF m0 : 35|1@1+ (1,0) [0|1] ""  Receiver
 SG_ VCLEFT_btnWindowSwPackAutoDownLR m0 : 39|1@1+ (1,0) [0|1] ""  Receiver
 SG_ VCLEFT_btnWindowSwPackAutoDownRF m0 : 43|1@1+ (1,0) [0|1] ""  Receiver
 SG_ VCLEFT_btnWindowSwPackAutoDownRR m0 : 47|1@1+ (1,0) [0|1] ""  Receiver
 SG_ VCLEFT_btnWindowSwPackAutoUpLF m0 : 33|1@1+ (1,0) [0|1] ""  Receiver
 SG_ VCLEFT_btnWindowSwPackAutoUpLR m0 : 37|1@1+ (1,0) [0|1] ""  Receiver
 SG_ VCLEFT_btnWindowSwPackAutoUpRF m0 : 41|1@1+ (1,0) [0|1] ""  Receiver
 SG_ VCLEFT_btnWindowSwPackAutoUpRR m0 : 45|1@1+ (1,0) [0|1] ""  Receiver
 SG_ VCLEFT_btnWindowSwPackDownLF m0 : 34|1@1+ (1,0) [0|1] ""  Receiver
 SG_ VCLEFT_btnWindowSwPackDownLR m0 : 38|1@1+ (1,0) [0|1] ""  Receiver
 SG_ VCLEFT_btnWindowSwPackDownRF m0 : 42|1@1+ (1,0) [0|1] ""  Receiver
 SG_ VCLEFT_btnWindowSwPackDownRR m0 : 46|1@1+ (1,0) [0|1] ""  Receiver
 SG_ VCLEFT_btnWindowSwPackUpLF m0 : 32|1@1+ (1,0) [0|1] ""  Receiver
 SG_ VCLEFT_btnWindowSwPackUpLR m0 : 36|1@1+ (1,0) [0|1] ""  Receiver
 SG_ VCLEFT_btnWindowSwPackUpRF m0 : 40|1@1+ (1,0) [0|1] ""  Receiver
 SG_ VCLEFT_btnWindowSwPackUpRR m0 : 44|1@1+ (1,0) [0|1] ""  Receiver
 SG_ VCLEFT_btnWindowUpLR m1 : 32|1@1+ (1,0) [0|1] ""  Receiver
 SG_ VCLEFT_frontBuckleSwitch m0 : 48|2@1+ (1,0) [0|3] ""  Receiver
 SG_ VCLEFT_frontOccupancySwitch m0 : 50|2@1+ (1,0) [0|3] ""  Receiver
 SG_ VCLEFT_frontSeatBackrestBack m0 : 20|2@1+ (1,0) [0|3] ""  Receiver
 SG_ VCLEFT_frontSeatBackrestForward m0 : 22|2@1+ (1,0) [0|3] ""  Receiver
 SG_ VCLEFT_frontSeatLiftDown m0 : 16|2@1+ (1,0) [0|3] ""  Receiver
 SG_ VCLEFT_frontSeatLiftUp m0 : 18|2@1+ (1,0) [0|3] ""  Receiver
 SG_ VCLEFT_frontSeatLumbarDown m0 : 24|2@1+ (1,0) [0|3] ""  Receiver
 SG_ VCLEFT_frontSeatLumbarIn m0 : 28|2@1+ (1,0) [0|3] ""  Receiver
 SG_ VCLEFT_frontSeatLumbarOut m0 : 30|2@1+ (1,0) [0|3] ""  Receiver
 SG_ VCLEFT_frontSeatLumbarUp m0 : 26|2@1+ (1,0) [0|3] ""  Receiver
 SG_ VCLEFT_frontSeatTiltDown m0 : 12|2@1+ (1,0) [0|3] ""  Receiver
 SG_ VCLEFT_frontSeatTiltUp m0 : 14|2@1+ (1,0) [0|3] ""  Receiver
 SG_ VCLEFT_frontSeatTrackBack m0 : 8|2@1+ (1,0) [0|3] ""  Receiver
 SG_ VCLEFT_frontSeatTrackForward m0 : 10|2@1+ (1,0) [0|3] ""  Receiver
 SG_ VCLEFT_hazardButtonPressed m0 : 3|1@1+ (1,0) [0|1] ""  Receiver
 SG_ VCLEFT_hornSwitchPressed m0 : 2|1@1+ (1,0) [0|1] ""  Receiver
 SG_ VCLEFT_rearCenterBuckleSwitch m0 : 62|2@1+ (1,0) [0|3] ""  Receiver
 SG_ VCLEFT_rearCenterOccupancySwitch m0 : 54|2@1+ (1,0) [0|3] ""  Receiver
 SG_ VCLEFT_rearHVACButtonPressed m0 : 61|1@1+ (1,0) [0|1] ""  Receiver
 SG_ VCLEFT_rearLeftBuckleSwitch m0 : 52|2@1+ (1,0) [0|3] ""  Receiver
 SG_ VCLEFT_rearLeftOccupancySwitch m0 : 56|2@1+ (1,0) [0|3] ""  Receiver
 SG_ VCLEFT_rearRightOccupancySwitch m0 : 58|2@1+ (1,0) [0|3] ""  Receiver
 SG_ VCLEFT_rightMirrorTilt m0 : 5|3@1+ (1,0) [0|4] ""  Receiver
 SG_ VCLEFT_swcLeftDoublePress m1 : 41|1@1+ (1,0) [0|1] ""  Receiver
 SG_ VCLEFT_swcLeftPressed m1 : 5|2@1+ (1,0) [0|3] ""  Receiver
 SG_ VCLEFT_swcLeftScrollTicks m1 : 16|6@1- (1,0) [-32|31] ""  Receiver
 SG_ VCLEFT_swcLeftTiltLeft m1 : 14|2@1+ (1,0) [0|3] ""  Receiver
 SG_ VCLEFT_swcLeftTiltRight m1 : 3|2@1+ (1,0) [0|3] ""  Receiver
 SG_ VCLEFT_swcRightDoublePress m1 : 42|1@1+ (1,0) [0|1] ""  Receiver
 SG_ VCLEFT_swcRightPressed m1 : 12|2@1+ (1,0) [0|3] ""  Receiver
 SG_ VCLEFT_swcRightScrollTicks m1 : 24|6@1- (1,0) [-32|31] ""  Receiver
 SG_ VCLEFT_swcRightTiltLeft m1 : 8|2@1+ (1,0) [0|3] ""  Receiver
 SG_ VCLEFT_swcRightTiltRight m1 : 10|2@1+ (1,0) [0|3] ""  Receiver

BO_ 963 ID3C3VCRIGHT_switchStatus: 7 VehicleBus
 SG_ VCRIGHT_2RowSeatReclineSwitch : 54|1@1+ (1,0) [0|1] ""  Receiver
 SG_ VCRIGHT_btnWindowAutoDownRF : 27|1@1+ (1,0) [0|1] ""  Receiver
 SG_ VCRIGHT_btnWindowAutoDownRR : 31|1@1+ (1,0) [0|1] ""  Receiver
 SG_ VCRIGHT_btnWindowAutoUpRF : 25|1@1+ (1,0) [0|1] ""  Receiver
 SG_ VCRIGHT_btnWindowAutoUpRR : 29|1@1+ (1,0) [0|1] ""  Receiver
 SG_ VCRIGHT_btnWindowDownRF : 26|1@1+ (1,0) [0|1] ""  Receiver
 SG_ VCRIGHT_btnWindowDownRR : 30|1@1+ (1,0) [0|1] ""  Receiver
 SG_ VCRIGHT_btnWindowSwPackAutoDwnLF : 35|1@1+ (1,0) [0|1] ""  Receiver
 SG_ VCRIGHT_btnWindowSwPackAutoDwnLR : 39|1@1+ (1,0) [0|1] ""  Receiver
 SG_ VCRIGHT_btnWindowSwPackAutoDwnRR : 52|1@1+ (1,0) [0|1] ""  Receiver
 SG_ VCRIGHT_btnWindowSwPackAutoUpLF : 33|1@1+ (1,0) [0|1] ""  Receiver
 SG_ VCRIGHT_btnWindowSwPackAutoUpLR : 37|1@1+ (1,0) [0|1] ""  Receiver
 SG_ VCRIGHT_btnWindowSwPackAutoUpRR : 50|1@1+ (1,0) [0|1] ""  Receiver
 SG_ VCRIGHT_btnWindowSwPackDownLF : 34|1@1+ (1,0) [0|1] ""  Receiver
 SG_ VCRIGHT_btnWindowSwPackDownLR : 38|1@1+ (1,0) [0|1] ""  Receiver
 SG_ VCRIGHT_btnWindowSwPackDownRR : 51|1@1+ (1,0) [0|1] ""  Receiver
 SG_ VCRIGHT_btnWindowSwPackUpLF : 32|1@1+ (1,0) [0|1] ""  Receiver
 SG_ VCRIGHT_btnWindowSwPackUpLR : 36|1@1+ (1,0) [0|1] ""  Receiver
 SG_ VCRIGHT_btnWindowSwPackUpRR : 49|1@1+ (1,0) [0|1] ""  Receiver
 SG_ VCRIGHT_btnWindowUpRF : 24|1@1+ (1,0) [0|1] ""  Receiver
 SG_ VCRIGHT_btnWindowUpRR : 28|1@1+ (1,0) [0|1] ""  Receiver
 SG_ VCRIGHT_frontBuckleSwitch : 40|2@1+ (1,0) [0|3] ""  Receiver
 SG_ VCRIGHT_frontOccupancySwitch : 42|2@1+ (1,0) [0|3] ""  Receiver
 SG_ VCRIGHT_frontSeatBackrestBack : 12|2@1+ (1,0) [0|3] ""  Receiver
 SG_ VCRIGHT_frontSeatBackrestForward : 14|2@1+ (1,0) [0|3] ""  Receiver
 SG_ VCRIGHT_frontSeatLiftDown : 8|2@1+ (1,0) [0|3] ""  Receiver
 SG_ VCRIGHT_frontSeatLiftUp : 10|2@1+ (1,0) [0|3] ""  Receiver
 SG_ VCRIGHT_frontSeatLumbarDown : 16|2@1+ (1,0) [0|3] ""  Receiver
 SG_ VCRIGHT_frontSeatLumbarIn : 20|2@1+ (1,0) [0|3] ""  Receiver
 SG_ VCRIGHT_frontSeatLumbarOut : 22|2@1+ (1,0) [0|3] ""  Receiver
 SG_ VCRIGHT_frontSeatLumbarUp : 18|2@1+ (1,0) [0|3] ""  Receiver
 SG_ VCRIGHT_frontSeatTiltDown : 4|2@1+ (1,0) [0|3] ""  Receiver
 SG_ VCRIGHT_frontSeatTiltUp : 6|2@1+ (1,0) [0|3] ""  Receiver
 SG_ VCRIGHT_frontSeatTrackBack : 0|2@1+ (1,0) [0|3] ""  Receiver
 SG_ VCRIGHT_frontSeatTrackForward : 2|2@1+ (1,0) [0|3] ""  Receiver
 SG_ VCRIGHT_liftgateShutfaceSwitchPr : 53|1@1+ (1,0) [0|1] ""  Receiver
 SG_ VCRIGHT_rearCenterBuckleSwitch : 44|2@1+ (1,0) [0|3] ""  Receiver
 SG_ VCRIGHT_rearRightBuckleSwitch : 46|2@1+ (1,0) [0|3] ""  Receiver
 SG_ VCRIGHT_trunkExtReleasePressed : 48|1@1+ (1,0) [0|1] ""  Receiver

BO_ 964 PCS_info: 8 VEH
 SG_ PCS_infoIndex M: 0|8@1+ (1,0) [0|0] "" X
 SG_ PCS_buildType m10: 8|8@1+ (1,0) [0|0] "" X
 SG_ PCS_buildConfigId m10: 16|16@1+ (1,0) [0|0] "" X
 SG_ PCS_hardwareId m10: 32|16@1+ (1,0) [0|0] "" X
 SG_ PCS_componentId m10: 48|16@1+ (1,0) [0|0] "" X
 SG_ PCS_pcbaId m11: 16|8@1+ (1,0) [0|0] "" X
 SG_ PCS_assemblyId m11: 24|8@1+ (1,0) [0|0] "" X
 SG_ PCS_usageId m11: 32|16@1+ (1,0) [0|0] "" X
 SG_ PCS_subUsageId m11: 48|16@1+ (1,0) [0|0] "" X
 SG_ PCS_platformType m13: 8|8@1+ (1,0) [0|0] "" X
 SG_ PCS_appCrc m13: 32|32@1+ (1,0) [0|0] "" X
 SG_ PCS_cpu2AppCrc m16: 32|32@1+ (1,0) [0|0] "" X
 SG_ PCS_appGitHash m17: 10|54@1+ (4,0) [0|0] "" X
 SG_ PCS_bootGitHash m18: 10|54@1+ (4,0) [0|0] "" X
 SG_ PCS_bootUdsProtoVersion m20: 8|8@1+ (1,0) [0|0] "" X
 SG_ PCS_bootCrc m20: 32|32@1+ (1,0) [0|0] "" X
 SG_ PCS_partNumChar01 m25: 8|8@1+ (1,0) [0|0] "" X
 SG_ PCS_partNumChar02 m25: 16|8@1+ (1,0) [0|0] "" X
 SG_ PCS_partNumChar03 m25: 24|8@1+ (1,0) [0|0] "" X
 SG_ PCS_partNumChar04 m25: 32|8@1+ (1,0) [0|0] "" X
 SG_ PCS_partNumChar05 m25: 40|8@1+ (1,0) [0|0] "" X
 SG_ PCS_partNumChar06 m25: 48|8@1+ (1,0) [0|0] "" X
 SG_ PCS_partNumChar07 m25: 56|8@1+ (1,0) [0|0] "" X
 SG_ PCS_partNumChar08 m26: 8|8@1+ (1,0) [0|0] "" X
 SG_ PCS_partNumChar09 m26: 16|8@1+ (1,0) [0|0] "" X
 SG_ PCS_partNumChar10 m26: 24|8@1+ (1,0) [0|0] "" X
 SG_ PCS_partNumChar11 m26: 32|8@1+ (1,0) [0|0] "" X
 SG_ PCS_partNumChar12 m26: 40|8@1+ (1,0) [0|0] "" X
 SG_ PCS_partNumChar13 m26: 48|8@1+ (1,0) [0|0] "" X
 SG_ PCS_partNumChar14 m26: 56|8@1+ (1,0) [0|0] "" X
 SG_ PCS_partNumChar15 m27: 8|8@1+ (1,0) [0|0] "" X
 SG_ PCS_partNumChar16 m27: 16|8@1+ (1,0) [0|0] "" X
 SG_ PCS_partNumChar17 m27: 24|8@1+ (1,0) [0|0] "" X
 SG_ PCS_partNumChar18 m27: 32|8@1+ (1,0) [0|0] "" X
 SG_ PCS_partNumChar19 m27: 40|8@1+ (1,0) [0|0] "" X
 SG_ PCS_partNumChar20 m27: 48|8@1+ (1,0) [0|0] "" X
 SG_ PCS_serialNumChar01 m29: 8|8@1+ (1,0) [0|0] "" X
 SG_ PCS_serialNumChar02 m29: 16|8@1+ (1,0) [0|0] "" X
 SG_ PCS_serialNumChar03 m29: 24|8@1+ (1,0) [0|0] "" X
 SG_ PCS_serialNumChar04 m29: 32|8@1+ (1,0) [0|0] "" X
 SG_ PCS_serialNumChar05 m29: 40|8@1+ (1,0) [0|0] "" X
 SG_ PCS_serialNumChar06 m29: 48|8@1+ (1,0) [0|0] "" X
 SG_ PCS_serialNumChar07 m29: 56|8@1+ (1,0) [0|0] "" X
 SG_ PCS_serialNumChar08 m30: 8|8@1+ (1,0) [0|0] "" X
 SG_ PCS_serialNumChar09 m30: 16|8@1+ (1,0) [0|0] "" X
 SG_ PCS_serialNumChar10 m30: 24|8@1+ (1,0) [0|0] "" X
 SG_ PCS_serialNumChar11 m30: 32|8@1+ (1,0) [0|0] "" X
 SG_ PCS_serialNumChar12 m30: 40|8@1+ (1,0) [0|0] "" X
 SG_ PCS_serialNumChar13 m30: 48|8@1+ (1,0) [0|0] "" X
 SG_ PCS_serialNumChar14 m30: 56|8@1+ (1,0) [0|0] "" X

BO_ 965 DIR_alertMatrix3: 8 GTW
 SG_ DIR_a154_resolver : 25|1@1+ (1,0) [0|1] "" ODIN,UI

BO_ 968 EPBL_alertMatrix: 8 VEH
 SG_ EPBL_matrixIndex M: 0|4@1+ (1,0) [0|0] "" X
 SG_ EPBL_a001_WatchdogReset m0: 4|1@1+ (1,0) [0|0] "" X
 SG_ EPBL_a002_PowerLossReset m0: 5|1@1+ (1,0) [0|0] "" X
 SG_ EPBL_a003_SWAssertion m0: 6|1@1+ (1,0) [0|0] "" X
 SG_ EPBL_a010_ExtSupplyVoltError m0: 13|1@1+ (1,0) [0|0] "" X
 SG_ EPBL_a012_CPUReset m0: 15|1@1+ (1,0) [0|0] "" X
 SG_ EPBL_a013_AlertManagerFault m0: 16|1@1+ (1,0) [0|0] "" X
 SG_ EPBL_a015_NVMMAlert m0: 18|1@1+ (1,0) [0|0] "" X
 SG_ EPBL_a021_TaskSchedulerError m0: 24|1@1+ (1,0) [0|0] "" X
 SG_ EPBL_a022_TaskInitError m0: 25|1@1+ (1,0) [0|0] "" X
 SG_ EPBL_a031_UDSActive m0: 34|1@1+ (1,0) [0|0] "" X
 SG_ EPBL_a041_HighCPULoad m0: 44|1@1+ (1,0) [0|0] "" X
 SG_ EPBL_a042_HighStackUsage m0: 45|1@1+ (1,0) [0|0] "" X
 SG_ EPBL_a043_Task1msError m0: 46|1@1+ (1,0) [0|0] "" X
 SG_ EPBL_a044_Task10msError m0: 47|1@1+ (1,0) [0|0] "" X
 SG_ EPBL_a045_Task100msError m0: 48|1@1+ (1,0) [0|0] "" X
 SG_ EPBL_a046_Task1000msError m0: 49|1@1+ (1,0) [0|0] "" X
 SG_ EPBL_a059_inputResistanceHigh m0: 62|1@1+ (1,0) [0|0] "" X
 SG_ EPBL_a060_engineeringBuild m0: 63|1@1+ (1,0) [0|0] "" X
 SG_ EPBL_a061_XCPConnected m1: 4|1@1+ (1,0) [0|0] "" X
 SG_ EPBL_a062_XCPWasConnected m1: 5|1@1+ (1,0) [0|0] "" X
 SG_ EPBL_a063_SwitchFault m1: 6|1@1+ (1,0) [0|0] "" X
 SG_ EPBL_a064_busSleepReqTimeout m1: 7|1@1+ (1,0) [0|0] "" X
 SG_ EPBL_a097_CMP_MIA m1: 40|1@1+ (1,0) [0|0] "" X
 SG_ EPBL_a098_DI_THERMAL_MIA m1: 41|1@1+ (1,0) [0|0] "" X
 SG_ EPBL_a099_PARK_MIA m1: 42|1@1+ (1,0) [0|0] "" X
 SG_ EPBL_a100_CANbus_MIA m1: 43|1@1+ (1,0) [0|0] "" X
 SG_ EPBL_a101_PM_MIA m1: 44|1@1+ (1,0) [0|0] "" X
 SG_ EPBL_a102_PTC_MIA m1: 45|1@1+ (1,0) [0|0] "" X
 SG_ EPBL_a103_CP_MIA m1: 46|1@1+ (1,0) [0|0] "" X
 SG_ EPBL_a104_DAS_MIA m1: 47|1@1+ (1,0) [0|0] "" X
 SG_ EPBL_a105_TAS_MIA m1: 48|1@1+ (1,0) [0|0] "" X
 SG_ EPBL_a106_PCS_MIA m1: 49|1@1+ (1,0) [0|0] "" X
 SG_ EPBL_a107_BMS_MIA m1: 50|1@1+ (1,0) [0|0] "" X
 SG_ EPBL_a108_DIS_MIA m1: 51|1@1+ (1,0) [0|0] "" X
 SG_ EPBL_a109_RCM_MIA m1: 52|1@1+ (1,0) [0|0] "" X
 SG_ EPBL_a110_GTW_MIA m1: 53|1@1+ (1,0) [0|0] "" X
 SG_ EPBL_a111_EPBR_MIA m1: 54|1@1+ (1,0) [0|0] "" X
 SG_ EPBL_a112_EPBL_MIA m1: 55|1@1+ (1,0) [0|0] "" X
 SG_ EPBL_a113_UI_MIA m1: 56|1@1+ (1,0) [0|0] "" X
 SG_ EPBL_a114_ESP_MIA m1: 57|1@1+ (1,0) [0|0] "" X
 SG_ EPBL_a115_VCSEC_MIA m1: 58|1@1+ (1,0) [0|0] "" X
 SG_ EPBL_a116_VCRIGHT_MIA m1: 59|1@1+ (1,0) [0|0] "" X
 SG_ EPBL_a117_VCLEFT_MIA m1: 60|1@1+ (1,0) [0|0] "" X
 SG_ EPBL_a118_VCFRONT_MIA m1: 61|1@1+ (1,0) [0|0] "" X
 SG_ EPBL_a119_SCCM_MIA m1: 62|1@1+ (1,0) [0|0] "" X
 SG_ EPBL_a120_DI_DRIVE_MIA m1: 63|1@1+ (1,0) [0|0] "" X
 SG_ EPBL_a121_nDriveFault m2: 4|1@1+ (1,0) [0|0] "" X
 SG_ EPBL_a122_Oc m2: 5|1@1+ (1,0) [0|0] "" X
 SG_ EPBL_a123_Uc m2: 6|1@1+ (1,0) [0|0] "" X
 SG_ EPBL_a124_calOutOfBounds m2: 7|1@1+ (1,0) [0|0] "" X
 SG_ EPBL_a125_IdleVMismatch m2: 8|1@1+ (1,0) [0|0] "" X
 SG_ EPBL_a126_MotorNVoltLow m2: 9|1@1+ (1,0) [0|0] "" X
 SG_ EPBL_a127_MotorNVoltHigh m2: 10|1@1+ (1,0) [0|0] "" X
 SG_ EPBL_a128_MotorPVoltHigh m2: 11|1@1+ (1,0) [0|0] "" X
 SG_ EPBL_a134_NvOv m2: 17|1@1+ (1,0) [0|0] "" X
 SG_ EPBL_a135_NvUv m2: 18|1@1+ (1,0) [0|0] "" X
 SG_ EPBL_a136_PvOv m2: 19|1@1+ (1,0) [0|0] "" X
 SG_ EPBL_a137_PvUv m2: 20|1@1+ (1,0) [0|0] "" X
 SG_ EPBL_a138_NVMWriteTime m2: 21|1@1+ (1,0) [0|0] "" X
 SG_ EPBL_a141_invalidState m2: 24|1@1+ (1,0) [0|0] "" X
 SG_ EPBL_a170_12vOv m2: 53|1@1+ (1,0) [0|0] "" X
 SG_ EPBL_a171_12vUv m2: 54|1@1+ (1,0) [0|0] "" X
 SG_ EPBL_a172_SPI_MIA m2: 55|1@1+ (1,0) [0|0] "" X
 SG_ EPBL_a173_hiCurrentMissing m2: 56|1@1+ (1,0) [0|0] "" X
 SG_ EPBL_a174_csmReleaseFailed m2: 57|1@1+ (1,0) [0|0] "" X
 SG_ EPBL_a175_csmReleaseRetry m2: 58|1@1+ (1,0) [0|0] "" X
 SG_ EPBL_a176_csmApplyFailed m2: 59|1@1+ (1,0) [0|0] "" X
 SG_ EPBL_a177_csmApplyRetry m2: 60|1@1+ (1,0) [0|0] "" X
 SG_ EPBL_a178_caliperStateUnknown m2: 61|1@1+ (1,0) [0|0] "" X
 SG_ EPBL_a179_epbProblem m2: 62|1@1+ (1,0) [0|0] "" X
 SG_ EPBL_a180_dynamicActive m2: 63|1@1+ (1,0) [0|0] "" X
 SG_ EPBL_a181_TooSteepGradeToPark m3: 4|1@1+ (1,0) [0|0] "" X
 SG_ EPBL_a182_OneEPBAppliedUnsecEnv m3: 5|1@1+ (1,0) [0|0] "" X
 SG_ EPBL_a183_cdpNotAvailable m3: 6|1@1+ (1,0) [0|0] "" X
 SG_ EPBL_a184_dynamicParkAbort m3: 7|1@1+ (1,0) [0|0] "" X
 SG_ EPBL_a185_summonAborted m3: 8|1@1+ (1,0) [0|0] "" X
 SG_ EPBL_a186_externalParkAbort m3: 9|1@1+ (1,0) [0|0] "" X
 SG_ EPBL_a187_cdpDynamic m3: 10|1@1+ (1,0) [0|0] "" X
 SG_ EPBL_a188_epbDynamic m3: 11|1@1+ (1,0) [0|0] "" X
 SG_ EPBL_a189_epbDynamicParkCanceled m3: 12|1@1+ (1,0) [0|0] "" X
 SG_ EPBL_a190_csmApplyDegraded m3: 13|1@1+ (1,0) [0|0] "" X
 SG_ EPBL_a191_csmReleaseDegraded m3: 14|1@1+ (1,0) [0|0] "" X
 SG_ EPBL_a195_parkForDriverIsLeaving m3: 18|1@1+ (1,0) [0|0] "" X
 SG_ EPBL_a200_PmUnparkNotAllowed m3: 23|1@1+ (1,0) [0|0] "" X
 SG_ EPBL_a201_hwBrakeTypeMismatch m3: 24|1@1+ (1,0) [0|0] "" X
 SG_ EPBL_a216_SPI_MIA_debugData1 m3: 39|1@1+ (1,0) [0|0] "" X
 SG_ EPBL_a217_SPI_MIA_debugData2 m3: 40|1@1+ (1,0) [0|0] "" X
 SG_ EPBL_a241_diOutputLocked m4: 4|1@1+ (1,0) [0|0] "" X
 SG_ EPBL_a242_hvOutputLocked m4: 5|1@1+ (1,0) [0|0] "" X
 SG_ EPBL_a243_bdwUnavailable m4: 6|1@1+ (1,0) [0|0] "" X
 SG_ EPBL_a244_WinchModeActive m4: 7|1@1+ (1,0) [0|0] "" X
 SG_ EPBL_a245_serviceModeActive m4: 8|1@1+ (1,0) [0|0] "" X
 SG_ EPBL_a246_idleFaultApply m4: 9|1@1+ (1,0) [0|0] "" X
 SG_ EPBL_a247_csmDynamicApplyRetry m4: 10|1@1+ (1,0) [0|0] "" X
 SG_ EPBL_a248_csmDynamicApplyFailed m4: 11|1@1+ (1,0) [0|0] "" X
 SG_ EPBL_a249_idleFaultRelease m4: 12|1@1+ (1,0) [0|0] "" X
 SG_ EPBL_a250_WinchModeCanceled m4: 13|1@1+ (1,0) [0|0] "" X
 SG_ EPBL_a251_currentVarianceHigh m4: 14|1@1+ (1,0) [0|0] "" X

BO_ 969 VCSEC_BLEEndpointInfo: 8 VEH
 SG_ VCSEC_BLEEndpointInfoIndex M: 0|3@1+ (1,0) [0|0] "" X
 SG_ VCSEC_BLELEFTCrc m0: 8|32@1+ (1,0) [0|0] "" X
 SG_ VCSEC_BLELEFTComponentID m0: 40|16@1+ (1,0) [0|0] "" X
 SG_ VCSEC_BLELEFTPcbaID m0: 56|8@1+ (1,0) [0|0] "" X
 SG_ VCSEC_BLERIGHTCrc m1: 8|32@1+ (1,0) [0|0] "" X
 SG_ VCSEC_BLERIGHTComponentID m1: 40|16@1+ (1,0) [0|0] "" X
 SG_ VCSEC_BLERIGHTPcbaID m1: 56|8@1+ (1,0) [0|0] "" X
 SG_ VCSEC_BLEREARCrc m2: 8|32@1+ (1,0) [0|0] "" X
 SG_ VCSEC_BLEREARComponentID m2: 40|16@1+ (1,0) [0|0] "" X
 SG_ VCSEC_BLEREARPcbaID m2: 56|8@1+ (1,0) [0|0] "" X
 SG_ VCSEC_BLECENTERCrc m3: 8|32@1+ (1,0) [0|0] "" X
 SG_ VCSEC_BLECENTERComponentID m3: 40|16@1+ (1,0) [0|0] "" X
 SG_ VCSEC_BLECENTERPcbaID m3: 56|8@1+ (1,0) [0|0] "" X
 SG_ VCSEC_BLELEFTAppGitHashByte m4: 10|54@1+ (4,0) [0|0] "" X
 SG_ VCSEC_BLERIGHTAppGitHashByte m5: 10|54@1+ (4,0) [0|0] "" X
 SG_ VCSEC_BLEREARAppGitHashByte m6: 10|54@1+ (4,0) [0|0] "" X
 SG_ VCSEC_BLECENTERAppGitHashByte m7: 10|54@1+ (4,0) [0|0] "" X

BO_ 970 APS_status: 7 GTW
 SG_ APS_canMaster : 8|2@1+ (1,0) [0|3] "" ODIN,SUI,UI,VITALS

BO_ 973 TAS_warningMatrix5: 8 VEH
 SG_ TAS_w290_twistSustainedAtSpeed: 33|1@1+ (1,0) [0|0] "" X
 SG_ TAS_w291_frontAxleTooHigh: 34|1@1+ (1,0) [0|0] "" X
 SG_ TAS_w292_rearAxleTooHigh: 35|1@1+ (1,0) [0|0] "" X
 SG_ TAS_w293_frontAxleTooLow: 36|1@1+ (1,0) [0|0] "" X
 SG_ TAS_w294_rearAxleTooLow: 37|1@1+ (1,0) [0|0] "" X
 SG_ TAS_w295_targVEHeightNotMet: 38|1@1+ (1,0) [0|0] "" X

BO_ 977 EPAS3P_angleCalibration: 8 GTW
 SG_ EPAS3P_appliedAngleOffset : 0|8@1+ (0.1,-12.8) [-12.8|12.7] "deg" ODIN,SUI,VITALS

BO_ 978 ID3D2TotalChargeDischarge: 8 VehicleBus
 SG_ TotalDischargeKWh3D2 : 0|32@1+ (0.001,0) [0|4294970] "kWh"  Receiver
 SG_ TotalChargeKWh3D2 : 32|32@1+ (0.001,0) [0|4294970] "kWh"  Receiver

BO_ 979 UI_airbagCutoffStatus: 1 VEH
 SG_ UI_airbagCutoffSwState: 0|2@1+ (1,0) [0|0] "" X
 SG_ UI_warningIndicatorStatus: 2|2@1+ (1,0) [0|0] "" X

BO_ 981 ESP_alertMatrix: 8 CH
 SG_ ESP_matrixIndex M: 0|4@1+ (1,0) [0|0] "" X
 SG_ ESP_a001_ecuGenericFault m0: 4|1@1+ (1,0) [0|0] "" X
 SG_ ESP_a002_valvesGenericFault m0: 5|1@1+ (1,0) [0|0] "" X
 SG_ ESP_a003_outletValvesFault m0: 6|1@1+ (1,0) [0|0] "" X
 SG_ ESP_a004_inletValvesFault m0: 7|1@1+ (1,0) [0|0] "" X
 SG_ ESP_a005_HSVValvesFault m0: 8|1@1+ (1,0) [0|0] "" X
 SG_ ESP_a006_USVValvesFault m0: 9|1@1+ (1,0) [0|0] "" X
 SG_ ESP_a007_pumpMotorFault m0: 10|1@1+ (1,0) [0|0] "" X
 SG_ ESP_a008_pumpMotor12VsupplyLow m0: 11|1@1+ (1,0) [0|0] "" X
 SG_ ESP_a009_12VHardUndervoltage m0: 12|1@1+ (1,0) [0|0] "" X
 SG_ ESP_a010_12VUndervoltage m0: 13|1@1+ (1,0) [0|0] "" X
 SG_ ESP_a011_12VSystemUndervoltage m0: 14|1@1+ (1,0) [0|0] "" X
 SG_ ESP_a012_netUndervoltage m0: 15|1@1+ (1,0) [0|0] "" X
 SG_ ESP_a013_valveRelayUndervoltage m0: 16|1@1+ (1,0) [0|0] "" X
 SG_ ESP_a014_WSSSupplyUndervoltage m0: 17|1@1+ (1,0) [0|0] "" X
 SG_ ESP_a015_12VSupplyOvervoltage m0: 18|1@1+ (1,0) [0|0] "" X
 SG_ ESP_a016_12VSystemOvervoltage m0: 19|1@1+ (1,0) [0|0] "" X
 SG_ ESP_a017_netOvervoltage m0: 20|1@1+ (1,0) [0|0] "" X
 SG_ ESP_a018_WSSSignFrontAxle m0: 21|1@1+ (1,0) [0|0] "" X
 SG_ ESP_a019_WSSSignRearAxle m0: 22|1@1+ (1,0) [0|0] "" X
 SG_ ESP_a020_WSSGenericTempFault m0: 23|1@1+ (1,0) [0|0] "" X
 SG_ ESP_a021_WSSGeneralVDiffFault m0: 24|1@1+ (1,0) [0|0] "" X
 SG_ ESP_a022_WSSDirectionFault m0: 25|1@1+ (1,0) [0|0] "" X
 SG_ ESP_a023_WSSSeveralSuspected m0: 26|1@1+ (1,0) [0|0] "" X
 SG_ ESP_a024_WSSReverseCurrent m0: 27|1@1+ (1,0) [0|0] "" X
 SG_ ESP_a025_FrLWSSOpenOrShortToGnd m0: 28|1@1+ (1,0) [0|0] "" X
 SG_ ESP_a026_FrLWSSShortTo12V m0: 29|1@1+ (1,0) [0|0] "" X
 SG_ ESP_a027_FrLWSSLineInterruption m0: 30|1@1+ (1,0) [0|0] "" X
 SG_ ESP_a028_FrLWSSMaxSpeedExceeded m0: 31|1@1+ (1,0) [0|0] "" X
 SG_ ESP_a029_FrLWSSTooManyPulses m0: 32|1@1+ (1,0) [0|0] "" X
 SG_ ESP_a030_FrLWSSLostSignal m0: 33|1@1+ (1,0) [0|0] "" X
 SG_ ESP_a031_FrLWSSNoPulsesDetected m0: 34|1@1+ (1,0) [0|0] "" X
 SG_ ESP_a032_FrLWSSWrongSensorType m0: 35|1@1+ (1,0) [0|0] "" X
 SG_ ESP_a033_FrLWSSSignalNoise m0: 36|1@1+ (1,0) [0|0] "" X
 SG_ ESP_a034_FrLWSSVDiffFault m0: 37|1@1+ (1,0) [0|0] "" X
 SG_ ESP_a035_FrLWSSDirectionFault m0: 38|1@1+ (1,0) [0|0] "" X
 SG_ ESP_a036_FrLWSSLargeAirGap m0: 39|1@1+ (1,0) [0|0] "" X
 SG_ ESP_a037_FrLWSSSupplyShortToGnd m0: 40|1@1+ (1,0) [0|0] "" X
 SG_ ESP_a038_FrLWSSGeneralFault m0: 41|1@1+ (1,0) [0|0] "" X
 SG_ ESP_a039_FrRWSSOpenOrShortToGnd m0: 42|1@1+ (1,0) [0|0] "" X
 SG_ ESP_a040_FrRWSSShortTo12V m0: 43|1@1+ (1,0) [0|0] "" X
 SG_ ESP_a041_FrRWSSLineInterruption m0: 44|1@1+ (1,0) [0|0] "" X
 SG_ ESP_a042_FrRWSSMaxSpeedExceeded m0: 45|1@1+ (1,0) [0|0] "" X
 SG_ ESP_a043_FrRWSSTooManyPulses m0: 46|1@1+ (1,0) [0|0] "" X
 SG_ ESP_a044_FrRWSSLostSignal m0: 47|1@1+ (1,0) [0|0] "" X
 SG_ ESP_a045_FrRWSSNoPulsesDetected m0: 48|1@1+ (1,0) [0|0] "" X
 SG_ ESP_a046_FrRWSSWrongSensorType m0: 49|1@1+ (1,0) [0|0] "" X
 SG_ ESP_a047_FrRWSSSignalNoise m0: 50|1@1+ (1,0) [0|0] "" X
 SG_ ESP_a048_FrRWSSVDiffFault m0: 51|1@1+ (1,0) [0|0] "" X
 SG_ ESP_a049_FrRWSSDirectionFault m0: 52|1@1+ (1,0) [0|0] "" X
 SG_ ESP_a050_FrRWSSLargeAirGap m0: 53|1@1+ (1,0) [0|0] "" X
 SG_ ESP_a051_FrRWSSSupplyShortToGnd m0: 54|1@1+ (1,0) [0|0] "" X
 SG_ ESP_a052_FrRWSSGeneralFault m0: 55|1@1+ (1,0) [0|0] "" X
 SG_ ESP_a053_ReLWSSOpenOrShortToGnd m0: 56|1@1+ (1,0) [0|0] "" X
 SG_ ESP_a054_ReLWSSShortTo12V m0: 57|1@1+ (1,0) [0|0] "" X
 SG_ ESP_a055_ReLWSSLineInterruption m0: 58|1@1+ (1,0) [0|0] "" X
 SG_ ESP_a056_ReLWSSMaxSpeedExceeded m0: 59|1@1+ (1,0) [0|0] "" X
 SG_ ESP_a057_ReLWSSTooManyPulses m0: 60|1@1+ (1,0) [0|0] "" X
 SG_ ESP_a058_ReLWSSLostSignal m0: 61|1@1+ (1,0) [0|0] "" X
 SG_ ESP_a059_ReLWSSNoPulsesDetected m0: 62|1@1+ (1,0) [0|0] "" X
 SG_ ESP_a060_ReLWSSWrongSensorType m0: 63|1@1+ (1,0) [0|0] "" X
 SG_ ESP_a061_ReLWSSSignalNoise m1: 4|1@1+ (1,0) [0|0] "" X
 SG_ ESP_a062_ReLWSSVDiffFault m1: 5|1@1+ (1,0) [0|0] "" X
 SG_ ESP_a063_ReLWSSDirectionFault m1: 6|1@1+ (1,0) [0|0] "" X
 SG_ ESP_a064_ReLWSSLargeAirGap m1: 7|1@1+ (1,0) [0|0] "" X
 SG_ ESP_a065_ReLWSSSupplyShortToGnd m1: 8|1@1+ (1,0) [0|0] "" X
 SG_ ESP_a066_ReLWSSGeneralFault m1: 9|1@1+ (1,0) [0|0] "" X
 SG_ ESP_a067_ReRWSSOpenOrShortToGnd m1: 10|1@1+ (1,0) [0|0] "" X
 SG_ ESP_a068_ReRWSSShortTo12V m1: 11|1@1+ (1,0) [0|0] "" X
 SG_ ESP_a069_ReRWSSLineInterruption m1: 12|1@1+ (1,0) [0|0] "" X
 SG_ ESP_a070_ReRWSSMaxSpeedExceeded m1: 13|1@1+ (1,0) [0|0] "" X
 SG_ ESP_a071_ReRWSSTooManyPulses m1: 14|1@1+ (1,0) [0|0] "" X
 SG_ ESP_a072_ReRWSSLostSignal m1: 15|1@1+ (1,0) [0|0] "" X
 SG_ ESP_a073_ReRWSSNoPulsesDetected m1: 16|1@1+ (1,0) [0|0] "" X
 SG_ ESP_a074_ReRWSSWrongSensorType m1: 17|1@1+ (1,0) [0|0] "" X
 SG_ ESP_a075_ReRWSSSignalNoise m1: 18|1@1+ (1,0) [0|0] "" X
 SG_ ESP_a076_ReRWSSVDiffFault m1: 19|1@1+ (1,0) [0|0] "" X
 SG_ ESP_a077_ReRWSSDirectionFault m1: 20|1@1+ (1,0) [0|0] "" X
 SG_ ESP_a078_ReRWSSLargeAirGap m1: 21|1@1+ (1,0) [0|0] "" X
 SG_ ESP_a079_ReRWSSSupplyShortToGnd m1: 22|1@1+ (1,0) [0|0] "" X
 SG_ ESP_a080_ReRWSSGeneralFault m1: 23|1@1+ (1,0) [0|0] "" X
 SG_ ESP_a081_PressureSensorShort m1: 24|1@1+ (1,0) [0|0] "" X
 SG_ ESP_a082_PMCSensorOffsVEHigh m1: 25|1@1+ (1,0) [0|0] "" X
 SG_ ESP_a083_PMCSensorFault m1: 26|1@1+ (1,0) [0|0] "" X
 SG_ ESP_a084_BrakeFluidReservoirLow m1: 27|1@1+ (1,0) [0|0] "" X
 SG_ ESP_a085_BrakeSwitchStuckHigh m1: 28|1@1+ (1,0) [0|0] "" X
 SG_ ESP_a086_BrakeSwitchImplausible1 m1: 29|1@1+ (1,0) [0|0] "" X
 SG_ ESP_a087_BrakeSwitchImplausible3 m1: 30|1@1+ (1,0) [0|0] "" X
 SG_ ESP_a088_absContinuousControl m1: 31|1@1+ (1,0) [0|0] "" X
 SG_ ESP_a089_absNoPressureIncrease m1: 32|1@1+ (1,0) [0|0] "" X
 SG_ ESP_a090_vdcContinuousControl m1: 33|1@1+ (1,0) [0|0] "" X
 SG_ ESP_a091_CANUndervoltage m1: 34|1@1+ (1,0) [0|0] "" X
 SG_ ESP_a092_CANOvervoltage m1: 35|1@1+ (1,0) [0|0] "" X
 SG_ ESP_a093_partyBusOff m1: 36|1@1+ (1,0) [0|0] "" X
 SG_ ESP_a094_partyBusPassive m1: 37|1@1+ (1,0) [0|0] "" X
 SG_ ESP_a095_CHOff m1: 38|1@1+ (1,0) [0|0] "" X
 SG_ ESP_a096_CHPassive m1: 39|1@1+ (1,0) [0|0] "" X
 SG_ ESP_a097_tcsRefSpeedNotInit m1: 40|1@1+ (1,0) [0|0] "" X
 SG_ ESP_a098_vdcRefSpeedNotInit m1: 41|1@1+ (1,0) [0|0] "" X
 SG_ ESP_a099_brakeTempModelOverheat m1: 42|1@1+ (1,0) [0|0] "" X
 SG_ ESP_a100_brakeTempModelDisabled m1: 43|1@1+ (1,0) [0|0] "" X
 SG_ ESP_a101_ebdFault m1: 44|1@1+ (1,0) [0|0] "" X
 SG_ ESP_a102_absFault m1: 45|1@1+ (1,0) [0|0] "" X
 SG_ ESP_a103_stabilityControlFault m1: 46|1@1+ (1,0) [0|0] "" X
 SG_ ESP_a104_hbcEnabled m1: 47|1@1+ (1,0) [0|0] "" X
 SG_ ESP_a105_ebrFault m1: 48|1@1+ (1,0) [0|0] "" X
 SG_ ESP_a106_vdcActuatorFault m1: 49|1@1+ (1,0) [0|0] "" X
 SG_ ESP_a107_reserved107 m1: 50|1@1+ (1,0) [0|0] "" X
 SG_ ESP_a108_reserved108 m1: 51|1@1+ (1,0) [0|0] "" X
 SG_ ESP_a109_reserved109 m1: 52|1@1+ (1,0) [0|0] "" X
 SG_ ESP_a110_rollerBenchActive m1: 53|1@1+ (1,0) [0|0] "" X
 SG_ ESP_a111_absActive m1: 54|1@1+ (1,0) [0|0] "" X
 SG_ ESP_a112_espActive m1: 55|1@1+ (1,0) [0|0] "" X
 SG_ ESP_a113_btcActive m1: 56|1@1+ (1,0) [0|0] "" X
 SG_ ESP_a114_tvdcActive m1: 57|1@1+ (1,0) [0|0] "" X
 SG_ ESP_a115_ebdActive m1: 58|1@1+ (1,0) [0|0] "" X
 SG_ ESP_a116_tsmActive m1: 59|1@1+ (1,0) [0|0] "" X
 SG_ ESP_a117_hbaActive m1: 60|1@1+ (1,0) [0|0] "" X
 SG_ ESP_a118_hfcActive m1: 61|1@1+ (1,0) [0|0] "" X
 SG_ ESP_a119_hbbActive m1: 62|1@1+ (1,0) [0|0] "" X
 SG_ ESP_a120_rmiActive m1: 63|1@1+ (1,0) [0|0] "" X
 SG_ ESP_a121_regenTcActive m2: 4|1@1+ (1,0) [0|0] "" X
 SG_ ESP_a122_bdwActive m2: 5|1@1+ (1,0) [0|0] "" X
 SG_ ESP_a123_ebrActive m2: 6|1@1+ (1,0) [0|0] "" X
 SG_ ESP_a124_ebrSkidActive m2: 7|1@1+ (1,0) [0|0] "" X
 SG_ ESP_a125_reserved125 m2: 8|1@1+ (1,0) [0|0] "" X
 SG_ ESP_a126_reserved126 m2: 9|1@1+ (1,0) [0|0] "" X
 SG_ ESP_a127_reserved127 m2: 10|1@1+ (1,0) [0|0] "" X
 SG_ ESP_a128_reserved128 m2: 11|1@1+ (1,0) [0|0] "" X
 SG_ ESP_a129_reserved129 m2: 12|1@1+ (1,0) [0|0] "" X
 SG_ ESP_a130_EPAS3PsysStatusTimeout m2: 13|1@1+ (1,0) [0|0] "" X
 SG_ ESP_a131_EPAS3PsysStatusDLC m2: 14|1@1+ (1,0) [0|0] "" X
 SG_ ESP_a132_EPAS3PsysStatusChecksum m2: 15|1@1+ (1,0) [0|0] "" X
 SG_ ESP_a133_EPAS3PsysStatusCounter m2: 16|1@1+ (1,0) [0|0] "" X
 SG_ ESP_a134_steeringAngleInvalid m2: 17|1@1+ (1,0) [0|0] "" X
 SG_ ESP_a135_steeringAngleNoCenter m2: 18|1@1+ (1,0) [0|0] "" X
 SG_ ESP_a136_steeringAngleFrozen m2: 19|1@1+ (1,0) [0|0] "" X
 SG_ ESP_a137_steeringOffsetTooLarge m2: 20|1@1+ (1,0) [0|0] "" X
 SG_ ESP_a138_steeringAngleImplaus m2: 21|1@1+ (1,0) [0|0] "" X
 SG_ ESP_a139_steeringAngleWrongSign m2: 22|1@1+ (1,0) [0|0] "" X
 SG_ ESP_a140_RCMInertial1Timeout m2: 23|1@1+ (1,0) [0|0] "" X
 SG_ ESP_a141_RCMInertial1DLC m2: 24|1@1+ (1,0) [0|0] "" X
 SG_ ESP_a142_RCMInertial1Checksum m2: 25|1@1+ (1,0) [0|0] "" X
 SG_ ESP_a143_RCMInertial1Counter m2: 26|1@1+ (1,0) [0|0] "" X
 SG_ ESP_a144_yawMaxLatency m2: 27|1@1+ (1,0) [0|0] "" X
 SG_ ESP_a145_yawInitFault m2: 28|1@1+ (1,0) [0|0] "" X
 SG_ ESP_a146_yawInvalidValue m2: 29|1@1+ (1,0) [0|0] "" X
 SG_ ESP_a147_yawSensorNotAvailable m2: 30|1@1+ (1,0) [0|0] "" X
 SG_ ESP_a148_yawSignalFault m2: 31|1@1+ (1,0) [0|0] "" X
 SG_ ESP_a149_yawInvalidSign m2: 32|1@1+ (1,0) [0|0] "" X
 SG_ ESP_a150_yawImplausible m2: 33|1@1+ (1,0) [0|0] "" X
 SG_ ESP_a151_RCMInertial2Timeout m2: 34|1@1+ (1,0) [0|0] "" X
 SG_ ESP_a152_RCMInertial2DLC m2: 35|1@1+ (1,0) [0|0] "" X
 SG_ ESP_a153_RCMInertial2Checksum m2: 36|1@1+ (1,0) [0|0] "" X
 SG_ ESP_a154_RCMInertial2Counter m2: 37|1@1+ (1,0) [0|0] "" X
 SG_ ESP_a155_ayMaxLatency m2: 38|1@1+ (1,0) [0|0] "" X
 SG_ ESP_a156_ayInitFault m2: 39|1@1+ (1,0) [0|0] "" X
 SG_ ESP_a157_ayInvalidValue m2: 40|1@1+ (1,0) [0|0] "" X
 SG_ ESP_a158_aySensorNotAvailable m2: 41|1@1+ (1,0) [0|0] "" X
 SG_ ESP_a159_aySignalFault m2: 42|1@1+ (1,0) [0|0] "" X
 SG_ ESP_a160_ayRangeExceeded m2: 43|1@1+ (1,0) [0|0] "" X
 SG_ ESP_a161_ayOffsetExceeded m2: 44|1@1+ (1,0) [0|0] "" X
 SG_ ESP_a162_ayImplausible m2: 45|1@1+ (1,0) [0|0] "" X
 SG_ ESP_a163_axMaxLatency m2: 46|1@1+ (1,0) [0|0] "" X
 SG_ ESP_a164_axInitFault m2: 47|1@1+ (1,0) [0|0] "" X
 SG_ ESP_a165_axInvalidValue m2: 48|1@1+ (1,0) [0|0] "" X
 SG_ ESP_a166_axSensorNotAvailable m2: 49|1@1+ (1,0) [0|0] "" X
 SG_ ESP_a167_axSignalFault m2: 50|1@1+ (1,0) [0|0] "" X
 SG_ ESP_a168_axRangeExceeded m2: 51|1@1+ (1,0) [0|0] "" X
 SG_ ESP_a169_axOffsetExceeded m2: 52|1@1+ (1,0) [0|0] "" X
 SG_ ESP_a170_axSignalFrozen m2: 53|1@1+ (1,0) [0|0] "" X
 SG_ ESP_a171_axImplausible m2: 54|1@1+ (1,0) [0|0] "" X
 SG_ ESP_a172_IBSTparty1Timeout m2: 55|1@1+ (1,0) [0|0] "" X
 SG_ ESP_a173_IBSTparty1DLC m2: 56|1@1+ (1,0) [0|0] "" X
 SG_ ESP_a174_IBSTparty1Checksum m2: 57|1@1+ (1,0) [0|0] "" X
 SG_ ESP_a175_IBSTparty1Counter m2: 58|1@1+ (1,0) [0|0] "" X
 SG_ ESP_a176_IBSTEBRNotAvailable m2: 59|1@1+ (1,0) [0|0] "" X
 SG_ ESP_a177_IBSTOutputRodDrvInvalid m2: 60|1@1+ (1,0) [0|0] "" X
 SG_ ESP_a178_IBSTOutputRodActInvalid m2: 61|1@1+ (1,0) [0|0] "" X
 SG_ ESP_a179_IBSTparty2Timeout m2: 62|1@1+ (1,0) [0|0] "" X
 SG_ ESP_a180_IBSTparty2Checksum m2: 63|1@1+ (1,0) [0|0] "" X
 SG_ ESP_a181_IBSTparty2DLC m3: 4|1@1+ (1,0) [0|0] "" X
 SG_ ESP_a182_IBSTparty2Counter m3: 5|1@1+ (1,0) [0|0] "" X
 SG_ ESP_a183_IBSTStatusOff m3: 6|1@1+ (1,0) [0|0] "" X
 SG_ ESP_a184_IBSTpRunoutInvalid m3: 7|1@1+ (1,0) [0|0] "" X
 SG_ ESP_a185_IBSTFeedforwardBackup m3: 8|1@1+ (1,0) [0|0] "" X
 SG_ ESP_a186_IBSTBrakeAppliedInvalid m3: 9|1@1+ (1,0) [0|0] "" X
 SG_ ESP_a187_DIbtcRequestTimeout m3: 10|1@1+ (1,0) [0|0] "" X
 SG_ ESP_a188_DIbtcRequestDLC m3: 11|1@1+ (1,0) [0|0] "" X
 SG_ ESP_a189_DIbtcRequestChecksum m3: 12|1@1+ (1,0) [0|0] "" X
 SG_ ESP_a190_DIbtcRequestCounter m3: 13|1@1+ (1,0) [0|0] "" X
 SG_ ESP_a191_DIchassiControlTimeout m3: 14|1@1+ (1,0) [0|0] "" X
 SG_ ESP_a192_DIchassiControlDLC m3: 15|1@1+ (1,0) [0|0] "" X
 SG_ ESP_a193_DIchassiControlChecksum m3: 16|1@1+ (1,0) [0|0] "" X
 SG_ ESP_a194_DIchassiControlCounter m3: 17|1@1+ (1,0) [0|0] "" X
 SG_ ESP_a195_ptcStateInvalid m3: 18|1@1+ (1,0) [0|0] "" X
 SG_ ESP_a196_DIsystemStatusTimeout m3: 19|1@1+ (1,0) [0|0] "" X
 SG_ ESP_a197_DIsystemStatusDLC m3: 20|1@1+ (1,0) [0|0] "" X
 SG_ ESP_a198_DIsystemStatusChecksum m3: 21|1@1+ (1,0) [0|0] "" X
 SG_ ESP_a199_DIsystemStatusCounter m3: 22|1@1+ (1,0) [0|0] "" X
 SG_ ESP_a200_reverseGearStuckHigh m3: 23|1@1+ (1,0) [0|0] "" X
 SG_ ESP_a201_reverseGearStuckLow m3: 24|1@1+ (1,0) [0|0] "" X
 SG_ ESP_a202_accelPedalInvalid m3: 25|1@1+ (1,0) [0|0] "" X
 SG_ ESP_a203_DItorqueTimeout m3: 26|1@1+ (1,0) [0|0] "" X
 SG_ ESP_a204_DItorqueDLC m3: 27|1@1+ (1,0) [0|0] "" X
 SG_ ESP_a205_DItorqueChecksum m3: 28|1@1+ (1,0) [0|0] "" X
 SG_ ESP_a206_DItorqueCounter m3: 29|1@1+ (1,0) [0|0] "" X
 SG_ ESP_a207_DITorqueCommandInvalid m3: 30|1@1+ (1,0) [0|0] "" X
 SG_ ESP_a208_DIRPMInvalid m3: 31|1@1+ (1,0) [0|0] "" X
 SG_ ESP_a209_DITorqueActualInvalid m3: 32|1@1+ (1,0) [0|0] "" X
 SG_ ESP_a210_DIStorqueTimeout m3: 33|1@1+ (1,0) [0|0] "" X
 SG_ ESP_a211_DIStorqueDLC m3: 34|1@1+ (1,0) [0|0] "" X
 SG_ ESP_a212_DIStorqueChecksum m3: 35|1@1+ (1,0) [0|0] "" X
 SG_ ESP_a213_DIStorqueCounter m3: 36|1@1+ (1,0) [0|0] "" X
 SG_ ESP_a214_DISTorqueCommandInvalid m3: 37|1@1+ (1,0) [0|0] "" X
 SG_ ESP_a215_DISRPMInvalid m3: 38|1@1+ (1,0) [0|0] "" X
 SG_ ESP_a216_DISTorqueActualInvalid m3: 39|1@1+ (1,0) [0|0] "" X
 SG_ ESP_a217_DIvdcLeftTimeout m3: 40|1@1+ (1,0) [0|0] "" X
 SG_ ESP_a218_DIvdcLeftDLC m3: 41|1@1+ (1,0) [0|0] "" X
 SG_ ESP_a219_DIvdcLeftChecksum m3: 42|1@1+ (1,0) [0|0] "" X
 SG_ ESP_a220_DIvdcLeftCounter m3: 43|1@1+ (1,0) [0|0] "" X
 SG_ ESP_a221_DIvdcRightTimeout m3: 44|1@1+ (1,0) [0|0] "" X
 SG_ ESP_a222_DIvdcRightDLC m3: 45|1@1+ (1,0) [0|0] "" X
 SG_ ESP_a223_DIvdcRightChecksum m3: 46|1@1+ (1,0) [0|0] "" X
 SG_ ESP_a224_DIvdcRightCounter m3: 47|1@1+ (1,0) [0|0] "" X
 SG_ ESP_a225_configMismatch m3: 48|1@1+ (1,0) [0|0] "" X
 SG_ ESP_a226_bdwRequestInvalid m3: 49|1@1+ (1,0) [0|0] "" X
 SG_ ESP_a227_bdwRequestActiveInvalid m3: 50|1@1+ (1,0) [0|0] "" X
 SG_ ESP_a228_GTWvinTimeout m3: 51|1@1+ (1,0) [0|0] "" X
 SG_ ESP_a229_GTWvinDLC m3: 52|1@1+ (1,0) [0|0] "" X
 SG_ ESP_a230_vinNotLearned m3: 53|1@1+ (1,0) [0|0] "" X
 SG_ ESP_a231_storedVINMismatch m3: 54|1@1+ (1,0) [0|0] "" X
 SG_ ESP_a232_PMstate2Timeout m3: 55|1@1+ (1,0) [0|0] "" X
 SG_ ESP_a233_PMstate2Checksum m3: 56|1@1+ (1,0) [0|0] "" X
 SG_ ESP_a234_PMstate2DLC m3: 57|1@1+ (1,0) [0|0] "" X
 SG_ ESP_a235_PMstate2Counter m3: 58|1@1+ (1,0) [0|0] "" X
 SG_ ESP_a236_ebrCommandStateInvalid m3: 59|1@1+ (1,0) [0|0] "" X
 SG_ ESP_a237_vdcCommandStateInvalid m3: 60|1@1+ (1,0) [0|0] "" X
 SG_ ESP_a238_UIodoTimeout m3: 61|1@1+ (1,0) [0|0] "" X
 SG_ ESP_a239_UIodoDLC m3: 62|1@1+ (1,0) [0|0] "" X
 SG_ ESP_a240_LVPowerStateTimeout m3: 63|1@1+ (1,0) [0|0] "" X
 SG_ ESP_a241_LVPowerStateChecksum m4: 4|1@1+ (1,0) [0|0] "" X
 SG_ ESP_a242_LVPowerStateDLC m4: 5|1@1+ (1,0) [0|0] "" X
 SG_ ESP_a243_LVPowerStateCounter m4: 6|1@1+ (1,0) [0|0] "" X
 SG_ ESP_a244_LVOffStateInvalid m4: 7|1@1+ (1,0) [0|0] "" X
 SG_ ESP_a245_LVGoingDownStateInvalid m4: 8|1@1+ (1,0) [0|0] "" X
 SG_ ESP_a246_VCFRONTsensorTimeout m4: 9|1@1+ (1,0) [0|0] "" X
 SG_ ESP_a247_VCFRONTsensorDLC m4: 10|1@1+ (1,0) [0|0] "" X
 SG_ ESP_a248_vdcBrkeTrqTarFrLInvalid m4: 11|1@1+ (1,0) [0|0] "" X
 SG_ ESP_a249_vdcBrkeTrqTarFrRInvalid m4: 12|1@1+ (1,0) [0|0] "" X
 SG_ ESP_a250_vdcBrkeTrqTarReLInvalid m4: 13|1@1+ (1,0) [0|0] "" X
 SG_ ESP_a251_vdcBrkeTrqTarReRInvalid m4: 14|1@1+ (1,0) [0|0] "" X
 SG_ ESP_a252_vdcWhlSlipLimFrLInvalid m4: 15|1@1+ (1,0) [0|0] "" X
 SG_ ESP_a253_vdcWhlSlipLimFrRInvalid m4: 16|1@1+ (1,0) [0|0] "" X
 SG_ ESP_a254_vdcWhlSlipLimReLInvalid m4: 17|1@1+ (1,0) [0|0] "" X
 SG_ ESP_a255_vdcWhlSlipLimReRInvalid m4: 18|1@1+ (1,0) [0|0] "" X
 SG_ ESP_a256_epbmStatusTimeout m4: 19|1@1+ (1,0) [0|0] "" X
 SG_ ESP_a257_epbmStatusChecksum m4: 20|1@1+ (1,0) [0|0] "" X
 SG_ ESP_a258_epbmStatusDLC m4: 21|1@1+ (1,0) [0|0] "" X
 SG_ ESP_a259_epbmStatusCounter m4: 22|1@1+ (1,0) [0|0] "" X
 SG_ ESP_a260_epblStatusTimeout m4: 23|1@1+ (1,0) [0|0] "" X
 SG_ ESP_a261_epblStatusChecksum m4: 24|1@1+ (1,0) [0|0] "" X
 SG_ ESP_a262_epblStatusDLC m4: 25|1@1+ (1,0) [0|0] "" X
 SG_ ESP_a263_epblStatusCounter m4: 26|1@1+ (1,0) [0|0] "" X

BO_ 984 ID3D8Elevation: 2 VehicleBus
 SG_ Elevation3D8 : 0|14@1- (1,0) [-8192|8191] "M"  Receiver

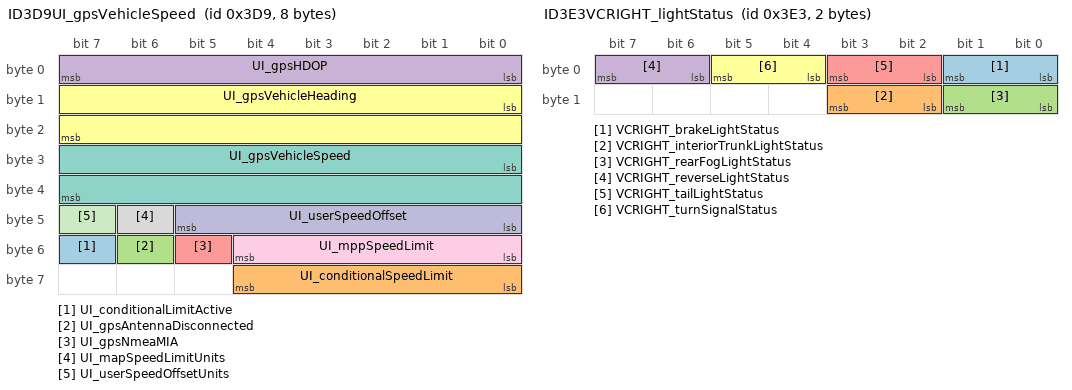
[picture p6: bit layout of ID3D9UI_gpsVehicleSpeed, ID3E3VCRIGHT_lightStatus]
BO_ 985 ID3D9UI_gpsVehicleSpeed: 8 ChassisBus
 SG_ UI_conditionalLimitActive : 55|1@1+ (1,0) [0|1] ""  Receiver
 SG_ UI_conditionalSpeedLimit : 56|5@1+ (5,0) [0|155] "kph/mph"  Receiver
 SG_ UI_gpsAntennaDisconnected : 54|1@1+ (1,0) [0|1] ""  Receiver
 SG_ UI_gpsHDOP : 0|8@1+ (0.1,0) [0|25.5] ""  Receiver
 SG_ UI_gpsNmeaMIA : 53|1@1+ (1,0) [0|1] ""  Receiver
 SG_ UI_gpsVehicleHeading : 8|16@1+ (0.0078125,0) [0|511.992] "deg"  Receiver
 SG_ UI_gpsVehicleSpeed : 24|16@1+ (0.00390625,0) [0|250.996] "kph"  Receiver
 SG_ UI_mapSpeedLimitUnits : 46|1@1+ (1,0) [0|1] ""  Receiver
 SG_ UI_mppSpeedLimit : 48|5@1+ (5,0) [0|155] "kph/mph"  Receiver
 SG_ UI_userSpeedOffset : 40|6@1+ (1,-30) [-30|33] "kph/mph"  Receiver
 SG_ UI_userSpeedOffsetUnits : 47|1@1+ (1,0) [0|1] ""  Receiver

BO_ 986 DAS_telemetryEvent: 8 VEH
 SG_ DAS_TE_multiplexer M: 0|5@1+ (1,0) [0|0] "" X
 SG_ DAS_TE_counter m0: 5|3@1+ (1,0) [0|0] "" X
 SG_ DAS_TE_eventID m0: 8|16@1+ (1,0) [0|0] "" X
 SG_ DAS_TE_eventType m0: 24|6@1+ (1,0) [0|0] "" X
 SG_ DAS_TE_lcAbortReason m0: 32|5@1+ (1,0) [0|0] "" X
 SG_ DAS_TE_llCounter m1: 5|3@1+ (1,0) [0|0] "" X
 SG_ DAS_TE_llC0 m1: 8|10@1- (0.02,0) [0|0] "m" X
 SG_ DAS_TE_llC1 m1: 18|9@1- (0.00195313,0) [0|0] "rad" X
 SG_ DAS_TE_llC2 m1: 27|14@1- (4e-06,0) [0|0] "1/m" X
 SG_ DAS_TE_llC3 m1: 41|14@1- (1.6e-08,0) [0|0] "1/m2" X
 SG_ DAS_TE_llQlty m1: 55|1@1+ (1,0) [0|0] "" X
 SG_ DAS_TE_llRange m1: 56|7@1+ (1,0) [0|0] "m" X
 SG_ DAS_TE_llFuse m1: 63|1@1+ (1,0) [0|0] "" X
 SG_ DAS_TE_rlCounter m2: 5|3@1+ (1,0) [0|0] "" X
 SG_ DAS_TE_rlC0 m2: 8|10@1- (0.02,0) [0|0] "m" X
 SG_ DAS_TE_rlC1 m2: 18|9@1- (0.00195313,0) [0|0] "rad" X
 SG_ DAS_TE_rlC2 m2: 27|14@1- (4e-06,0) [0|0] "1/m" X
 SG_ DAS_TE_rlC3 m2: 41|14@1- (1.6e-08,0) [0|0] "1/m2" X
 SG_ DAS_TE_rlQlty m2: 55|1@1+ (1,0) [0|0] "" X
 SG_ DAS_TE_rlRange m2: 56|7@1+ (1,0) [0|0] "m" X
 SG_ DAS_TE_rlFuse m2: 63|1@1+ (1,0) [0|0] "" X
 SG_ DAS_TE_hppCounter m3: 5|3@1+ (1,0) [0|0] "" X
 SG_ DAS_TE_hppC0 m3: 8|10@1- (0.02,0) [0|0] "m" X
 SG_ DAS_TE_hppC1 m3: 18|9@1- (0.00195313,0) [0|0] "rad" X
 SG_ DAS_TE_hppC2 m3: 27|14@1- (4e-06,0) [0|0] "1/m" X
 SG_ DAS_TE_hppC3 m3: 41|14@1- (1.6e-08,0) [0|0] "1/m2" X
 SG_ DAS_TE_hppQlty m3: 55|1@1+ (1,0) [0|0] "" X
 SG_ DAS_TE_hppRange m3: 56|7@1+ (1,0) [0|0] "m" X
 SG_ DAS_TE_hppFuse m3: 63|1@1+ (1,0) [0|0] "" X
 SG_ DAS_TE_navCounter m4: 5|3@1+ (1,0) [0|0] "" X
 SG_ DAS_TE_navC0 m4: 8|10@1- (0.02,0) [0|0] "m" X
 SG_ DAS_TE_navC1 m4: 18|9@1- (0.00195313,0) [0|0] "rad" X
 SG_ DAS_TE_navC2 m4: 27|14@1- (4e-06,0) [0|0] "1/m" X
 SG_ DAS_TE_navC3 m4: 41|14@1- (1.6e-08,0) [0|0] "1/m2" X
 SG_ DAS_TE_navQlty m4: 55|1@1+ (1,0) [0|0] "" X
 SG_ DAS_TE_navRange m4: 56|7@1+ (1,0) [0|0] "m" X
 SG_ DAS_TE_navFuse m4: 63|1@1+ (1,0) [0|0] "" X
 SG_ DAS_TE_vlCounter m5: 5|3@1+ (1,0) [0|0] "" X
 SG_ DAS_TE_vlC0 m5: 8|10@1- (0.02,0) [0|0] "m" X
 SG_ DAS_TE_vlC1 m5: 18|9@1- (0.00195313,0) [0|0] "rad" X
 SG_ DAS_TE_vlC2 m5: 27|14@1- (4e-06,0) [0|0] "1/m" X
 SG_ DAS_TE_vlC3 m5: 41|14@1- (1.6e-08,0) [0|0] "1/m2" X
 SG_ DAS_TE_vlQlty m5: 55|1@1+ (1,0) [0|0] "" X
 SG_ DAS_TE_vlRange m5: 56|7@1+ (1,0) [0|0] "m" X
 SG_ DAS_TE_vlFuse m5: 63|1@1+ (1,0) [0|0] "" X
 SG_ DAS_TE_accCounter m6: 5|3@1+ (1,0) [0|0] "" X
 SG_ DAS_TE_accTargetDx m6: 8|6@1+ (2,0) [0|0] "m" X
 SG_ DAS_TE_accTargetDy m6: 14|6@1+ (0.2,-6.4) [0|0] "m" X
 SG_ DAS_TE_accTargetRelVel m6: 20|7@1- (0.25,-15.75) [0|0] "m/s" X
 SG_ DAS_TE_accTargetRelA m6: 27|5@1- (0.5,-7.5) [0|0] "m/s^2" X
 SG_ DAS_TE_accMinAccel m6: 32|5@1- (0.5,-7.5) [0|0] "m/s^2" X
 SG_ DAS_TE_accMinJ m6: 37|5@1- (0.5,-7.5) [0|0] "m/s^3" X
 SG_ DAS_TE_fcmCounter m7: 5|3@1+ (1,0) [0|0] "" X
 SG_ DAS_TE_fcmTargetDx m7: 8|8@1+ (0.25,0) [0|0] "m" X
 SG_ DAS_TE_fcmTargetDy m7: 16|5@1+ (0.2,-3.2) [0|0] "m" X
 SG_ DAS_TE_fcmTargetVRel m7: 21|7@1+ (0.25,-31.75) [0|0] "m/s" X
 SG_ DAS_TE_fcmTargetAccel m7: 28|5@1+ (0.5,-15.5) [0|0] "m/s^2" X
 SG_ DAS_TE_fcmTargetProb m7: 33|5@1+ (5,0) [0|0] "%" X
 SG_ DAS_TE_fcmDecelReqInstant m7: 38|7@1- (0.1,-6.3) [0|0] "m/s^2" X
 SG_ DAS_TE_fcmDecelReqAeb m7: 45|7@1- (0.1,-6.3) [0|0] "m/s^2" X
 SG_ DAS_TE_meAebFlag m7: 52|1@1+ (1,0) [0|0] "" X
 SG_ DAS_TE_ipsoCounter m8: 5|3@1+ (1,0) [0|0] "" X
 SG_ DAS_TE_ipsoValid m8: 8|1@1+ (1,0) [0|0] "" X
 SG_ DAS_TE_ipsoConfidence m8: 9|7@1+ (1,0) [0|0] "" X
 SG_ DAS_TE_ipsoDx m8: 16|6@1+ (2,0) [0|0] "m" X
 SG_ DAS_TE_ipsoDy m8: 22|6@1+ (0.1,-3.2) [0|0] "m" X
 SG_ DAS_TE_vlDyAtIpsoDx m8: 28|6@1+ (0.1,-3.2) [0|0] "m" X
 SG_ DAS_TE_swaProjection m8: 34|6@1+ (0.1,-3.2) [0|0] "m" X
 SG_ DAS_TE_ipsoIsTarget1 m8: 40|1@1+ (1,0) [0|0] "" X
 SG_ DAS_TE_ipsoIsTarget5 m8: 41|1@1+ (1,0) [0|0] "" X
 SG_ DAS_TE_restrictedAccess m8: 42|1@1+ (1,0) [0|0] "" X
 SG_ DAS_TE_csaOfframpValid m8: 43|1@1+ (1,0) [0|0] "" X
 SG_ DAS_TE_accControlType m8: 44|4@1+ (1,0) [0|0] "" X
 SG_ DAS_TE_brakeCapacityWarning m8: 48|1@1+ (1,0) [0|0] "" X
 SG_ DAS_TE_emergencyBrake m8: 49|1@1+ (1,0) [0|0] "" X
 SG_ DAS_TE_extendedAccLimits m8: 50|1@1+ (1,0) [0|0] "" X
 SG_ DAS_TE_crashFront m8: 51|1@1+ (1,0) [0|0] "" X
 SG_ DAS_TE_crashLeft m8: 52|1@1+ (1,0) [0|0] "" X
 SG_ DAS_TE_crashRear m8: 53|1@1+ (1,0) [0|0] "" X
 SG_ DAS_TE_crashRight m8: 54|1@1+ (1,0) [0|0] "" X
 SG_ DAS_TE_crashRollover m8: 55|1@1+ (1,0) [0|0] "" X
 SG_ DAS_TE_crashPedPro m8: 56|1@1+ (1,0) [0|0] "" X
 SG_ DAS_TE_meIpsoValid m8: 57|1@1+ (1,0) [0|0] "" X
 SG_ DAS_TE_robCounter m9: 5|3@1+ (1,0) [0|0] "" X
 SG_ DAS_TE_robExceptionStart m9: 16|8@1+ (1,-95) [0|0] "m" X
 SG_ DAS_TE_robExceptionEnd m9: 24|8@1+ (1,0) [0|0] "m" X
 SG_ DAS_TE_robDistanceEllipse m9: 32|8@1+ (0.5,0) [0|0] "m" X
 SG_ DAS_TE_robEllipseOverlap m9: 40|8@1+ (0.1,-12.5) [0|0] "m" X
 SG_ DAS_TE_robEllipseAge m9: 48|3@1+ (1,0) [0|0] "" X
 SG_ DAS_TE_robInfrastructure m9: 51|1@1+ (1,0) [0|0] "" X
 SG_ DAS_TE_robTrustRadarMap m9: 52|1@1+ (1,0) [0|0] "" X
 SG_ DAS_TE_robActiveBraking m9: 53|1@1+ (1,0) [0|0] "" X

BO_ 990 FC_alertMatrix6: 8 VEH
 SG_ FC_a321_FCAlertPlaceholder: 0|1@1+ (1,0) [0|0] "" X

BO_ 994 ID3E2VCLEFT_lightStatus: 7 VehicleBus
 SG_ VCLEFT_FLMapLightStatus : 6|2@1+ (1,0) [0|3] ""  Receiver
 SG_ VCLEFT_FLMapLightSwitchPressed : 14|1@1+ (1,0) [0|1] ""  Receiver
 SG_ VCLEFT_FRMapLightStatus : 8|2@1+ (1,0) [0|3] ""  Receiver
 SG_ VCLEFT_FRMapLightSwitchPressed : 15|1@1+ (1,0) [0|1] ""  Receiver
 SG_ VCLEFT_RLMapLightStatus : 10|2@1+ (1,0) [0|3] ""  Receiver
 SG_ VCLEFT_RLMapLightSwitchPressed : 16|1@1+ (1,0) [0|1] ""  Receiver
 SG_ VCLEFT_RRMapLightStatus : 12|2@1+ (1,0) [0|3] ""  Receiver
 SG_ VCLEFT_RRMapLightSwitchPressed : 17|1@1+ (1,0) [0|1] ""  Receiver
 SG_ VCLEFT_brakeLightStatus : 0|2@1+ (1,0) [0|3] ""  Receiver
 SG_ VCLEFT_brakeTrailerLightStatus : 22|2@1+ (1,0) [0|3] ""  Receiver
 SG_ VCLEFT_dynamicBrakeLightStatus : 44|2@1+ (1,0) [0|2] ""  Receiver
 SG_ VCLEFT_fogTrailerLightStatus : 26|2@1+ (1,0) [0|3] ""  Receiver
 SG_ VCLEFT_frontRideHeight : 28|8@1- (1,0) [-127|127] "mm"  Receiver
 SG_ VCLEFT_leftTurnTrailerLightStatu : 18|2@1+ (1,0) [0|3] ""  Receiver
 SG_ VCLEFT_rearRideHeight : 36|8@1- (1,0) [-127|127] "mm"  Receiver
 SG_ VCLEFT_reverseTrailerLightStatus : 49|2@1+ (1,0) [0|3] ""  Receiver
 SG_ VCLEFT_rideHeightSensorFault : 48|1@1+ (1,0) [0|1] ""  Receiver
 SG_ VCLEFT_rightTrnTrailerLightStatu : 20|2@1+ (1,0) [0|3] ""  Receiver
 SG_ VCLEFT_tailLightOutageStatus : 51|1@1+ (1,0) [0|1] ""  Receiver
 SG_ VCLEFT_tailLightStatus : 2|2@1+ (1,0) [0|3] ""  Receiver
 SG_ VCLEFT_tailTrailerLightStatus : 24|2@1+ (1,0) [0|3] ""  Receiver
 SG_ VCLEFT_trailerDetected : 46|2@1+ (1,0) [0|3] ""  Receiver
 SG_ VCLEFT_turnSignalStatus : 4|2@1+ (1,0) [0|3] ""  Receiver

BO_ 995 ID3E3VCRIGHT_lightStatus: 2 VehicleBus
 SG_ VCRIGHT_brakeLightStatus : 0|2@1+ (1,0) [0|3] ""  Receiver
 SG_ VCRIGHT_interiorTrunkLightStatus : 10|2@1+ (1,0) [0|3] ""  Receiver
 SG_ VCRIGHT_rearFogLightStatus : 8|2@1+ (1,0) [0|3] ""  Receiver
 SG_ VCRIGHT_reverseLightStatus : 6|2@1+ (1,0) [0|3] ""  Receiver
 SG_ VCRIGHT_tailLightStatus : 2|2@1+ (1,0) [0|3] ""  Receiver
 SG_ VCRIGHT_turnSignalStatus : 4|2@1+ (1,0) [0|3] ""  Receiver

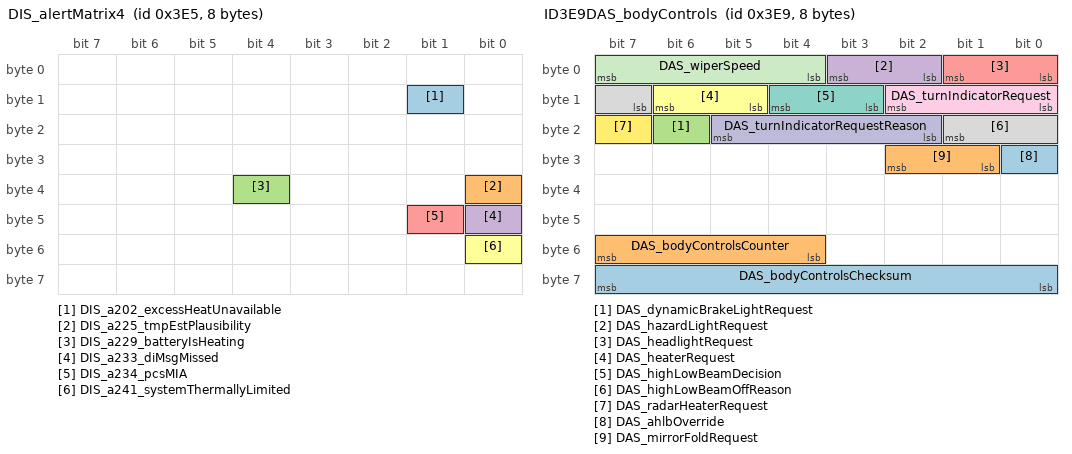
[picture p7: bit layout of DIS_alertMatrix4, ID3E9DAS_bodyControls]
BO_ 997 DIS_alertMatrix4: 8 VEH
 SG_ DIS_a202_excessHeatUnavailable: 9|1@1+ (1,0) [0|0] "" X
 SG_ DIS_a225_tmpEstPlausibility: 32|1@1+ (1,0) [0|0] "" X
 SG_ DIS_a229_batteryIsHeating: 36|1@1+ (1,0) [0|0] "" X
 SG_ DIS_a233_diMsgMissed: 40|1@1+ (1,0) [0|0] "" X
 SG_ DIS_a234_pcsMIA: 41|1@1+ (1,0) [0|0] "" X
 SG_ DIS_a241_systemThermallyLimited: 48|1@1+ (1,0) [0|0] "" X

BO_ 1000 EPBR_alertMatrix: 8 VEH
 SG_ EPBR_matrixIndex M: 0|4@1+ (1,0) [0|0] "" X
 SG_ EPBR_a001_WatchdogReset m0: 4|1@1+ (1,0) [0|0] "" X
 SG_ EPBR_a002_PowerLossReset m0: 5|1@1+ (1,0) [0|0] "" X
 SG_ EPBR_a003_SWAssertion m0: 6|1@1+ (1,0) [0|0] "" X
 SG_ EPBR_a010_ExtSupplyVoltError m0: 13|1@1+ (1,0) [0|0] "" X
 SG_ EPBR_a012_CPUReset m0: 15|1@1+ (1,0) [0|0] "" X
 SG_ EPBR_a013_AlertManagerFault m0: 16|1@1+ (1,0) [0|0] "" X
 SG_ EPBR_a015_NVMMAlert m0: 18|1@1+ (1,0) [0|0] "" X
 SG_ EPBR_a021_TaskSchedulerError m0: 24|1@1+ (1,0) [0|0] "" X
 SG_ EPBR_a022_TaskInitError m0: 25|1@1+ (1,0) [0|0] "" X
 SG_ EPBR_a031_UDSActive m0: 34|1@1+ (1,0) [0|0] "" X
 SG_ EPBR_a041_HighCPULoad m0: 44|1@1+ (1,0) [0|0] "" X
 SG_ EPBR_a042_HighStackUsage m0: 45|1@1+ (1,0) [0|0] "" X
 SG_ EPBR_a043_Task1msError m0: 46|1@1+ (1,0) [0|0] "" X
 SG_ EPBR_a044_Task10msError m0: 47|1@1+ (1,0) [0|0] "" X
 SG_ EPBR_a045_Task100msError m0: 48|1@1+ (1,0) [0|0] "" X
 SG_ EPBR_a046_Task1000msError m0: 49|1@1+ (1,0) [0|0] "" X
 SG_ EPBR_a059_inputResistanceHigh m0: 62|1@1+ (1,0) [0|0] "" X
 SG_ EPBR_a060_engineeringBuild m0: 63|1@1+ (1,0) [0|0] "" X
 SG_ EPBR_a061_XCPConnected m1: 4|1@1+ (1,0) [0|0] "" X
 SG_ EPBR_a062_XCPWasConnected m1: 5|1@1+ (1,0) [0|0] "" X
 SG_ EPBR_a063_SwitchFault m1: 6|1@1+ (1,0) [0|0] "" X
 SG_ EPBR_a064_busSleepReqTimeout m1: 7|1@1+ (1,0) [0|0] "" X
 SG_ EPBR_a097_CMP_MIA m1: 40|1@1+ (1,0) [0|0] "" X
 SG_ EPBR_a098_DI_THERMAL_MIA m1: 41|1@1+ (1,0) [0|0] "" X
 SG_ EPBR_a099_PARK_MIA m1: 42|1@1+ (1,0) [0|0] "" X
 SG_ EPBR_a100_CANbus_MIA m1: 43|1@1+ (1,0) [0|0] "" X
 SG_ EPBR_a101_PM_MIA m1: 44|1@1+ (1,0) [0|0] "" X
 SG_ EPBR_a102_PTC_MIA m1: 45|1@1+ (1,0) [0|0] "" X
 SG_ EPBR_a103_CP_MIA m1: 46|1@1+ (1,0) [0|0] "" X
 SG_ EPBR_a104_DAS_MIA m1: 47|1@1+ (1,0) [0|0] "" X
 SG_ EPBR_a105_TAS_MIA m1: 48|1@1+ (1,0) [0|0] "" X
 SG_ EPBR_a106_PCS_MIA m1: 49|1@1+ (1,0) [0|0] "" X
 SG_ EPBR_a107_BMS_MIA m1: 50|1@1+ (1,0) [0|0] "" X
 SG_ EPBR_a108_DIS_MIA m1: 51|1@1+ (1,0) [0|0] "" X
 SG_ EPBR_a109_RCM_MIA m1: 52|1@1+ (1,0) [0|0] "" X
 SG_ EPBR_a110_GTW_MIA m1: 53|1@1+ (1,0) [0|0] "" X
 SG_ EPBR_a111_EPBR_MIA m1: 54|1@1+ (1,0) [0|0] "" X
 SG_ EPBR_a112_EPBL_MIA m1: 55|1@1+ (1,0) [0|0] "" X
 SG_ EPBR_a113_UI_MIA m1: 56|1@1+ (1,0) [0|0] "" X
 SG_ EPBR_a114_ESP_MIA m1: 57|1@1+ (1,0) [0|0] "" X
 SG_ EPBR_a115_VCSEC_MIA m1: 58|1@1+ (1,0) [0|0] "" X
 SG_ EPBR_a116_VCRIGHT_MIA m1: 59|1@1+ (1,0) [0|0] "" X
 SG_ EPBR_a117_VCLEFT_MIA m1: 60|1@1+ (1,0) [0|0] "" X
 SG_ EPBR_a118_VCFRONT_MIA m1: 61|1@1+ (1,0) [0|0] "" X
 SG_ EPBR_a119_SCCM_MIA m1: 62|1@1+ (1,0) [0|0] "" X
 SG_ EPBR_a120_DI_DRIVE_MIA m1: 63|1@1+ (1,0) [0|0] "" X
 SG_ EPBR_a121_nDriveFault m2: 4|1@1+ (1,0) [0|0] "" X
 SG_ EPBR_a122_Oc m2: 5|1@1+ (1,0) [0|0] "" X
 SG_ EPBR_a123_Uc m2: 6|1@1+ (1,0) [0|0] "" X
 SG_ EPBR_a124_calOutOfBounds m2: 7|1@1+ (1,0) [0|0] "" X
 SG_ EPBR_a125_IdleVMismatch m2: 8|1@1+ (1,0) [0|0] "" X
 SG_ EPBR_a126_MotorNVoltLow m2: 9|1@1+ (1,0) [0|0] "" X
 SG_ EPBR_a127_MotorNVoltHigh m2: 10|1@1+ (1,0) [0|0] "" X
 SG_ EPBR_a128_MotorPVoltHigh m2: 11|1@1+ (1,0) [0|0] "" X
 SG_ EPBR_a134_NvOv m2: 17|1@1+ (1,0) [0|0] "" X
 SG_ EPBR_a135_NvUv m2: 18|1@1+ (1,0) [0|0] "" X
 SG_ EPBR_a136_PvOv m2: 19|1@1+ (1,0) [0|0] "" X
 SG_ EPBR_a137_PvUv m2: 20|1@1+ (1,0) [0|0] "" X
 SG_ EPBR_a138_NVMWriteTime m2: 21|1@1+ (1,0) [0|0] "" X
 SG_ EPBR_a141_invalidState m2: 24|1@1+ (1,0) [0|0] "" X
 SG_ EPBR_a170_12vOv m2: 53|1@1+ (1,0) [0|0] "" X
 SG_ EPBR_a171_12vUv m2: 54|1@1+ (1,0) [0|0] "" X
 SG_ EPBR_a172_SPI_MIA m2: 55|1@1+ (1,0) [0|0] "" X
 SG_ EPBR_a173_hiCurrentMissing m2: 56|1@1+ (1,0) [0|0] "" X
 SG_ EPBR_a174_csmReleaseFailed m2: 57|1@1+ (1,0) [0|0] "" X
 SG_ EPBR_a175_csmReleaseRetry m2: 58|1@1+ (1,0) [0|0] "" X
 SG_ EPBR_a176_csmApplyFailed m2: 59|1@1+ (1,0) [0|0] "" X
 SG_ EPBR_a177_csmApplyRetry m2: 60|1@1+ (1,0) [0|0] "" X
 SG_ EPBR_a178_caliperStateUnknown m2: 61|1@1+ (1,0) [0|0] "" X
 SG_ EPBR_a179_epbProblem m2: 62|1@1+ (1,0) [0|0] "" X
 SG_ EPBR_a180_dynamicActive m2: 63|1@1+ (1,0) [0|0] "" X
 SG_ EPBR_a181_TooSteepGradeToPark m3: 4|1@1+ (1,0) [0|0] "" X
 SG_ EPBR_a182_OneEPBAppliedUnsecEnv m3: 5|1@1+ (1,0) [0|0] "" X
 SG_ EPBR_a183_cdpNotAvailable m3: 6|1@1+ (1,0) [0|0] "" X
 SG_ EPBR_a184_dynamicParkAbort m3: 7|1@1+ (1,0) [0|0] "" X
 SG_ EPBR_a185_summonAborted m3: 8|1@1+ (1,0) [0|0] "" X
 SG_ EPBR_a186_externalParkAbort m3: 9|1@1+ (1,0) [0|0] "" X
 SG_ EPBR_a187_cdpDynamic m3: 10|1@1+ (1,0) [0|0] "" X
 SG_ EPBR_a188_epbDynamic m3: 11|1@1+ (1,0) [0|0] "" X
 SG_ EPBR_a189_epbDynamicParkCanceled m3: 12|1@1+ (1,0) [0|0] "" X
 SG_ EPBR_a190_csmApplyDegraded m3: 13|1@1+ (1,0) [0|0] "" X
 SG_ EPBR_a191_csmReleaseDegraded m3: 14|1@1+ (1,0) [0|0] "" X
 SG_ EPBR_a195_parkForDriverIsLeaving m3: 18|1@1+ (1,0) [0|0] "" X
 SG_ EPBR_a200_PmUnparkNotAllowed m3: 23|1@1+ (1,0) [0|0] "" X
 SG_ EPBR_a201_hwBrakeTypeMismatch m3: 24|1@1+ (1,0) [0|0] "" X
 SG_ EPBR_a216_SPI_MIA_debugData1 m3: 39|1@1+ (1,0) [0|0] "" X
 SG_ EPBR_a217_SPI_MIA_debugData2 m3: 40|1@1+ (1,0) [0|0] "" X
 SG_ EPBR_a241_diOutputLocked m4: 4|1@1+ (1,0) [0|0] "" X
 SG_ EPBR_a242_hvOutputLocked m4: 5|1@1+ (1,0) [0|0] "" X
 SG_ EPBR_a243_bdwUnavailable m4: 6|1@1+ (1,0) [0|0] "" X
 SG_ EPBR_a244_WinchModeActive m4: 7|1@1+ (1,0) [0|0] "" X
 SG_ EPBR_a245_serviceModeActive m4: 8|1@1+ (1,0) [0|0] "" X
 SG_ EPBR_a246_idleFaultApply m4: 9|1@1+ (1,0) [0|0] "" X
 SG_ EPBR_a247_csmDynamicApplyRetry m4: 10|1@1+ (1,0) [0|0] "" X
 SG_ EPBR_a248_csmDynamicApplyFailed m4: 11|1@1+ (1,0) [0|0] "" X
 SG_ EPBR_a249_idleFaultRelease m4: 12|1@1+ (1,0) [0|0] "" X
 SG_ EPBR_a250_WinchModeCanceled m4: 13|1@1+ (1,0) [0|0] "" X
 SG_ EPBR_a251_currentVarianceHigh m4: 14|1@1+ (1,0) [0|0] "" X

BO_ 1001 ID3E9DAS_bodyControls: 8 VehicleBus
 SG_ DAS_bodyControlsChecksum : 56|8@1+ (1,0) [0|255] ""  Receiver
 SG_ DAS_bodyControlsCounter : 52|4@1+ (1,0) [0|15] ""  Receiver
 SG_ DAS_dynamicBrakeLightRequest : 22|1@1+ (1,0) [0|1] ""  Receiver
 SG_ DAS_hazardLightRequest : 2|2@1+ (1,0) [0|3] ""  Receiver
 SG_ DAS_headlightRequest : 0|2@1+ (1,0) [0|3] ""  Receiver
 SG_ DAS_heaterRequest : 13|2@1+ (1,0) [0|2] ""  Receiver
 SG_ DAS_highLowBeamDecision : 11|2@1+ (1,0) [0|3] ""  Receiver
 SG_ DAS_highLowBeamOffReason : 15|3@1+ (1,0) [0|5] ""  Receiver
 SG_ DAS_turnIndicatorRequest : 8|3@1+ (1,0) [0|4] ""  Receiver
 SG_ DAS_turnIndicatorRequestReason : 18|4@1+ (1,0) [0|12] ""  Receiver
 SG_ DAS_wiperSpeed : 4|4@1+ (1,0) [0|15] ""  Receiver
 SG_ DAS_radarHeaterRequest : 23|1@1+ (1,0) [0|1] ""  Receiver
 SG_ DAS_ahlbOverride : 24|1@1+ (1,0) [0|1] ""  Receiver
 SG_ DAS_mirrorFoldRequest : 25|2@1+ (1,0) [0|0] ""  Receiver

BO_ 1009 VCFRONT_lighting: 8 VEH
 SG_ VCFRONT_DRLLeftStatus: 36|2@1+ (1,0) [0|0] "" X
 SG_ VCFRONT_DRLRightStatus: 38|2@1+ (1,0) [0|0] "" X
 SG_ VCFRONT_ambientLightingBrightnes: 8|8@1+ (0.5,0) [0|0] "%" X
 SG_ VCFRONT_approachLightingRequest: 25|1@1+ (1,0) [0|0] "" X
 SG_ VCFRONT_courtesyLightingRequest: 24|1@1+ (1,0) [0|0] "" X
 SG_ VCFRONT_fogLeftStatus: 40|2@1+ (1,0) [0|0] "" X
 SG_ VCFRONT_fogRightStatus: 42|2@1+ (1,0) [0|0] "" X
 SG_ VCFRONT_hazardLightRequest: 4|3@1+ (1,0) [0|0] "" X
 SG_ VCFRONT_hazardSwitchBacklight: 27|1@1+ (1,0) [0|0] "" X
 SG_ VCFRONT_highBeamLeftStatus: 32|2@1+ (1,0) [0|0] "" X
 SG_ VCFRONT_highBeamRightStatus: 34|2@1+ (1,0) [0|0] "" X
 SG_ VCFRONT_highBeamSwitchActive: 58|1@1+ (1,0) [0|0] "" X
 SG_ VCFRONT_indicatorLeftRequest: 0|2@1+ (1,0) [0|0] "" X
 SG_ VCFRONT_indicatorRightRequest: 2|2@1+ (1,0) [0|0] "" X
 SG_ VCFRONT_lowBeamLeftStatus: 28|2@1+ (1,0) [0|0] "" X
 SG_ VCFRONT_lowBeamRightStatus: 30|2@1+ (1,0) [0|0] "" X
 SG_ VCFRONT_lowBeamsCalibrated: 62|1@1+ (1,0) [0|0] "" X
 SG_ VCFRONT_lowBeamsOnForDRL: 61|1@1+ (1,0) [0|0] "" X
 SG_ VCFRONT_parkLeftStatus: 54|2@1+ (1,0) [0|0] "" X
 SG_ VCFRONT_parkRightStatus: 56|2@1+ (1,0) [0|0] "" X
 SG_ VCFRONT_seeYouHomeLightingReq: 26|1@1+ (1,0) [0|0] "" X
 SG_ VCFRONT_sideMarkersStatus: 44|2@1+ (1,0) [0|0] "" X
 SG_ VCFRONT_sideRepeaterLeftStatus: 46|2@1+ (1,0) [0|0] "" X
 SG_ VCFRONT_sideRepeaterRightStatus: 48|2@1+ (1,0) [0|0] "" X
 SG_ VCFRONT_simLatchingStalk: 59|2@1+ (1,0) [0|0] "" X
 SG_ VCFRONT_switchLightingBrightness: 16|8@1+ (0.5,0) [0|0] "%" X
 SG_ VCFRONT_turnSignalLeftStatus: 50|2@1+ (1,0) [0|0] "" X
 SG_ VCFRONT_turnSignalRightStatus: 52|2@1+ (1,0) [0|0] "" X

BO_ 1010 ID3F2BMSCounters: 8 VehicleBus
 SG_ BMS_kwhCounter_Id M : 0|4@1+ (1,0) [0|0] ""  Receiver
 SG_ BMS_kwhDcChargeTotalModule3 m9 : 36|28@1+ (0.001,0) [0|0] "KWh"  Receiver
 SG_ BMS_kwhChargeTotalModule2 m6 : 36|28@1+ (0.001,0) [0|0] "KWh"  Receiver
 SG_ BMS_kwhDcChargeTotalModule2 m7 : 36|28@1+ (0.001,0) [0|0] "KWh"  Receiver
 SG_ BMS_kwhChargeTotalModule4 m10 : 36|28@1+ (0.001,0) [0|0] "KWh"  Receiver
 SG_ BMS_kwhDcChargeTotalModule4 m11 : 36|28@1+ (0.001,0) [0|0] "KWh"  Receiver
 SG_ BMS_kwhDcChargeTotalModule1 m5 : 36|28@1+ (0.001,0) [0|0] "KWh"  Receiver
 SG_ BMS_kwhChargeTotalModule1 m4 : 36|28@1+ (0.001,0) [0|0] "KWh"  Receiver
 SG_ BMS_kwhChargeTotalModule3 m8 : 36|28@1+ (0.001,0) [0|0] "KWh"  Receiver
 SG_ BMS_kwhAcChargeTotalModule3 m9 : 8|28@1- (0.001,0) [0|0] "KWh"  Receiver
 SG_ BMS_kwhDischargeTotalModule2 m6 : 8|28@1- (0.001,0) [0|0] "KWh"  Receiver
 SG_ BMS_kwhAcChargeTotalModule2 m7 : 8|28@1- (0.001,0) [0|0] "KWh"  Receiver
 SG_ BMS_kwhDischargeTotalModule4 m10 : 8|28@1- (0.001,0) [0|0] "KWh"  Receiver
 SG_ BMS_kwhAcChargeTotalModule4 m11 : 8|28@1- (0.001,0) [0|0] "KWh"  Receiver
 SG_ BMS_kwhAcChargeTotalModule1 m5 : 8|28@1- (0.001,0) [0|0] "KWh"  Receiver
 SG_ BMS_kwhDriveDischargeTotal m3 : 8|32@1+ (0.001,0) [0|0] "KWh"  Receiver
 SG_ BMS_dcChargerKwhTotal m1 : 8|32@1+ (0.001,0) [0|0] "KWh"  Receiver
 SG_ BMS_kwhDischargeTotalModule1 m4 : 8|28@1- (0.001,0) [0|0] "KWh"  Receiver
 SG_ BMS_acChargerKwhTotal m0 : 8|32@1+ (0.001,0) [0|0] "KWh"  Receiver
 SG_ BMS_kwhRegenChargeTotal m2 : 8|32@1+ (0.001,0) [0|0] "KWh"  Receiver
 SG_ BMS_kwhDischargeTotalModule3 m8 : 8|28@1- (0.001,0) [0|0] "KWh"  Receiver

BO_ 1011 ID3F3UI_odo: 3 ChassisBus
 SG_ UI_odometer : 0|24@1+ (0.1,0) [0|1677720] "km"  Receiver

BO_ 1012 APP_camCalibrationStatus: 6 CH
 SG_ APP_cameraPosition M: 0|4@1+ (1,0) [0|0] "" X
 SG_ APP_mainCamExtPitchCal m1: 8|9@1+ (0.05,-12.5) [0|0] "deg" X
 SG_ APP_mainCamExtYawCal m1: 17|9@1+ (0.05,-12.5) [0|0] "deg" X
 SG_ APP_mainCalibTime m1: 26|7@1+ (1,0) [0|0] "min" X
 SG_ APP_mainCalibProgress m1: 33|7@1+ (1,0) [0|0] "percent" X
 SG_ APP_mainCalibrated m1: 40|1@1+ (1,0) [0|0] "" X
 SG_ APP_narrowCamExtPitchCal m2: 8|9@1+ (0.05,-12.5) [0|0] "deg" X
 SG_ APP_narrowCamExtYawCal m2: 17|9@1+ (0.05,-12.5) [0|0] "deg" X
 SG_ APP_narrowCalibTime m2: 26|7@1+ (1,0) [0|0] "min" X
 SG_ APP_narrowCalibProgress m2: 33|7@1+ (1,0) [0|0] "percent" X
 SG_ APP_narrowCalibrated m2: 40|1@1+ (1,0) [0|0] "" X
 SG_ APP_fisheyeCamExtPitchCal m3: 8|9@1+ (0.05,-12.5) [0|0] "deg" X
 SG_ APP_fisheyeCamExtYawCal m3: 17|9@1+ (0.05,-12.5) [0|0] "deg" X
 SG_ APP_fisheyeCalibTime m3: 26|7@1+ (1,0) [0|0] "min" X
 SG_ APP_fisheyeCalibProgress m3: 33|7@1+ (1,0) [0|0] "percent" X
 SG_ APP_fisheyeCalibrated m3: 40|1@1+ (1,0) [0|0] "" X
 SG_ APP_lPillarCamExtPitchCal m4: 8|9@1+ (0.05,-12.5) [0|0] "deg" X
 SG_ APP_lPillarCamExtYawCal m4: 17|9@1+ (0.05,-12.5) [0|0] "deg" X
 SG_ APP_lPillarCalibTime m4: 26|7@1+ (1,0) [0|0] "min" X
 SG_ APP_lPillarCalibProgress m4: 33|7@1+ (1,0) [0|0] "percent" X
 SG_ APP_lPillarCalibrated m4: 40|1@1+ (1,0) [0|0] "" X
 SG_ APP_rPillarCamExtPitchCal m5: 8|9@1+ (0.05,-12.5) [0|0] "deg" X
 SG_ APP_rPillarCamExtYawCal m5: 17|9@1+ (0.05,-12.5) [0|0] "deg" X
 SG_ APP_rPillarCalibTime m5: 26|7@1+ (1,0) [0|0] "min" X
 SG_ APP_rPillarCalibProgress m5: 33|7@1+ (1,0) [0|0] "percent" X
 SG_ APP_rPillarCalibrated m5: 40|1@1+ (1,0) [0|0] "" X
 SG_ APP_lRepeatCamExtPitchCal m6: 8|9@1+ (0.05,-12.5) [0|0] "deg" X
 SG_ APP_lRepeatCamExtYawCal m6: 17|9@1+ (0.05,-12.5) [0|0] "deg" X
 SG_ APP_lRepeatCalibTime m6: 26|7@1+ (1,0) [0|0] "min" X
 SG_ APP_lRepeatCalibProgress m6: 33|7@1+ (1,0) [0|0] "percent" X
 SG_ APP_lRepeatCalibrated m6: 40|1@1+ (1,0) [0|0] "" X
 SG_ APP_rRepeatCamExtPitchCal m7: 8|9@1+ (0.05,-12.5) [0|0] "deg" X
 SG_ APP_rRepeatCamExtYawCal m7: 17|9@1+ (0.05,-12.5) [0|0] "deg" X
 SG_ APP_rRepeatCalibTime m7: 26|7@1+ (1,0) [0|0] "min" X
 SG_ APP_rRepeatCalibProgress m7: 33|7@1+ (1,0) [0|0] "percent" X
 SG_ APP_rRepeatCalibrated m7: 40|1@1+ (1,0) [0|0] "" X
 SG_ APP_backupCamExtPitchCal m8: 8|9@1+ (0.05,-12.5) [0|0] "deg" X
 SG_ APP_backupCamExtYawCal m8: 17|9@1+ (0.05,-12.5) [0|0] "deg" X
 SG_ APP_backupCalibTime m8: 26|7@1+ (1,0) [0|0] "min" X
 SG_ APP_backupCalibProgress m8: 33|7@1+ (1,0) [0|0] "percent" X
 SG_ APP_backupCalibrated m8: 40|1@1+ (1,0) [0|0] "" X

CM_ BO_ 917 "swapped with 396 in old firmware";
CM_ BO_ 918 "swapped with 395 in old firmware";
VAL_ 881 RCM_matrixIndex 0 "AlertMatrix0" 1 "AlertMatrix1";
VAL_ 882 EPAS3S_torsionBarTorque 4095 "SNA" 4094 "UNDEFINABLE_DATA" ;
VAL_ 883 EPAS3P_torsionBarTorque 4095 "SNA" 4094 "UNDEFINABLE_DATA" ;
VAL_ 884 BMS_log1MuxId 10 "BMS_LOG1_BANDOLIER_MODEL_PACK_TEMPS" 11 "BMS_LOG1_BANDOLIER_MODEL_THERMISTOR_TEMPS_1" 12 "BMS_LOG1_BANDOLIER_MODEL_THERMISTOR_TEMPS_2" 20 "BMS_LOG1_CHARGE_ENERGY_1" 21 "BMS_LOG1_CHARGE_ENERGY_2" 22 "BMS_LOG1_CHARGE_ENERGY_3" 23 "BMS_LOG1_CHARGE_ENERGY_4" 8 "BMS_LOG1_CHARGE_INTERFACE_1" 9 "BMS_LOG1_CHARGE_INTERFACE_2" 24 "BMS_LOG1_CHARGE_LIMIT_1" 25 "BMS_LOG1_CHARGE_LIMIT_2" 14 "BMS_LOG1_CHARGE_REGULATION" 13 "BMS_LOG1_CHARGE_TERMINATION" 0 "BMS_LOG1_CPU_USAGE1" 1 "BMS_LOG1_CPU_USAGE2" 2 "BMS_LOG1_CPU_USAGE3" 17 "BMS_LOG1_IMPEDANCE_DEVIATION_1" 18 "BMS_LOG1_IMPEDANCE_DEVIATION_2" 6 "BMS_LOG1_NEG_CTR_HEALTH_1" 7 "BMS_LOG1_NEG_CTR_HEALTH_2" 19 "BMS_LOG1_PACK_DATA" 4 "BMS_LOG1_POS_CTR_HEALTH_1" 5 "BMS_LOG1_POS_CTR_HEALTH_2" 26 "BMS_LOG1_SLEEP_CURRENT_1" 27 "BMS_LOG1_SLEEP_CURRENT_2" 15 "BMS_LOG1_SOC_BY_DELTA_V_1" 16 "BMS_LOG1_SOC_BY_DELTA_V_2" 3 "BMS_LOG1_STATES_AND_BOOLS" ;
VAL_ 886 DIF_inverterTQF 0 "INVERTERT_INIT" 1 "INVERTERT_IRRATIONAL" 2 "INVERTERT_RATIONAL" 3 "INVERTERT_UNKNOWN" ;
VAL_ 890 DAS_TP_multiplexer 0 "START" 1 "LEFT_LANE" 2 "RIGHT_LANE" 3 "HPP" 4 "NAV" 5 "VIRTUAL_LANE" 6 "LEFT_BOTTS_DOTS" 7 "RIGHT_BOTTS_DOTS" 8 "LANE_INFO" 9 "END";
VAL_ 890 DAS_TP_llType 0 "UNDECIDED" 1 "SOLID" 2 "ROAD_EDGE" 3 "DASHED" 4 "DOUBLE_LANE" 5 "BOTTS_DOTS" 6 "BARRIER" 7 "INVALID";
VAL_ 890 DAS_TP_rlType 0 "UNDECIDED" 1 "SOLID" 2 "ROAD_EDGE" 3 "DASHED" 4 "DOUBLE_LANE" 5 "BOTTS_DOTS" 6 "BARRIER" 7 "INVALID";
VAL_ 894 PARK_matrixIndex 0 "AlertMatrix0" 1 "AlertMatrix1";
VAL_ 897 VCFRONT_logging1HzIndex 18 "BODY_CONTROL" 0 "COOLANT" 19 "COOLANT_2" 2 "COOLANT_VALVE" 20 "END" 1 "FAN_DEMAND_CONDENSER_AND_FET_TEMPS" 3 "HCML_LED_TEMPS" 4 "HCMR_LED_TEMPS" 6 "HEADLAMP_AIM" 5 "HOMELINK" 15 "HP_ARBITRATION" 9 "HP_CONTROL_LOOP_AND_STATE" 10 "HP_CYCLE_MODEL" 8 "HP_DATA_AND_ACCUMULATORS" 12 "HP_DISSIPATION_AND_POWER" 11 "HP_EXV_CALIBRATION" 7 "HP_EXV_RANGE" 17 "HP_MODE_OPTIONS_AND_ESTIMATES" 16 "HP_MODE_SELECT_AND_ESTIMATES" 14 "HP_PRESSURE_CONTROL" 13 "HP_TEMPS_AND_DEMANDS" ;
VAL_ 897 VCFRONT_HCML_bladeTemp 128 "SNA" ;
VAL_ 897 VCFRONT_HCML_diffuseTemp 128 "SNA" ;
VAL_ 897 VCFRONT_HCML_highBeamTemp 128 "SNA" ;
VAL_ 897 VCFRONT_HCML_lowBeamSpotTemp 128 "SNA" ;
VAL_ 897 VCFRONT_HCML_turnTemp 128 "SNA" ;
VAL_ 897 VCFRONT_HCMR_bladeTemp 128 "SNA" ;
VAL_ 897 VCFRONT_HCMR_diffuseTemp 128 "SNA" ;
VAL_ 897 VCFRONT_HCMR_highBeamTemp 128 "SNA" ;
VAL_ 897 VCFRONT_HCMR_lowBeamSpotTemp 128 "SNA" ;
VAL_ 897 VCFRONT_HCMR_turnTemp 128 "SNA" ;
VAL_ 897 VCFRONT_coolantValveCountRange 1023 "SNA" ;
VAL_ 897 VCFRONT_coolantValveRadBypass 127 "SNA" ;
VAL_ 897 VCFRONT_coolantValveRecalReason 3 "CALIBRATION_FAULT_NO_TRAVEL" 2 "GENERAL_FAULT" 1 "MAX_TRAVEL" 5 "MOTOR_FEEDBACK_INTERRUPTED" 6 "NVRAM_LOSS" 4 "SELF_TEST" 7 "SYSTEM_LEVEL_FAULT_RESPONSE" 0 "UNDEFINED" ;
VAL_ 897 VCFRONT_drlMode 2 "DRL_MODE_DRL" 0 "DRL_MODE_OFF" 1 "DRL_MODE_POSITION" ;
VAL_ 897 VCFRONT_homelinkRegionCode 5 "HOMELINK_REGION_CODE_AMERICAS" 9 "HOMELINK_REGION_CODE_CHINA" 1 "HOMELINK_REGION_CODE_EUROPE" 8 "HOMELINK_REGION_CODE_REST_OF_WORLD" 0 "HOMELINK_REGION_CODE_UNKNOWN" ;
VAL_ 897 VCFRONT_hpMode 2 "AMBIENT_SOURCE" 15 "BATTERY_COOL" 17 "BATTERY_COOL_CABIN_CONDENSER" 16 "BATTERY_COOL_CABIN_CONDENSER_REHEAT" 18 "BATTERY_COOL_CABIN_REHEAT" 19 "BATTERY_COOL_EVAPORATOR" 13 "BATTERY_HEAT_AMBIENT_SOURCE" 14 "BATTERY_HEAT_COP1" 11 "CABIN_COOL_EVAPORATOR" 12 "CABIN_COOL_EVAPORATOR_REHEAT" 4 "CABIN_HEAT_AMBIENT_SOURCE" 10 "CABIN_HEAT_BATTERY_COOL_REHEAT" 9 "CABIN_HEAT_BATTERY_HEAT_REHEAT_AMBIENT_SOURCE" 7 "CABIN_HEAT_BLEND" 8 "CABIN_HEAT_COP1" 6 "CABIN_HEAT_REHEAT_AMBIENT_SOURCE" 5 "CABIN_HEAT_REHEAT_SCAVENGE" 3 "CABIN_HEAT_SCAVENGE_ONLY" 1 "GENERAL" 0 "NONE" ;
VAL_ 897 VCFRONT_hpRefrigerantPurgeState 2 "COMPLETE" 1 "EVAP_PURGE" 0 "IDLE" ;
VAL_ 897 VCFRONT_modeDesired 3 "AMBIENT_SOURCE" 2 "BLEND" 1 "PARALLEL" 0 "SERIES" ;
VAL_ 897 VCFRONT_modeTransitionID 23 "ENTER_AMBIENTSOURCE" 24 "EXIT_AMBIENTSOURCE" 20 "INIT" 21 "OVERRIDE" 6 "PARALLEL_2_drive_batteryWantsHeat" 7 "PARALLEL_3_drive_batteryWantsCool" 8 "PARALLEL_4_drive_batteryNeedsCool" 11 "PARALLEL_5_charge_batteryWantsHeat" 12 "PARALLEL_6_charge_batteryWantsCool" 15 "PARALLEL_7_fastCharge_batteryWantsCool" 16 "PARALLEL_8_fastCharge_batteryWantsHeat" 19 "PARALLEL_9_drive_batteryThermalLimiting" 0 "PARALLEL_F1_noFlowRequest" 33 "PAR_1_drive_battNeedsActiveCooling_evapDisabled" 34 "PAR_2_drive_ptNeedsActiveCooling" 35 "PAR_3_drive_chillerPassivelyCoolsBatt" 36 "PAR_4_drive_cannotPassivelyCoolBatt" 37 "PAR_5_drive_battAboveHotStagnationTemp" 38 "PAR_6_FC_battNeedsActiveCooling_evapDisabled" 39 "PAR_7_FC_battNeedsActiveCooling_evapEnabled" 40 "PAR_8_charge_battAbovePassiveTarget" 3 "SERIES_1_drive_batteryWantsCool" 4 "SERIES_2_drive_batteryNeedsHeat" 5 "SERIES_3_drive_batteryWantsHeat" 9 "SERIES_4_charge_batteryNeedsHeat" 10 "SERIES_5_charge_batteryWantsHeat" 13 "SERIES_6_fastCharge_batteryNeedsHeat" 14 "SERIES_7_fastCharge_batteryWantsCool" 17 "SERIES_8_preConditioning_batteryNeedsHeat" 18 "SERIES_9_drive_driveUnitThermalLimiting" 1 "SERIES_F2_faultPumps" 2 "SERIES_F3_faultTempSensors" 25 "SER_1_drive_battNeedsActiveCooling_evapEnabled" 26 "SER_2_drive_battBelowHotStagnationTemp" 27 "SER_3_drive_chillerPassivelyCools" 28 "SER_4_drive_radPassivelyCoolsBatt" 29 "SER_5_FC_battHeatingNeeded" 30 "SER_6_FC_battNeedsActiveCooling_evapDisabled" 31 "SER_7_FC_battNeedsActiveCooling_evapEnabled" 32 "SER_8_charge_battBelowPassiveTarget" 22 "UNDEFINED" ;
VAL_ 897 VCFRONT_passiveCoolingState 3 "CannotCoolBattery" 2 "ChillerAndRadCoolSeriesLoop" 1 "ChillerCoolsParallelBattLoop" 0 "ChillerCoolsSeriesLoop" ;
VAL_ 897 VCFRONT_pumpBatteryFETTemp 255 "SNA" ;
VAL_ 897 VCFRONT_pumpPowertrainFETTemp 255 "SNA" ;
VAL_ 897 VCFRONT_radiatorFanFETTemp 255 "SNA" ;
VAL_ 897 VCFRONT_radiatorFanRunReason 1 "ACTIVE_MANAGER" 2 "AMBIENT_SNIFF" 5 "COAST_MODE" 4 "HEAT_PUMP" 6 "MIN_ON_GLOBAL" 7 "MIN_ON_NVH" 0 "NONE" 3 "NVH_MASKING" 8 "UDS" ;
VAL_ 897 VCFRONT_tempRefrigSuction 255 "SNA" ;
VAL_ 899 VCRIGHT_estimatedThsSolarLoad 1023 "SNA" ;
VAL_ 899 VCRIGHT_estimatedVehicleSituatio 1 "VEHICLE_SITUATION_INDOOR" 2 "VEHICLE_SITUATION_OUTDOOR" 0 "VEHICLE_SITUATION_UNKNOWN" ;
VAL_ 899 VCRIGHT_thsHumidity 255 "SNA" ;
VAL_ 899 VCRIGHT_thsSolarLoadInfrared 1023 "SNA" ;
VAL_ 899 VCRIGHT_thsSolarLoadVisible 1023 "SNA" ;
VAL_ 899 VCRIGHT_thsTemperature 128 "SNA" ;
VAL_ 904 GTW_CH_faultConfinement 2 "BUS_OFF" 0 "ERROR_ACTIVE" 1 "ERROR_PASSIVE" ;
VAL_ 904 GTW_PARTY_faultConfinement 2 "BUS_OFF" 0 "ERROR_ACTIVE" 1 "ERROR_PASSIVE" ;
VAL_ 904 GTW_VEH_faultConfinement 2 "BUS_OFF" 0 "ERROR_ACTIVE" 1 "ERROR_PASSIVE" ;
VAL_ 905 DAS_ACC_report 24 "ACC_REPORT_BEHAVIOR_REPORT" 23 "ACC_REPORT_CAMERA_ONLY" 21 "ACC_REPORT_CIPV_CUTTING_OUT" 10 "ACC_REPORT_CSA" 18 "ACC_REPORT_FLEET_SPEEDS" 13 "ACC_REPORT_LC_EXTERNAL_STATE_ABORTED" 12 "ACC_REPORT_LC_EXTERNAL_STATE_ABORTING" 14 "ACC_REPORT_LC_EXTERNAL_STATE_ACTIVE_RESTRICTED" 11 "ACC_REPORT_LC_HANDS_ON_REQD_STRUCK_OUT" 19 "ACC_REPORT_MCVLR_DPP" 20 "ACC_REPORT_MCVLR_IN_PATH" 22 "ACC_REPORT_RADAR_OBJ_FIVE" 15 "ACC_REPORT_RADAR_OBJ_ONE" 16 "ACC_REPORT_RADAR_OBJ_TWO" 1 "ACC_REPORT_TARGET_CIPV" 5 "ACC_REPORT_TARGET_CUTIN" 2 "ACC_REPORT_TARGET_IN_FRONT_OF_CIPV" 17 "ACC_REPORT_TARGET_MCP" 3 "ACC_REPORT_TARGET_MCVL" 4 "ACC_REPORT_TARGET_MCVR" 0 "ACC_REPORT_TARGET_NONE" 9 "ACC_REPORT_TARGET_TYPE_FAULT" 8 "ACC_REPORT_TARGET_TYPE_IPSO" 6 "ACC_REPORT_TARGET_TYPE_STOP_SIGN" 7 "ACC_REPORT_TARGET_TYPE_TRAFFIC_LIGHT" ;
VAL_ 905 DAS_accSpeedLimit 0 "NONE" 1023 "SNA" ;
VAL_ 905 DAS_activationFailureStatus 1 "LC_ACTIVATION_FAILED_1" 2 "LC_ACTIVATION_FAILED_2" 0 "LC_ACTIVATION_IDLE" ;
VAL_ 905 DAS_csaState 1 "CSA_EXTERNAL_STATE_AVAILABLE" 2 "CSA_EXTERNAL_STATE_ENABLE" 3 "CSA_EXTERNAL_STATE_HOLD" 0 "CSA_EXTERNAL_STATE_UNAVAILABLE" ;
VAL_ 905 DAS_driverInteractionLevel 2 "CONTINUED_DRIVER_NOT_INTERACTING" 0 "DRIVER_INTERACTING" 1 "DRIVER_NOT_INTERACTING" ;
VAL_ 905 DAS_longCollisionWarning 3 "FCM_LONG_COLLISION_WARNING_IPSO" 0 "FCM_LONG_COLLISION_WARNING_NONE" 2 "FCM_LONG_COLLISION_WARNING_PEDESTRIAN" 15 "FCM_LONG_COLLISION_WARNING_SNA" 4 "FCM_LONG_COLLISION_WARNING_STOPSIGN_STOPLINE" 5 "FCM_LONG_COLLISION_WARNING_TFL_STOPLINE" 6 "FCM_LONG_COLLISION_WARNING_VEHICLE_CIPV" 12 "FCM_LONG_COLLISION_WARNING_VEHICLE_CIPV2" 7 "FCM_LONG_COLLISION_WARNING_VEHICLE_CUTIN" 8 "FCM_LONG_COLLISION_WARNING_VEHICLE_MCVL" 9 "FCM_LONG_COLLISION_WARNING_VEHICLE_MCVL2" 10 "FCM_LONG_COLLISION_WARNING_VEHICLE_MCVR" 11 "FCM_LONG_COLLISION_WARNING_VEHICLE_MCVR2" 1 "FCM_LONG_COLLISION_WARNING_VEHICLE_UNKNOWN" ;
VAL_ 905 DAS_pmmCameraFaultReason 1 "PMM_CAMERA_BLOCKED_FRONT" 2 "PMM_CAMERA_INVALID_MIA" 0 "PMM_CAMERA_NO_FAULT" ;
VAL_ 905 DAS_pmmLoggingRequest 0 "FALSE" 1 "TRUE" ;
VAL_ 905 DAS_pmmObstacleSeverity 6 "PMM_ACCEL_LIMIT" 3 "PMM_BRAKE_REQUEST" 5 "PMM_CRASH_FRONT" 4 "PMM_CRASH_REAR" 2 "PMM_IMMINENT_FRONT" 1 "PMM_IMMINENT_REAR" 0 "PMM_NONE" 7 "PMM_SNA" ;
VAL_ 905 DAS_pmmRadarFaultReason 1 "PMM_RADAR_BLOCKED_FRONT" 2 "PMM_RADAR_INVALID_MIA" 0 "PMM_RADAR_NO_FAULT" ;
VAL_ 905 DAS_pmmSysFaultReason 7 "PMM_FAULT_BRAKE_PEDAL_INHIBIT" 1 "PMM_FAULT_DAS_DISABLED" 5 "PMM_FAULT_DISABLED_BY_USER" 3 "PMM_FAULT_DI_FAULT" 0 "PMM_FAULT_NONE" 6 "PMM_FAULT_ROAD_TYPE" 2 "PMM_FAULT_SPEED" 4 "PMM_FAULT_STEERING_ANGLE_RATE" ;
VAL_ 905 DAS_pmmUltrasonicsFaultReason 3 "PMM_ULTRASONICS_BLOCKED_BOTH" 1 "PMM_ULTRASONICS_BLOCKED_FRONT" 2 "PMM_ULTRASONICS_BLOCKED_REAR" 4 "PMM_ULTRASONICS_INVALID_MIA" 0 "PMM_ULTRASONICS_NO_FAULT" ;
VAL_ 905 DAS_ppOffsetDesiredRamp 128 "PP_NO_OFFSET" ;
VAL_ 905 DAS_radarTelemetry 0 "RADAR_TELEMETRY_IDLE" 1 "RADAR_TELEMETRY_NORMAL" 2 "RADAR_TELEMETRY_URGENT" ;
VAL_ 905 DAS_robState 2 "ROB_STATE_ACTIVE" 0 "ROB_STATE_INHIBITED" 3 "ROB_STATE_MAPLESS" 1 "ROB_STATE_MEASURE" ;
VAL_ 913 EPAS3S_matrixIndex 0 "AlertMatrix0" 1 "AlertMatrix1" 2 "AlertMatrix2";
VAL_ 914 BMS_moduleType 0 "UNKNOWN" 1 "E3_NCT" 2 "E1_NCT" 3 "E3_CT" 4 "E1_CT" 5 "E1_CP" ;
VAL_ 914 BMS_packConfigMultiplexer 0 "Mux0" 1 "Mux1" ;
VAL_ 914 BMS_reservedConfig_0 0 "BMS_CONFIG_0" 1 "BMS_CONFIG_1" 10 "BMS_CONFIG_10" 11 "BMS_CONFIG_11" 12 "BMS_CONFIG_12" 13 "BMS_CONFIG_13" 14 "BMS_CONFIG_14" 15 "BMS_CONFIG_15" 16 "BMS_CONFIG_16" 17 "BMS_CONFIG_17" 18 "BMS_CONFIG_18" 19 "BMS_CONFIG_19" 2 "BMS_CONFIG_2" 20 "BMS_CONFIG_20" 21 "BMS_CONFIG_21" 22 "BMS_CONFIG_22" 23 "BMS_CONFIG_23" 24 "BMS_CONFIG_24" 25 "BMS_CONFIG_25" 26 "BMS_CONFIG_26" 27 "BMS_CONFIG_27" 28 "BMS_CONFIG_28" 29 "BMS_CONFIG_29" 3 "BMS_CONFIG_3" 30 "BMS_CONFIG_30" 31 "BMS_CONFIG_31" 4 "BMS_CONFIG_4" 5 "BMS_CONFIG_5" 6 "BMS_CONFIG_6" 7 "BMS_CONFIG_7" 8 "BMS_CONFIG_8" 9 "BMS_CONFIG_9" ;
VAL_ 915 VCRIGHT_epbmDebugIndex 0 "STATES" 1 "TRANSITIONS";
VAL_ 915 VCRIGHT_epbmCaliperState 0 "UNSAVED" 1 "UNKNOWN" 2 "REAPPLY" 3 "PARK" 4 "OPEN" 5 "SERVICE";
VAL_ 915 VCRIGHT_summonFaultReason 0 "NONE" 1 "DI_MIA" 2 "DAS_MIA" 3 "ESP_MIA" 4 "EPBM_MIA" 5 "DI_FAULT" 6 "DI_APC_FAULT" 7 "DAS_FAULT" 8 "ESP_FAULT" 9 "VEH_CAN_FAULT" 10 "EAC_NOT_ALLOWED" 11 "EPBM_REQUEST" 12 "SPEED" 13 "EXTERNAL" 14 "PARK_MIA" 15 "PM_MIA" 16 "PM_REQUEST" 17 "OOC" 18 "MISMATCH" 19 "EPB_FAULT" 20 "DI_STATE_INVALID" 21 "PASSIVE_REQUEST" 22 "EPBREMOTE_MIA" 23 "REMOTE_SUMMON_FAULTED" 24 "LOCAL_UNIT_FAULTED" 25 "REMOTE_UNIT_FAULTED" 26 "START_IN_UNAVAILABLE" 27 "INVALID_REMOTE_STATE" 28 "REMOTE_DID_NOT_START";
VAL_ 915 VCRIGHT_epbSummonState 0 "INIT" 1 "IDLE" 2 "ARMED" 3 "ACTIVE" 4 "COMPLETE" 5 "FAULT" 6 "UNAVAILABLE";
VAL_ 915 VCRIGHT_epbmSummonState 0 "INIT" 1 "IDLE" 2 "ARMED" 3 "ACTIVE" 4 "COMPLETE" 5 "FAULT" 6 "UNAVAILABLE";
VAL_ 915 VCRIGHT_epbUnitStatus 0 "UNKNOWN" 1 "OPEN" 2 "DYNAMIC" 3 "PARK" 4 "START" 5 "SERVICE" 6 "WINCHMODE" 7 "WINCHMODE_RELEASING" 8 "PARKING" 9 "DYNAMIC_APPLYING" 10 "RELEASING" 11 "SERVICE_RELEASING" 12 "PARK_PENDING" 13 "WINCHMODE_PENDING" 14 "SUMMON" 15 "SUMMON_RELEASING" 16 "SUMMON_PARKING" 17 "EXTERNAL_DYNAMIC" 18 "RELEASING_FOR_EXTERNAL_PARK" 19 "EXTERNAL_PARKING" 20 "DYNAMIC_PARKING" 21 "COUNT";
VAL_ 915 VCRIGHT_epbmFaultStatus 0 "NOMINAL" 1 "RETRY" 2 "FAULT" 3 "FAULT_IDLE";
VAL_ 915 VCRIGHT_epbFaultStatus 0 "NOMINAL" 1 "RETRY" 2 "FAULT" 3 "FAULT_IDLE";
VAL_ 915 VCRIGHT_cdpEnumDummy 0 "IDLE" 1 "VALID" 2 "INVALID";
VAL_ 917 DIR_oilPumpFluidTQF 1 "OIL_PUMP_FLUIDT_HIGH_CONFIDENCE" 0 "OIL_PUMP_FLUIDT_LOW_CONFIDENCE" ;
VAL_ 917 DIR_oilPumpState 2 "OIL_PUMP_COLD_STARTUP" 1 "OIL_PUMP_ENABLE" 6 "OIL_PUMP_FAULTED" 7 "OIL_PUMP_SNA" 0 "OIL_PUMP_STANDBY" ;
VAL_ 918 FrontOilPumpState396 7 "OIL_PUMP_SNA" 6 "OIL_PUMP_FAULTED" 2 "OIL_PUMP_COLD_STARTUP" 1 "OIL_PUMP_ENABLE" 0 "OIL_PUMP_STANDBY" ;
VAL_ 921 DAS_autoLaneChangeState 19 "ALC_ABORT_BLINKER_TURNED_OFF" 18 "ALC_ABORT_LC_HEALTH_BAD" 30 "ALC_ABORT_MISSION_PLAN_INVALID" 20 "ALC_ABORT_OTHER_REASON" 17 "ALC_ABORT_POOR_VIEW_RANGE" 15 "ALC_ABORT_SIDE_OBSTACLE_PRESENT_L" 16 "ALC_ABORT_SIDE_OBSTACLE_PRESENT_R" 29 "ALC_ABORT_TIMEOUT" 8 "ALC_AVAILABLE_BOTH" 6 "ALC_AVAILABLE_ONLY_L" 7 "ALC_AVAILABLE_ONLY_R" 26 "ALC_BLOCKED_LANE_TYPE_L" 27 "ALC_BLOCKED_LANE_TYPE_R" 23 "ALC_BLOCKED_VEH_TTC_AND_USS_L" 25 "ALC_BLOCKED_VEH_TTC_AND_USS_R" 22 "ALC_BLOCKED_VEH_TTC_L" 24 "ALC_BLOCKED_VEH_TTC_R" 9 "ALC_IN_PROGRESS_L" 10 "ALC_IN_PROGRESS_R" 31 "ALC_SNA" 0 "ALC_UNAVAILABLE_DISABLED" 4 "ALC_UNAVAILABLE_EXITING_HIGHWAY" 1 "ALC_UNAVAILABLE_NO_LANES" 21 "ALC_UNAVAILABLE_SOLID_LANE_LINE" 2 "ALC_UNAVAILABLE_SONICS_INVALID" 3 "ALC_UNAVAILABLE_TP_FOLLOW" 5 "ALC_UNAVAILABLE_VEHICLE_SPEED" 13 "ALC_WAITING_FOR_FWD_OBST_TO_PASS_L" 14 "ALC_WAITING_FOR_FWD_OBST_TO_PASS_R" 11 "ALC_WAITING_FOR_SIDE_OBST_TO_PASS_L" 12 "ALC_WAITING_FOR_SIDE_OBST_TO_PASS_R" 28 "ALC_WAITING_HANDS_ON" ;
VAL_ 921 DAS_autoparkReady 1 "AUTOPARK_READY" 0 "AUTOPARK_UNAVAILABLE" ;
VAL_ 921 DAS_autopilotHandsOnState 0 "LC_HANDS_ON_NOT_REQD" 4 "LC_HANDS_ON_REQD_CHIME_1" 5 "LC_HANDS_ON_REQD_CHIME_2" 1 "LC_HANDS_ON_REQD_DETECTED" 9 "LC_HANDS_ON_REQD_ESCALATED_CHIME_1" 10 "LC_HANDS_ON_REQD_ESCALATED_CHIME_2" 2 "LC_HANDS_ON_REQD_NOT_DETECTED" 6 "LC_HANDS_ON_REQD_SLOWING" 7 "LC_HANDS_ON_REQD_STRUCK_OUT" 3 "LC_HANDS_ON_REQD_VISUAL" 15 "LC_HANDS_ON_SNA" 8 "LC_HANDS_ON_SUSPENDED" ;
VAL_ 921 DAS_autopilotState 9 "ABORTED" 8 "ABORTING" 5 "ACTIVE_NAV" 3 "ACTIVE_NOMINAL" 4 "ACTIVE_RESTRICTED" 2 "AVAILABLE" 0 "DISABLED" 14 "FAULT" 15 "SNA" 1 "UNAVAILABLE" ;
VAL_ 921 DAS_blindSpotRearLeft 0 "NO_WARNING" 3 "SNA" 1 "WARNING_LEVEL_1" 2 "WARNING_LEVEL_2" ;
VAL_ 921 DAS_blindSpotRearRight 0 "NO_WARNING" 3 "SNA" 1 "WARNING_LEVEL_1" 2 "WARNING_LEVEL_2" ;
VAL_ 921 DAS_fleetSpeedState 2 "FLEETSPEED_ACTIVE" 1 "FLEETSPEED_AVAILABLE" 3 "FLEETSPEED_HOLD" 0 "FLEETSPEED_UNAVAILABLE" ;
VAL_ 921 DAS_forwardCollisionWarning 1 "FORWARD_COLLISION_WARNING" 0 "NONE" 3 "SNA" ;
VAL_ 921 DAS_fusedSpeedLimit 31 "NONE" 0 "UNKNOWN_SNA" ;
VAL_ 921 DAS_heaterState 0 "HEATER_OFF_SNA" 1 "HEATER_ON" ;
VAL_ 921 DAS_laneDepartureWarning 1 "LEFT_WARNING" 3 "LEFT_WARNING_SEVERE" 0 "NONE" 2 "RIGHT_WARNING" 4 "RIGHT_WARNING_SEVERE" 5 "SNA" ;
VAL_ 921 DAS_lssState 6 "LSS_STATE_ABORT" 5 "LSS_STATE_BLINDSPOT" 3 "LSS_STATE_ELK" 0 "LSS_STATE_FAULT" 1 "LSS_STATE_LDW" 2 "LSS_STATE_LKA" 4 "LSS_STATE_MONITOR" 7 "LSS_STATE_OFF" ;
VAL_ 921 DAS_sideCollisionAvoid 1 "AVOID_LEFT" 2 "AVOID_RIGHT" 0 "NONE" 3 "SNA" ;
VAL_ 921 DAS_sideCollisionInhibit 1 "INHIBIT" 0 "NO_INHIBIT" ;
VAL_ 921 DAS_sideCollisionWarning 0 "NONE" 1 "WARN_LEFT" 3 "WARN_LEFT_RIGHT" 2 "WARN_RIGHT" ;
VAL_ 921 DAS_suppressSpeedWarning 0 "Do_Not_Suppress" 1 "Suppress_Speed_Warning" ;
VAL_ 921 DAS_visionOnlySpeedLimit 31 "NONE" 0 "UNKNOWN_SNA" ;
VAL_ 923 DAS_autoLaneChangeState 5 "ALC_UNAVAILABLE_VEHICLE_SPEED" 17 "ALC_ABORT_POOR_VIEW_RANGE" 23 "ALC_BLOCKED_VEH_TTC_AND_USS_L" 0 "ALC_UNAVAILABLE_DISABLED" 26 "ALC_BLOCKED_LANE_TYPE_L" 29 "ALC_ABORT_TIMEOUT" 9 "ALC_IN_PROGRESS_L" 4 "ALC_UNAVAILABLE_EXITING_HIGHWAY" 22 "ALC_BLOCKED_VEH_TTC_L" 12 "ALC_WAITING_FOR_SIDE_OBST_TO_PASS_R" 18 "ALC_ABORT_LC_HEALTH_BAD" 28 "ALC_WAITING_HANDS_ON" 8 "ALC_AVAILABLE_BOTH" 11 "ALC_WAITING_FOR_SIDE_OBST_TO_PASS_L" 3 "ALC_UNAVAILABLE_TP_FOLLOW" 2 "ALC_UNAVAILABLE_SONICS_INVALID" 21 "ALC_UNAVAILABLE_SOLID_LANE_LINE" 24 "ALC_BLOCKED_VEH_TTC_R" 1 "ALC_UNAVAILABLE_NO_LANES" 25 "ALC_BLOCKED_VEH_TTC_AND_USS_R" 30 "ALC_ABORT_MISSION_PLAN_INVALID" 27 "ALC_BLOCKED_LANE_TYPE_R" 19 "ALC_ABORT_BLINKER_TURNED_OFF" 31 "ALC_SNA" 13 "ALC_WAITING_FOR_FWD_OBST_TO_PASS_L" 16 "ALC_ABORT_SIDE_OBSTACLE_PRESENT_R" 6 "ALC_AVAILABLE_ONLY_L" 20 "ALC_ABORT_OTHER_REASON" 15 "ALC_ABORT_SIDE_OBSTACLE_PRESENT_L" 7 "ALC_AVAILABLE_ONLY_R" 14 "ALC_WAITING_FOR_FWD_OBST_TO_PASS_R" 10 "ALC_IN_PROGRESS_R" ;
VAL_ 923 DAS_autopilotHandsOnState 8 "LC_HANDS_ON_SUSPENDED" 15 "LC_HANDS_ON_SNA" 7 "LC_HANDS_ON_REQD_STRUCK_OUT" 3 "LC_HANDS_ON_REQD_VISUAL" 4 "LC_HANDS_ON_REQD_CHIME_1" 6 "LC_HANDS_ON_REQD_SLOWING" 1 "LC_HANDS_ON_REQD_DETECTED" 2 "LC_HANDS_ON_REQD_NOT_DETECTED" 5 "LC_HANDS_ON_REQD_CHIME_2" 0 "LC_HANDS_ON_NOT_REQD" ;
VAL_ 923 DAS_fleetSpeedState 0 "FLEETSPEED_UNAVAILABLE" 1 "FLEETSPEED_AVAILABLE" 2 "FLEETSPEED_ACTIVE" 3 "FLEETSPEED_HOLD" ;
VAL_ 923 DAS_laneDepartureWarning 5 "SNA" 0 "NONE" 2 "RIGHT_WARNING" 4 "RIGHT_WARNING_SEVERE" 3 "LEFT_WARNING_SEVERE" 1 "LEFT_WARNING" ;
VAL_ 923 DAS_csaState 1 "CSA_EXTERNAL_STATE_AVAILABLE" 3 "CSA_EXTERNAL_STATE_HOLD" 2 "CSA_EXTERNAL_STATE_ENABLE" 0 "CSA_EXTERNAL_STATE_UNAVAILABLE" ;
VAL_ 923 DAS_sideCollisionInhibit 0 "NO_INHIBIT" 1 "INHIBIT" ;
VAL_ 923 DAS_sideCollisionWarning 0 "NONE" 2 "WARN_RIGHT" 1 "WARN_LEFT" 3 "WARN_LEFT_RIGHT" ;
VAL_ 923 DAS_sideCollisionAvoid 3 "SNA" 0 "NONE" 1 "AVOID_LEFT" 2 "AVOID_RIGHT" ;
VAL_ 923 DAS_autoparkReady 0 "AUTOPARK_UNAVAILABLE" 1 "AUTOPARK_READY" ;
VAL_ 923 DAS_forwardCollisionWarning 3 "SNA" 0 "NONE" 1 "FORWARD_COLLISION_WARNING" ;
VAL_ 923 DAS_heaterState 0 "HEATER_OFF_SNA" 1 "HEATER_ON" ;
VAL_ 923 DAS_visionOnlySpeedLimit 31 "NONE" 0 "UNKNOWN_SNA" ;
VAL_ 923 DAS_suppressSpeedWarning 1 "Suppress_Speed_Warning" 0 "Do_Not_Suppress" ;
VAL_ 923 DAS_fusedSpeedLimit 31 "NONE" 0 "UNKNOWN_SNA" ;
VAL_ 923 DAS_blindSpotRearRight 3 "SNA" 0 "NO_WARNING" 1 "WARNING_LEVEL_1" 2 "WARNING_LEVEL_2" ;
VAL_ 923 DAS_blindSpotRearLeft 3 "SNA" 0 "NO_WARNING" 1 "WARNING_LEVEL_1" 2 "WARNING_LEVEL_2" ;
VAL_ 923 DAS_autopilotState 15 "SNA" 8 "ABORTING" 3 "ACTIVE_NOMINAL" 0 "DISABLED" 4 "ACTIVE_RESTRICTED" 5 "ACTIVE_NAV" 6 "ACTIVE_FSD" 14 "FAULT" 1 "UNAVAILABLE" 9 "ABORTED" 2 "AVAILABLE" ;
VAL_ 925 IBST_driverBrakeApply 1 "BRAKES_NOT_APPLIED" 2 "DRIVER_APPLYING_BRAKES" 3 "FAULT" 0 "NOT_INIT_OR_OFF" ;
VAL_ 925 IBST_iBoosterStatus 4 "IBOOSTER_ACTIVE_GOOD_CHECK" 6 "IBOOSTER_ACTUATION" 3 "IBOOSTER_DIAGNOSTIC" 2 "IBOOSTER_FAILURE" 1 "IBOOSTER_INIT" 0 "IBOOSTER_OFF" 5 "IBOOSTER_READY" ;
VAL_ 925 IBST_internalState 4 "DIAGNOSTIC" 3 "EXTERNAL_BRAKE_REQUEST" 2 "LOCAL_BRAKE_REQUEST" 0 "NO_MODE_ACTIVE" 6 "POST_DRIVE_CHECK" 1 "PRE_DRIVE_CHECK" 5 "TRANSITION_TO_IDLE" ;
VAL_ 926 PARK_leftSideFrontRawDistData 255 "SNA";
VAL_ 926 PARK_leftSideRearRawDistData 255 "SNA";
VAL_ 926 PARK_rightSideFrontRawDistData 255 "SNA";
VAL_ 926 PARK_rightSideRearRawDistData 255 "SNA";
VAL_ 929 VCFRONT_12vStatusForDrive 2 "EXIT_DRIVE_REQUESTED_12V" 0 "NOT_READY_FOR_DRIVE_12V" 1 "READY_FOR_DRIVE_12V" ;
VAL_ 929 VCFRONT_2RowCenterUnbuckled 0 "CHIME_NONE" 1 "CHIME_OCCUPIED_AND_UNBUCKLED" 2 "CHIME_SNA" ;
VAL_ 929 VCFRONT_2RowLeftUnbuckled 0 "CHIME_NONE" 1 "CHIME_OCCUPIED_AND_UNBUCKLED" 2 "CHIME_SNA" ;
VAL_ 929 VCFRONT_2RowRightUnbuckled 0 "CHIME_NONE" 1 "CHIME_OCCUPIED_AND_UNBUCKLED" 2 "CHIME_SNA" ;
VAL_ 929 VCFRONT_APGlassHeaterState 4 "HEATER_STATE_FAULT" 2 "HEATER_STATE_OFF" 3 "HEATER_STATE_OFF_UNAVAILABLE" 1 "HEATER_STATE_ON" 0 "HEATER_STATE_SNA" ;
VAL_ 929 VCFRONT_diPowerOnState 0 "DI_POWERED_OFF" 3 "DI_POWERED_ON_FOR_DRIVE" 2 "DI_POWERED_ON_FOR_STATIONARY_HEAT" 1 "DI_POWERED_ON_FOR_SUMMON" 4 "DI_POWER_GOING_DOWN" ;
VAL_ 929 VCFRONT_driverBuckleStatus 1 "BUCKLED" 0 "UNBUCKLED" ;
VAL_ 929 VCFRONT_driverDoorStatus 1 "DOOR_CLOSED" 0 "DOOR_OPEN" ;
VAL_ 929 VCFRONT_driverUnbuckled 0 "CHIME_NONE" 1 "CHIME_OCCUPIED_AND_UNBUCKLED" 2 "CHIME_SNA" ;
VAL_ 929 VCFRONT_passengerUnbuckled 0 "CHIME_NONE" 1 "CHIME_OCCUPIED_AND_UNBUCKLED" 2 "CHIME_SNA" ;
VAL_ 929 VCFRONT_pcsEFuseVoltage 1023 "SNA" ;
VAL_ 929 VCFRONT_thermalSystemType 1 "HEAT_PUMP_THERMAL_SYSTEM" 0 "LEGACY_THERMAL_SYSTEM" ;
VAL_ 930 VCLEFT_statusIndex 0 "MUX0" 1 "MUX1";
VAL_ 930 VCLEFT_vehiclePowerStateDBG 0 "OFF" 1 "CONDITIONING" 2 "ACCESSORY" 3 "DRIVE";
VAL_ 930 VCLEFT_swcInputVoltage 255 "SNA";
VAL_ 930 VCLEFT_swcPCBATemperature -128 "SNA";
VAL_ 930 VCLEFT_tlcPCBATemperature -128 "SNA";
VAL_ 932 PCS_matrixIndex 0 "AlertMatrix0" 1 "AlertMatrix1";
VAL_ 937 DAS_telemetryMultiplexer 0 "ROAD_INFORMATION" 1 "ACC_DRIVER_MONITOR" 2 "TRAFFIC_SIGNS" 7 "CSA_EVENT" 8 "STATIONARY_OBST" 9 "CRUISE_STALK_INPUT";
VAL_ 937 DAS_telLeftLaneType 0 "UNDECIDED" 1 "SOLID" 2 "ROAD_EDGE" 3 "DASHED" 4 "DOUBLE" 5 "BOTTS_DOTS" 6 "BARRIER";
VAL_ 937 DAS_telRightLaneType 0 "UNDECIDED" 1 "SOLID" 2 "ROAD_EDGE" 3 "DASHED" 4 "DOUBLE" 5 "BOTTS_DOTS" 6 "BARRIER";
VAL_ 937 DAS_telLeftMarkerQuality 0 "LOWEST" 1 "LOW" 2 "MEDIUM" 3 "HIGH";
VAL_ 937 DAS_telRightMarkerQuality 0 "LOWEST" 1 "LOW" 2 "MEDIUM" 3 "HIGH";
VAL_ 937 DAS_telLeftMarkerColor 0 "UNKNOWN" 1 "WHITE" 2 "YELLOW" 3 "BLUE";
VAL_ 937 DAS_telRightMarkerColor 0 "UNKNOWN" 1 "WHITE" 2 "YELLOW" 3 "BLUE";
VAL_ 937 DAS_telLeftLaneCrossing 0 "NOT_CROSSING" 1 "CROSSING";
VAL_ 937 DAS_telRightLaneCrossing 0 "NOT_CROSSING" 1 "CROSSING";
VAL_ 937 DAS_soCamCipvStatus 0 "INVALID" 1 "UNFUSED" 2 "FUSED_W_OTHER_RAD_OBJ" 3 "FUSED_W_RAD5";
VAL_ 937 DAS_soRad5Status 0 "INVALID" 1 "UNFUSED" 2 "FUSED_W_CIPV" 3 "FUSED_W_OTHER_CAMOBJ";
VAL_ 937 DAS_soRad1Status 0 "INVALID" 1 "UNFUSED" 2 "FUSED_W_CIPV" 3 "FUSED_W_OTHER_CAMOBJ";
VAL_ 945 DAS_TF_multiplexer 0 "Mux0" 1 "Mux1" 2 "Mux2";
VAL_ 947 UI_autopilotPowerStateRequest 0 "AUTOPILOT_NOMINAL" 1 "AUTOPILOT_SENTRY" 2 "AUTOPILOT_SUSPEND" ;
VAL_ 947 UI_lightSwitch 0 "LIGHT_SWITCH_AUTO" 3 "LIGHT_SWITCH_OFF" 1 "LIGHT_SWITCH_ON" 2 "LIGHT_SWITCH_PARKING" 4 "LIGHT_SWITCH_SNA" ;
VAL_ 947 UI_shorted12VCellTestMode 2 "SHORTED_CELL_TEST_MODE_ACTIVE" 0 "SHORTED_CELL_TEST_MODE_DISABLED" 1 "SHORTED_CELL_TEST_MODE_SHADOW" ;
VAL_ 947 UI_summonState 3 "ACTIVE" 1 "IDLE" 2 "PRE_PRIMED" 0 "SNA" ;
VAL_ 947 UI_windowRequest 3 "WINDOW_REQUEST_GOTO_CLOSED" 4 "WINDOW_REQUEST_GOTO_OPEN" 1 "WINDOW_REQUEST_GOTO_PERCENT" 2 "WINDOW_REQUEST_GOTO_VENT" 0 "WINDOW_REQUEST_IDLE" ;
VAL_ 950 Odometer3B6 4294967 "SNA" ;
VAL_ 960 VCRIGHT_matrixIndex 0 "VCRIGHT_AlertMatrix0" 1 "VCRIGHT_AlertMatrix1" 2 "VCRIGHT_AlertMatrix2" 3 "VCRIGHT_AlertMatrix3" 4 "VCRIGHT_AlertMatrix4" 5 "VCRIGHT_AlertMatrix5" 6 "VCRIGHT_AlertMatrix6" 7 "VCRIGHT_AlertMatrix7" 8 "VCRIGHT_AlertMatrix8" 9 "VCRIGHT_AlertMatrix9" ;
VAL_ 962 VCLEFT_switchStatusIndex 0 "VCLEFT_SWITCH_STATUS_INDEX_0" 1 "VCLEFT_SWITCH_STATUS_INDEX_1" 2 "VCLEFT_SWITCH_STATUS_INDEX_INVALID" ;
VAL_ 962 VCLEFT_frontBuckleSwitch 3 "SWITCH_FAULT" 1 "SWITCH_OFF" 2 "SWITCH_ON" 0 "SWITCH_SNA" ;
VAL_ 962 VCLEFT_frontOccupancySwitch 3 "SWITCH_FAULT" 1 "SWITCH_OFF" 2 "SWITCH_ON" 0 "SWITCH_SNA" ;
VAL_ 962 VCLEFT_frontSeatBackrestBack 3 "SWITCH_FAULT" 1 "SWITCH_OFF" 2 "SWITCH_ON" 0 "SWITCH_SNA" ;
VAL_ 962 VCLEFT_frontSeatBackrestForward 3 "SWITCH_FAULT" 1 "SWITCH_OFF" 2 "SWITCH_ON" 0 "SWITCH_SNA" ;
VAL_ 962 VCLEFT_frontSeatLiftDown 3 "SWITCH_FAULT" 1 "SWITCH_OFF" 2 "SWITCH_ON" 0 "SWITCH_SNA" ;
VAL_ 962 VCLEFT_frontSeatLiftUp 3 "SWITCH_FAULT" 1 "SWITCH_OFF" 2 "SWITCH_ON" 0 "SWITCH_SNA" ;
VAL_ 962 VCLEFT_frontSeatLumbarDown 3 "SWITCH_FAULT" 1 "SWITCH_OFF" 2 "SWITCH_ON" 0 "SWITCH_SNA" ;
VAL_ 962 VCLEFT_frontSeatLumbarIn 3 "SWITCH_FAULT" 1 "SWITCH_OFF" 2 "SWITCH_ON" 0 "SWITCH_SNA" ;
VAL_ 962 VCLEFT_frontSeatLumbarOut 3 "SWITCH_FAULT" 1 "SWITCH_OFF" 2 "SWITCH_ON" 0 "SWITCH_SNA" ;
VAL_ 962 VCLEFT_frontSeatLumbarUp 3 "SWITCH_FAULT" 1 "SWITCH_OFF" 2 "SWITCH_ON" 0 "SWITCH_SNA" ;
VAL_ 962 VCLEFT_frontSeatTiltDown 3 "SWITCH_FAULT" 1 "SWITCH_OFF" 2 "SWITCH_ON" 0 "SWITCH_SNA" ;
VAL_ 962 VCLEFT_frontSeatTiltUp 3 "SWITCH_FAULT" 1 "SWITCH_OFF" 2 "SWITCH_ON" 0 "SWITCH_SNA" ;
VAL_ 962 VCLEFT_frontSeatTrackBack 3 "SWITCH_FAULT" 1 "SWITCH_OFF" 2 "SWITCH_ON" 0 "SWITCH_SNA" ;
VAL_ 962 VCLEFT_frontSeatTrackForward 3 "SWITCH_FAULT" 1 "SWITCH_OFF" 2 "SWITCH_ON" 0 "SWITCH_SNA" ;
VAL_ 962 VCLEFT_rearCenterBuckleSwitch 3 "SWITCH_FAULT" 1 "SWITCH_OFF" 2 "SWITCH_ON" 0 "SWITCH_SNA" ;
VAL_ 962 VCLEFT_rearCenterOccupancySwitch 3 "SWITCH_FAULT" 1 "SWITCH_OFF" 2 "SWITCH_ON" 0 "SWITCH_SNA" ;
VAL_ 962 VCLEFT_rearLeftBuckleSwitch 3 "SWITCH_FAULT" 1 "SWITCH_OFF" 2 "SWITCH_ON" 0 "SWITCH_SNA" ;
VAL_ 962 VCLEFT_rearLeftOccupancySwitch 3 "SWITCH_FAULT" 1 "SWITCH_OFF" 2 "SWITCH_ON" 0 "SWITCH_SNA" ;
VAL_ 962 VCLEFT_rearRightOccupancySwitch 3 "SWITCH_FAULT" 1 "SWITCH_OFF" 2 "SWITCH_ON" 0 "SWITCH_SNA" ;
VAL_ 962 VCLEFT_rightMirrorTilt 1 "MIRROR_TILT_DOWN" 4 "MIRROR_TILT_LEFT" 3 "MIRROR_TILT_RIGHT" 0 "MIRROR_TILT_STOP" 2 "MIRROR_TILT_UP" ;
VAL_ 962 VCLEFT_swcLeftPressed 3 "SWITCH_FAULT" 1 "SWITCH_OFF" 2 "SWITCH_ON" 0 "SWITCH_SNA" ;
VAL_ 962 VCLEFT_swcLeftTiltLeft 3 "SWITCH_FAULT" 1 "SWITCH_OFF" 2 "SWITCH_ON" 0 "SWITCH_SNA" ;
VAL_ 962 VCLEFT_swcLeftTiltRight 3 "SWITCH_FAULT" 1 "SWITCH_OFF" 2 "SWITCH_ON" 0 "SWITCH_SNA" ;
VAL_ 962 VCLEFT_swcRightPressed 3 "SWITCH_FAULT" 1 "SWITCH_OFF" 2 "SWITCH_ON" 0 "SWITCH_SNA" ;
VAL_ 962 VCLEFT_swcRightTiltLeft 3 "SWITCH_FAULT" 1 "SWITCH_OFF" 2 "SWITCH_ON" 0 "SWITCH_SNA" ;
VAL_ 962 VCLEFT_swcRightTiltRight 3 "SWITCH_FAULT" 1 "SWITCH_OFF" 2 "SWITCH_ON" 0 "SWITCH_SNA" ;
VAL_ 963 VCRIGHT_frontBuckleSwitch 3 "SWITCH_FAULT" 1 "SWITCH_OFF" 2 "SWITCH_ON" 0 "SWITCH_SNA" ;
VAL_ 963 VCRIGHT_frontOccupancySwitch 3 "SWITCH_FAULT" 1 "SWITCH_OFF" 2 "SWITCH_ON" 0 "SWITCH_SNA" ;
VAL_ 963 VCRIGHT_frontSeatBackrestBack 3 "SWITCH_FAULT" 1 "SWITCH_OFF" 2 "SWITCH_ON" 0 "SWITCH_SNA" ;
VAL_ 963 VCRIGHT_frontSeatBackrestForward 3 "SWITCH_FAULT" 1 "SWITCH_OFF" 2 "SWITCH_ON" 0 "SWITCH_SNA" ;
VAL_ 963 VCRIGHT_frontSeatLiftDown 3 "SWITCH_FAULT" 1 "SWITCH_OFF" 2 "SWITCH_ON" 0 "SWITCH_SNA" ;
VAL_ 963 VCRIGHT_frontSeatLiftUp 3 "SWITCH_FAULT" 1 "SWITCH_OFF" 2 "SWITCH_ON" 0 "SWITCH_SNA" ;
VAL_ 963 VCRIGHT_frontSeatLumbarDown 3 "SWITCH_FAULT" 1 "SWITCH_OFF" 2 "SWITCH_ON" 0 "SWITCH_SNA" ;
VAL_ 963 VCRIGHT_frontSeatLumbarIn 3 "SWITCH_FAULT" 1 "SWITCH_OFF" 2 "SWITCH_ON" 0 "SWITCH_SNA" ;
VAL_ 963 VCRIGHT_frontSeatLumbarOut 3 "SWITCH_FAULT" 1 "SWITCH_OFF" 2 "SWITCH_ON" 0 "SWITCH_SNA" ;
VAL_ 963 VCRIGHT_frontSeatLumbarUp 3 "SWITCH_FAULT" 1 "SWITCH_OFF" 2 "SWITCH_ON" 0 "SWITCH_SNA" ;
VAL_ 963 VCRIGHT_frontSeatTiltDown 3 "SWITCH_FAULT" 1 "SWITCH_OFF" 2 "SWITCH_ON" 0 "SWITCH_SNA" ;
VAL_ 963 VCRIGHT_frontSeatTiltUp 3 "SWITCH_FAULT" 1 "SWITCH_OFF" 2 "SWITCH_ON" 0 "SWITCH_SNA" ;
VAL_ 963 VCRIGHT_frontSeatTrackBack 3 "SWITCH_FAULT" 1 "SWITCH_OFF" 2 "SWITCH_ON" 0 "SWITCH_SNA" ;
VAL_ 963 VCRIGHT_frontSeatTrackForward 3 "SWITCH_FAULT" 1 "SWITCH_OFF" 2 "SWITCH_ON" 0 "SWITCH_SNA" ;
VAL_ 963 VCRIGHT_rearCenterBuckleSwitch 3 "SWITCH_FAULT" 1 "SWITCH_OFF" 2 "SWITCH_ON" 0 "SWITCH_SNA" ;
VAL_ 963 VCRIGHT_rearRightBuckleSwitch 3 "SWITCH_FAULT" 1 "SWITCH_OFF" 2 "SWITCH_ON" 0 "SWITCH_SNA" ;
VAL_ 964 PCS_infoIndex 0 "DEPRECATED_0" 1 "DEPRECATED_1" 2 "DEPRECATED_2" 3 "DEPRECATED_3" 4 "DEPRECATED_4" 5 "DEPRECATED_5" 6 "DEPRECATED_6" 7 "DEPRECATED_7" 8 "DEPRECATED_8" 9 "DEPRECATED_9" 10 "BUILD_HWID_COMPONENTID" 11 "PCBAID_ASSYID_USAGEID" 13 "APP_CRC" 14 "BOOTLOADER_SVN" 15 "BOOTLOADER_CRC" 16 "SUBCOMPONENT" 17 "APP_GITHASH" 18 "BOOTLOADER_GITHASH" 19 "VERSION_DEPRECATED" 20 "UDS_PROTOCOL_BOOTCRC" 22 "VARIANTCRC" 25 "PACKAGE_PN_1_7" 26 "PACKAGE_PN_8_14" 27 "PACKAGE_PN_15_20" 29 "PACKAGE_SN_1_7" 30 "PACKAGE_SN_8_14" 31 "SUBCOMPONENT_GITHASH" 255 "END";
VAL_ 964 PCS_buildType 0 "UNKNOWN_BUILD" 1 "PLATFORM_BUILD" 2 "LOCAL_BUILD" 3 "TRACEABLE_CI_BUILD" 4 "MFG_BUILD";
VAL_ 968 EPBL_matrixIndex 0 "AlertMatrix0" 1 "AlertMatrix1" 2 "AlertMatrix2" 3 "AlertMatrix3" 4 "AlertMatrix4";
VAL_ 969 VCSEC_BLEEndpointInfoIndex 0 "LEFT_INFO" 1 "RIGHT_INFO" 2 "REAR_INFO" 3 "CENTER_INFO" 4 "LEFT_APP_GITHASH" 5 "RIGHT_APP_GITHASH" 6 "REAR_APP_GITHASH" 7 "CENTER_APP_GITHASH";
VAL_ 970 APS_canMaster 2 "CAN_MASTER_APB" 1 "CAN_MASTER_APP" 0 "CAN_MASTER_APS" 3 "CAN_MASTER_SNA" ;
VAL_ 979 UI_airbagCutoffSwState 0 "PASSENGER_AIRBAG_ON" 1 "PASSENGER_AIRBAG_OFF" 2 "SNA";
VAL_ 979 UI_warningIndicatorStatus 0 "WARNING_LAMP_OFF" 1 "WARNING_LAMP_ON" 3 "SNA";
VAL_ 981 ESP_matrixIndex 0 "AlertMatrix0" 1 "AlertMatrix1" 2 "AlertMatrix2" 3 "AlertMatrix3" 4 "AlertMatrix4";
VAL_ 985 UI_conditionalSpeedLimit 31 "SNA" ;
VAL_ 985 UI_mapSpeedLimitUnits 1 "KPH" 0 "MPH" ;
VAL_ 985 UI_userSpeedOffsetUnits 1 "KPH" 0 "MPH" ;
VAL_ 986 DAS_TE_multiplexer 0 "START" 1 "LEFT_LANE" 2 "RIGHT_LANE" 3 "HPP" 4 "NAV" 5 "VL" 6 "ACC" 7 "FCM" 8 "IPSO" 9 "END";
VAL_ 986 DAS_TE_eventType 0 "NONE" 1 "DRIVER_INTERVENTION" 2 "AUTOSTEER_ABORT" 3 "ANGLE_SATURATION" 4 "ANGLE_RATE_SATURATION" 5 "LDW_LEFT" 6 "LDW_RIGHT" 7 "ALC_ABORT_LEFT" 8 "ALC_ABORT_RIGHT" 9 "SCA_LEFT" 10 "SCA_RIGHT" 11 "TM_EVENT_IPSO" 12 "TM_EVENT_CRASH" 13 "TM_EVENT_AEB" 14 "TM_EVENT_ROB";
VAL_ 986 DAS_TE_lcAbortReason 0 "HM_LANE_VIEW_RANGE" 1 "HM_VIRTUAL_LANE_NO_INPUTS" 16 "CAM_MSG_MIA" 17 "CAM_WATCHDOG" 18 "TRAILER_MODE" 19 "SIDE_COLLISION_IMMINENT" 20 "EPAS_EAC_DENIED" 21 "COMPONENT_MIA" 22 "CRUISE_FAULT" 23 "CID_SWITCH_DISABLED" 24 "DRIVING_OFF_NAV" 25 "VEHICLE_SPEED_ABOVE_MAX" 26 "FOLLOWER_OUTPUT_INVALID" 27 "PLANNER_OUTPUT_INVALID" 28 "EPAS_ERROR_CODE" 29 "ACC_CANCEL" 30 "CAMERA_FAILSAFES" 31 "NO_ABORT";
VAL_ 994 VCLEFT_FLMapLightStatus 2 "LIGHT_FAULT" 0 "LIGHT_OFF" 1 "LIGHT_ON" 3 "LIGHT_SNA" ;
VAL_ 994 VCLEFT_FRMapLightStatus 2 "LIGHT_FAULT" 0 "LIGHT_OFF" 1 "LIGHT_ON" 3 "LIGHT_SNA" ;
VAL_ 994 VCLEFT_RLMapLightStatus 2 "LIGHT_FAULT" 0 "LIGHT_OFF" 1 "LIGHT_ON" 3 "LIGHT_SNA" ;
VAL_ 994 VCLEFT_RRMapLightStatus 2 "LIGHT_FAULT" 0 "LIGHT_OFF" 1 "LIGHT_ON" 3 "LIGHT_SNA" ;
VAL_ 994 VCLEFT_brakeLightStatus 2 "LIGHT_FAULT" 0 "LIGHT_OFF" 1 "LIGHT_ON" 3 "LIGHT_SNA" ;
VAL_ 994 VCLEFT_brakeTrailerLightStatus 2 "LIGHT_FAULT" 0 "LIGHT_OFF" 1 "LIGHT_ON" 3 "LIGHT_SNA" ;
VAL_ 994 VCLEFT_dynamicBrakeLightStatus 2 "DYNAMIC_BRAKE_LIGHT_ACTIVE_HIGH" 1 "DYNAMIC_BRAKE_LIGHT_ACTIVE_LOW" 0 "DYNAMIC_BRAKE_LIGHT_OFF" ;
VAL_ 994 VCLEFT_fogTrailerLightStatus 2 "LIGHT_FAULT" 0 "LIGHT_OFF" 1 "LIGHT_ON" 3 "LIGHT_SNA" ;
VAL_ 994 VCLEFT_frontRideHeight 128 "SNA" ;
VAL_ 994 VCLEFT_leftTurnTrailerLightStatu 2 "LIGHT_FAULT" 0 "LIGHT_OFF" 1 "LIGHT_ON" 3 "LIGHT_SNA" ;
VAL_ 994 VCLEFT_rearRideHeight 128 "SNA" ;
VAL_ 994 VCLEFT_reverseTrailerLightStatus 2 "LIGHT_FAULT" 0 "LIGHT_OFF" 1 "LIGHT_ON" 3 "LIGHT_SNA" ;
VAL_ 994 VCLEFT_rightTrnTrailerLightStatu 2 "LIGHT_FAULT" 0 "LIGHT_OFF" 1 "LIGHT_ON" 3 "LIGHT_SNA" ;
VAL_ 994 VCLEFT_tailLightStatus 2 "LIGHT_FAULT" 0 "LIGHT_OFF" 1 "LIGHT_ON" 3 "LIGHT_SNA" ;
VAL_ 994 VCLEFT_tailTrailerLightStatus 2 "LIGHT_FAULT" 0 "LIGHT_OFF" 1 "LIGHT_ON" 3 "LIGHT_SNA" ;
VAL_ 994 VCLEFT_trailerDetected 2 "TRAILER_LIGHT_DETECTION_DETECTED" 1 "TRAILER_LIGHT_DETECTION_FAULT" 3 "TRAILER_LIGHT_DETECTION_NOT_DETECTED" 0 "TRAILER_LIGHT_DETECTION_SNA" ;
VAL_ 994 VCLEFT_turnSignalStatus 2 "LIGHT_FAULT" 0 "LIGHT_OFF" 1 "LIGHT_ON" 3 "LIGHT_SNA" ;
VAL_ 995 VCRIGHT_brakeLightStatus 2 "LIGHT_FAULT" 0 "LIGHT_OFF" 1 "LIGHT_ON" 3 "LIGHT_SNA" ;
VAL_ 995 VCRIGHT_interiorTrunkLightStatus 2 "LIGHT_FAULT" 0 "LIGHT_OFF" 1 "LIGHT_ON" 3 "LIGHT_SNA" ;
VAL_ 995 VCRIGHT_rearFogLightStatus 2 "LIGHT_FAULT" 0 "LIGHT_OFF" 1 "LIGHT_ON" 3 "LIGHT_SNA" ;
VAL_ 995 VCRIGHT_reverseLightStatus 2 "LIGHT_FAULT" 0 "LIGHT_OFF" 1 "LIGHT_ON" 3 "LIGHT_SNA" ;
VAL_ 995 VCRIGHT_tailLightStatus 2 "LIGHT_FAULT" 0 "LIGHT_OFF" 1 "LIGHT_ON" 3 "LIGHT_SNA" ;
VAL_ 995 VCRIGHT_turnSignalStatus 2 "LIGHT_FAULT" 0 "LIGHT_OFF" 1 "LIGHT_ON" 3 "LIGHT_SNA" ;
VAL_ 1000 EPBR_matrixIndex 0 "AlertMatrix0" 1 "AlertMatrix1" 2 "AlertMatrix2" 3 "AlertMatrix3" 4 "AlertMatrix4";
VAL_ 1001 DAS_hazardLightRequest 0 "DAS_REQUEST_HAZARDS_OFF" 1 "DAS_REQUEST_HAZARDS_ON" 3 "DAS_REQUEST_HAZARDS_SNA" 2 "DAS_REQUEST_HAZARDS_UNUSED" ;
VAL_ 1001 DAS_headlightRequest 3 "DAS_HEADLIGHT_REQUEST_INVALID" 0 "DAS_HEADLIGHT_REQUEST_OFF" 1 "DAS_HEADLIGHT_REQUEST_ON" ;
VAL_ 1001 DAS_heaterRequest 1 "DAS_HEATER_OFF" 2 "DAS_HEATER_ON" 0 "DAS_HEATER_SNA" ;
VAL_ 1001 DAS_highLowBeamDecision 1 "DAS_HIGH_BEAM_OFF" 2 "DAS_HIGH_BEAM_ON" 3 "DAS_HIGH_BEAM_SNA" 0 "DAS_HIGH_BEAM_UNDECIDED" ;
VAL_ 1001 DAS_highLowBeamOffReason 3 "HIGH_BEAM_OFF_REASON_AMBIENT_LIGHT" 4 "HIGH_BEAM_OFF_REASON_HEAD_LIGHT" 2 "HIGH_BEAM_OFF_REASON_MOVING_RADAR_TARGET" 1 "HIGH_BEAM_OFF_REASON_MOVING_VISION_TARGET" 5 "HIGH_BEAM_OFF_REASON_SNA" 0 "HIGH_BEAM_ON" ;
VAL_ 1001 DAS_turnIndicatorRequest 3 "DAS_TURN_INDICATOR_CANCEL" 4 "DAS_TURN_INDICATOR_DEFER" 1 "DAS_TURN_INDICATOR_LEFT" 0 "DAS_TURN_INDICATOR_NONE" 2 "DAS_TURN_INDICATOR_RIGHT" ;
VAL_ 1001 DAS_turnIndicatorRequestReason 8 "DAS_ACTIVE_COMMANDED_LANE_CHANGE" 3 "DAS_ACTIVE_FORK" 9 "DAS_ACTIVE_INTERSECTION" 6 "DAS_ACTIVE_MERGE" 1 "DAS_ACTIVE_NAV_LANE_CHANGE" 2 "DAS_ACTIVE_SPEED_LANE_CHANGE" 11 "DAS_ACTIVE_SUMMMON" 5 "DAS_CANCEL_FORK" 10 "DAS_CANCEL_INTERSECTION" 4 "DAS_CANCEL_LANE_CHANGE" 7 "DAS_CANCEL_MERGE" 12 "DAS_CANCEL_SUMMMON" 0 "DAS_NONE" ;
VAL_ 1001 DAS_wiperSpeed 1 "DAS_WIPER_SPEED_1" 10 "DAS_WIPER_SPEED_10" 11 "DAS_WIPER_SPEED_11" 12 "DAS_WIPER_SPEED_12" 13 "DAS_WIPER_SPEED_13" 14 "DAS_WIPER_SPEED_14" 2 "DAS_WIPER_SPEED_2" 3 "DAS_WIPER_SPEED_3" 4 "DAS_WIPER_SPEED_4" 5 "DAS_WIPER_SPEED_5" 6 "DAS_WIPER_SPEED_6" 7 "DAS_WIPER_SPEED_7" 8 "DAS_WIPER_SPEED_8" 9 "DAS_WIPER_SPEED_9" 15 "DAS_WIPER_SPEED_INVALID" 0 "DAS_WIPER_SPEED_OFF" ;
VAL_ 1001 DAS_mirrorFoldRequest 0 "NONE" 1 "FOLD" 2 "UNFOLD" 3 "SNA" ;
VAL_ 1009 VCFRONT_DRLLeftStatus 0 "OFF" 1 "ON" 2 "FAULT" 3 "SNA";
VAL_ 1009 VCFRONT_DRLRightStatus 0 "OFF" 1 "ON" 2 "FAULT" 3 "SNA";
VAL_ 1009 VCFRONT_ambientLightingBrightnes 255 "SNA";
VAL_ 1009 VCFRONT_fogLeftStatus 0 "OFF" 1 "ON" 2 "FAULT" 3 "SNA";
VAL_ 1009 VCFRONT_fogRightStatus 0 "OFF" 1 "ON" 2 "FAULT" 3 "SNA";
VAL_ 1009 VCFRONT_hazardLightRequest 0 "NONE" 1 "BUTTON" 2 "LOCK" 3 "UNLOCK" 4 "MISLOCK" 5 "CRASH" 6 "CAR_ALARM" 7 "DAS";
VAL_ 1009 VCFRONT_highBeamLeftStatus 0 "OFF" 1 "ON" 2 "FAULT" 3 "SNA";
VAL_ 1009 VCFRONT_highBeamRightStatus 0 "OFF" 1 "ON" 2 "FAULT" 3 "SNA";
VAL_ 1009 VCFRONT_indicatorLeftRequest 0 "OFF" 1 "ACTIVE_LOW" 2 "ACTIVE_HIGH";
VAL_ 1009 VCFRONT_indicatorRightRequest 0 "OFF" 1 "ACTIVE_LOW" 2 "ACTIVE_HIGH";
VAL_ 1009 VCFRONT_lowBeamLeftStatus 0 "OFF" 1 "ON" 2 "FAULT" 3 "SNA";
VAL_ 1009 VCFRONT_lowBeamRightStatus 0 "OFF" 1 "ON" 2 "FAULT" 3 "SNA";
VAL_ 1009 VCFRONT_parkLeftStatus 0 "OFF" 1 "ON" 2 "FAULT" 3 "SNA";
VAL_ 1009 VCFRONT_parkRightStatus 0 "OFF" 1 "ON" 2 "FAULT" 3 "SNA";
VAL_ 1009 VCFRONT_sideMarkersStatus 0 "OFF" 1 "ON" 2 "FAULT" 3 "SNA";
VAL_ 1009 VCFRONT_sideRepeaterLeftStatus 0 "OFF" 1 "ON" 2 "FAULT" 3 "SNA";
VAL_ 1009 VCFRONT_sideRepeaterRightStatus 0 "OFF" 1 "ON" 2 "FAULT" 3 "SNA";
VAL_ 1009 VCFRONT_simLatchingStalk 0 "IDLE" 1 "LEFT" 2 "RIGHT" 3 "SNA";
VAL_ 1009 VCFRONT_switchLightingBrightness 255 "SNA";
VAL_ 1009 VCFRONT_turnSignalLeftStatus 0 "OFF" 1 "ON" 2 "FAULT" 3 "SNA";
VAL_ 1009 VCFRONT_turnSignalRightStatus 0 "OFF" 1 "ON" 2 "FAULT" 3 "SNA";
VAL_ 1011 UI_odometer 16777215 "SNA" ;
VAL_ 1012 APP_cameraPosition 0 "INVALID" 1 "MAIN" 2 "NARROW" 3 "FISHEYE" 4 "L_PILLAR" 5 "R_PILLAR" 6 "L_REPEATER" 7 "R_REPEATER" 8 "BACKUP";
VAL_ 1012 APP_mainCamExtPitchCal 511 "SNA";
VAL_ 1012 APP_mainCamExtYawCal 511 "SNA";
VAL_ 1012 APP_mainCalibTime 127 "SNA";
VAL_ 1012 APP_mainCalibProgress 127 "SNA";
VAL_ 1012 APP_narrowCamExtPitchCal 511 "SNA";
VAL_ 1012 APP_narrowCamExtYawCal 511 "SNA";
VAL_ 1012 APP_narrowCalibTime 127 "SNA";
VAL_ 1012 APP_narrowCalibProgress 127 "SNA";
VAL_ 1012 APP_fisheyeCamExtPitchCal 511 "SNA";
VAL_ 1012 APP_fisheyeCamExtYawCal 511 "SNA";
VAL_ 1012 APP_fisheyeCalibTime 127 "SNA";
VAL_ 1012 APP_fisheyeCalibProgress 127 "SNA";
VAL_ 1012 APP_lPillarCamExtPitchCal 511 "SNA";
VAL_ 1012 APP_lPillarCamExtYawCal 511 "SNA";
VAL_ 1012 APP_lPillarCalibTime 127 "SNA";
VAL_ 1012 APP_lPillarCalibProgress 127 "SNA";
VAL_ 1012 APP_rPillarCamExtPitchCal 511 "SNA";
VAL_ 1012 APP_rPillarCamExtYawCal 511 "SNA";
VAL_ 1012 APP_rPillarCalibTime 127 "SNA";
VAL_ 1012 APP_rPillarCalibProgress 127 "SNA";
VAL_ 1012 APP_lRepeatCamExtPitchCal 511 "SNA";
VAL_ 1012 APP_lRepeatCamExtYawCal 511 "SNA";
VAL_ 1012 APP_lRepeatCalibTime 127 "SNA";
VAL_ 1012 APP_lRepeatCalibProgress 127 "SNA";
VAL_ 1012 APP_rRepeatCamExtPitchCal 511 "SNA";
VAL_ 1012 APP_rRepeatCamExtYawCal 511 "SNA";
VAL_ 1012 APP_rRepeatCalibTime 127 "SNA";
VAL_ 1012 APP_rRepeatCalibProgress 127 "SNA";
VAL_ 1012 APP_backupCamExtPitchCal 511 "SNA";
VAL_ 1012 APP_backupCamExtYawCal 511 "SNA";
VAL_ 1012 APP_backupCalibTime 127 "SNA";
VAL_ 1012 APP_backupCalibProgress 127 "SNA";
CM_ BO_ 880 "source: onyx-m2/onyx-m2-dbc (tesla_model3.dbc)";
CM_ BO_ 881 "source: onyx-m2/onyx-m2-dbc (tesla_model3.dbc)";
CM_ BO_ 882 "source: talas9/tesla_can_signals (ModelY_ETH.compact.json)";
CM_ BO_ 883 "source: talas9/tesla_can_signals (ModelY_ETH.compact.json)";
CM_ BO_ 884 "source: talas9/tesla_can_signals (ModelY_ETH.compact.json)";
CM_ BO_ 886 "source: joshwardell/model3dbc (Model3CAN.dbc)";
CM_ BO_ 888 "source: onyx-m2/onyx-m2-dbc (tesla_model3.dbc)";
CM_ BO_ 890 "source: onyx-m2/onyx-m2-dbc (tesla_model3.dbc)";
CM_ BO_ 893 "source: joshwardell/model3dbc (Model3CAN.dbc)";
CM_ BO_ 894 "source: onyx-m2/onyx-m2-dbc (tesla_model3.dbc)";
CM_ BO_ 895 "source: onyx-m2/onyx-m2-dbc (tesla_model3.dbc)";
CM_ BO_ 897 "source: joshwardell/model3dbc (Model3CAN.dbc)";
CM_ BO_ 899 "source: joshwardell/model3dbc (Model3CAN.dbc)";
CM_ BO_ 900 "source: onyx-m2/onyx-m2-dbc (tesla_model3.dbc)";
CM_ BO_ 904 "source: talas9/tesla_can_signals (ModelY_ETH.compact.json)";
CM_ BO_ 905 "source: joshwardell/model3dbc (Model3CAN.dbc)";
CM_ BO_ 909 "source: onyx-m2/onyx-m2-dbc (tesla_model3.dbc)";
CM_ BO_ 913 "source: onyx-m2/onyx-m2-dbc (tesla_model3.dbc)";
CM_ BO_ 914 "source: joshwardell/model3dbc (Model3CAN.dbc)";
CM_ BO_ 915 "source: onyx-m2/onyx-m2-dbc (tesla_model3.dbc)";
CM_ BO_ 917 "source: joshwardell/model3dbc (Model3CAN.dbc)";
CM_ BO_ 918 "source: joshwardell/model3dbc (Model3CAN.dbc)";
CM_ BO_ 921 "source: joshwardell/model3dbc (Model3CAN.dbc)";
CM_ BO_ 923 "source: commaai/opendbc (tesla_model3_party.dbc)";
CM_ BO_ 925 "source: joshwardell/model3dbc (Model3CAN.dbc)";
CM_ BO_ 926 "source: onyx-m2/onyx-m2-dbc (tesla_model3.dbc)";
CM_ BO_ 927 "source: onyx-m2/onyx-m2-dbc (tesla_model3.dbc)";
CM_ BO_ 929 "source: joshwardell/model3dbc (Model3CAN.dbc)";
CM_ BO_ 930 "source: onyx-m2/onyx-m2-dbc (tesla_model3.dbc)";
CM_ BO_ 932 "source: onyx-m2/onyx-m2-dbc (tesla_model3.dbc)";
CM_ BO_ 933 "source: onyx-m2/onyx-m2-dbc (tesla_model3.dbc)";
CM_ BO_ 937 "source: onyx-m2/onyx-m2-dbc (tesla_model3.dbc)";
CM_ BO_ 938 "source: onyx-m2/onyx-m2-dbc (tesla_model3.dbc)";
CM_ BO_ 941 "source: onyx-m2/onyx-m2-dbc (tesla_model3.dbc)";
CM_ BO_ 945 "source: onyx-m2/onyx-m2-dbc (tesla_model3.dbc)";
CM_ BO_ 947 "source: joshwardell/model3dbc (Model3CAN.dbc)";
CM_ BO_ 949 "source: onyx-m2/onyx-m2-dbc (tesla_model3.dbc)";
CM_ BO_ 950 "source: joshwardell/model3dbc (Model3CAN.dbc)";
CM_ BO_ 952 "source: onyx-m2/onyx-m2-dbc (tesla_model3.dbc)";
CM_ BO_ 953 "source: talas9/tesla_can_signals (ModelY_ETH.compact.json)";
CM_ BO_ 955 "source: joshwardell/model3dbc (Model3CAN.dbc)";
CM_ BO_ 958 "source: onyx-m2/onyx-m2-dbc (tesla_model3.dbc)";
CM_ BO_ 960 "source: talas9/tesla_can_signals (ModelY_ETH.compact.json)";
CM_ BO_ 962 "source: joshwardell/model3dbc (Model3CAN.dbc)";
CM_ BO_ 963 "source: joshwardell/model3dbc (Model3CAN.dbc)";
CM_ BO_ 964 "source: onyx-m2/onyx-m2-dbc (tesla_model3.dbc)";
CM_ BO_ 965 "source: talas9/tesla_can_signals (ModelY_ETH.compact.json)";
CM_ BO_ 968 "source: onyx-m2/onyx-m2-dbc (tesla_model3.dbc)";
CM_ BO_ 969 "source: onyx-m2/onyx-m2-dbc (tesla_model3.dbc)";
CM_ BO_ 970 "source: talas9/tesla_can_signals (ModelY_ETH.compact.json)";
CM_ BO_ 973 "source: onyx-m2/onyx-m2-dbc (tesla_model3.dbc)";
CM_ BO_ 977 "source: talas9/tesla_can_signals (ModelY_ETH.compact.json)";
CM_ BO_ 978 "source: joshwardell/model3dbc (Model3CAN.dbc)";
CM_ BO_ 979 "source: onyx-m2/onyx-m2-dbc (tesla_model3.dbc)";
CM_ BO_ 981 "source: onyx-m2/onyx-m2-dbc (tesla_model3.dbc)";
CM_ BO_ 984 "source: joshwardell/model3dbc (Model3CAN.dbc)";
CM_ BO_ 985 "source: joshwardell/model3dbc (Model3CAN.dbc)";
CM_ BO_ 986 "source: onyx-m2/onyx-m2-dbc (tesla_model3.dbc)";
CM_ BO_ 990 "source: onyx-m2/onyx-m2-dbc (tesla_model3.dbc)";
CM_ BO_ 994 "source: joshwardell/model3dbc (Model3CAN.dbc)";
CM_ BO_ 995 "source: joshwardell/model3dbc (Model3CAN.dbc)";
CM_ BO_ 997 "source: onyx-m2/onyx-m2-dbc (tesla_model3.dbc)";
CM_ BO_ 1000 "source: onyx-m2/onyx-m2-dbc (tesla_model3.dbc)";
CM_ BO_ 1001 "source: joshwardell/model3dbc (Model3CAN.dbc)";
CM_ BO_ 1009 "source: onyx-m2/onyx-m2-dbc (tesla_model3.dbc)";
CM_ BO_ 1010 "source: joshwardell/model3dbc (Model3CAN.dbc)";
CM_ BO_ 1011 "source: joshwardell/model3dbc (Model3CAN.dbc)";
CM_ BO_ 1012 "source: onyx-m2/onyx-m2-dbc (tesla_model3.dbc)";
